VERSION "Version"

NS_ :

BS_:

BU_: IID IDC CCU Tester CCURT1 CCURT2 CCU3 CCU4 AVAS LCUFL LCUFR LCURL LCURR ZCUF ZCUL ZCUR ZCUT PADS MFS VDC ITS BCB IPS DCDC PCU EOP DCU BMC SRS EPS RBM IBCS AMP WHUD ADC RADARRR RADARRL RADARFR RADARFL RPC IFC RADARFRT RADARR HDMAP SBM WCM ETC TBOX DSM FLPDM FRPDM RLPDM RRPDM

BO_ 295 CCU_10: 64 CCU
 SG_ IL_IALFunctionCfgSt : 215|1@0+ (1,0) [0|1] ""  IDC
 SG_ IL_IALWorkSt : 214|1@0+ (1,0) [0|1] ""  IDC
 SG_ IL_IALBrightnessSetSt : 212|4@0+ (1,0) [0|15] ""  IDC
 SG_ IL_IALDriverModeCfgSt : 208|1@0+ (1,0) [0|1] ""  IDC
 SG_ IL_IALColorSetSt : 223|8@0+ (1,0) [0|255] ""  IDC
 SG_ IL_IALMusicModeCfgSt : 231|1@0+ (1,0) [0|1] ""  IDC
 SG_ IALVoiceModeCfgSt : 230|1@0+ (1,0) [0|1] ""  IDC

BO_ 400 CCU_MFS_1: 32 CCU
 SG_ UINM_DrvReqShft : 31|4@0+ (1,0) [0|15] ""  IDC
 SG_ UINM_TurnLightSwSt : 43|3@0+ (1,0) [0|7] ""  CCU,IDC
 SG_ UINM_FrontWiperSwSt : 55|3@0+ (1,0) [0|7] ""  CCU,IDC
 SG_ UINM_FrontWasherSwSt : 48|1@0+ (1,0) [0|1] ""  CCU,IDC

BO_ 615 CCU_BCS_1_C: 64 CCU
 SG_ BCS_1_C_Dummy20 : 48|1@0+ (1,0) [0|0] ""  IDC
 SG_ BCS_1_C_Dummy19 : 66|1@0+ (1,0) [0|0] ""  IDC
 SG_ BCS_RLWheelRotatedDirection : 65|1@0+ (1,0) [0|1] ""  ADC,IDC,IFC
 SG_ BCS_RLWheelSpd : 63|13@0+ (0.05625,0) [0|240] "km/h"  ADC,DCU,IDC,IFC,ZCUF,ZCUT
 SG_ BCS_1_C_Dummy14 : 34|1@0+ (1,0) [0|0] ""  IDC
 SG_ BCS_1_C_Dummy18 : 50|1@0+ (1,0) [0|0] ""  IDC
 SG_ BCS_1_C_Dummy17 : 32|1@0+ (1,0) [0|0] ""  IDC
 SG_ BCS_RRWheelSpdEdgesSum : 131|12@0+ (1,0) [0|4095] ""  ADC,IDC,IFC,ZCUF,ZCUT
 SG_ BCS_FRWheelSpdEdgesSum : 107|12@0+ (1,0) [0|4095] ""  ADC,IDC,IFC,ZCUF,ZCUT
 SG_ BCS_RRWheelRotatedDirection : 81|1@0+ (1,0) [0|1] ""  ADC,IDC,IFC
 SG_ BCS_RRWheelSpd : 79|13@0+ (0.05625,0) [0|240] "km/h"  ADC,DCU,IDC,IFC,ZCUF,ZCUT
 SG_ BCS_FRWheelRotatedDirection : 49|1@0+ (1,0) [0|1] ""  ADC,IDC,IFC
 SG_ BCS_FRWheelSpd : 47|13@0+ (0.05625,0) [0|240] "km/h"  ADC,DCU,IDC,IFC,ZCUF,ZCUT
 SG_ BCS_FLWheelRotatedDirection : 33|1@0+ (1,0) [0|1] ""  ADC,IDC,IFC
 SG_ BCS_FLWheelSpd : 31|13@0+ (0.05625,0) [0|240] "km/h"  ADC,DCU,IDC,IFC,ZCUF,ZCUT
 SG_ BCS_1_C_Dummy16 : 95|1@0+ (1,0) [0|0] ""  ADC,DCU,IDC,IFC,SBM,ZCUF,ZCUR,ZCUT
 SG_ BCS_1_C_Dummy10 : 64|1@0+ (1,0) [0|1] ""  ADC,DCU,IDC,IFC,SBM,ZCUF,ZCUR,ZCUT
 SG_ BCS_1_C_Dummy15 : 271|4@0+ (1,0) [0|0] ""  ADC,DCU,IDC,IFC,SBM,ZCUF,ZCUR,ZCUT
 SG_ BCS_1_C_Dummy13 : 80|1@0+ (1,0) [0|1] ""  ZCUF,ZCUT,ZCUR,DCU,SBM,ADC,IFC,IDC
 SG_ BCS_1_C_Dummy12 : 90|3@0+ (1,0) [0|0] ""  ZCUF,ZCUT,ZCUR,DCU,SBM,ADC,IFC,IDC
 SG_ BCS_1_C_Dummy11 : 82|1@0+ (1,0) [0|1] ""  ZCUF,ZCUT,ZCUR,DCU,SBM,ADC,IFC,IDC
 SG_ BCS_1_C_Dummy9 : 150|1@0+ (1,0) [0|0] ""  ZCUF,ZCUT,ZCUR,DCU,SBM,ADC,IFC,IDC
 SG_ BCS_1_C_Dummy8 : 148|5@0+ (1,0) [0|0] ""  ZCUF,ZCUT,ZCUR,DCU,SBM,ADC,IFC,IDC
 SG_ BCS_1_C_Dummy7 : 159|6@0+ (1,0) [0|0] ""  ZCUF,ZCUT,ZCUR,DCU,SBM,ADC,IFC,IDC
 SG_ BCS_1_C_Dummy6 : 164|41@0+ (1,0) [0|0] ""  ZCUF,ZCUT,ZCUR,DCU,SBM,ADC,IFC,IDC
 SG_ BCS_1_C_Dummy5 : 203|60@0+ (1,0) [0|1.15292150460685E+018] ""  ZCUF,ZCUT,ZCUR,DCU,SBM,ADC,IFC,IDC
 SG_ BCS_1_C_Dummy4 : 279|48@0+ (1,0) [0|0] ""  ZCUF,ZCUR,ZCUT,DCU,SBM,ADC,IFC,IDC
 SG_ BCS_1_C_Dummy3 : 327|64@0+ (1,0) [0|0] ""  ZCUF,ZCUR,ZCUT,SBM,DCU,ADC,IFC,IDC
 SG_ BCS_1_C_Dummy2 : 391|64@0+ (1,0) [0|0] ""  ZCUF,ZCUR,ZCUT,DCU,SBM,ADC,IFC,IDC
 SG_ BCS_1_C_Dummy1 : 455|64@0+ (1,0) [0|0] ""  ZCUT,ZCUF,ZCUR,DCU,SBM,ADC,IFC,IDC
 SG_ BCS_1_Counter : 23|8@0+ (1,0) [0|255] ""  ZCUF,ZCUT,IDC,ADC,IFC
 SG_ BCS_1_CRC : 7|16@0+ (1,0) [0|65535] ""  ZCUF,ZCUT,IDC,ADC,IFC
 SG_ BCS_FLWheelSpdEdgesSumVD : 151|1@0+ (1,0) [0|1] ""  IFC,IDC,ADC
 SG_ BCS_FLWheelSpdEdgesSum : 103|12@0+ (1,0) [0|4095] ""  ZCUF,ZCUT,IFC,IDC,ADC
 SG_ BCS_HHCErrSt : 94|1@0+ (1,0) [0|1] ""  IDC,IFC
 SG_ BCS_HDCCtrlSt : 93|2@0+ (1,0) [0|3] ""  DCU,IDC,ADC,IFC
 SG_ BCS_HDCErrSt : 91|1@0+ (1,0) [0|1] ""  IDC,ADC,IFC
 SG_ BCS_RLWheelSpdEdgesSum : 127|12@0+ (1,0) [0|4095] ""  ZCUF,ZCUT,IDC,ADC,IFC
 SG_ BCS_RLWheelSpdEdgesSumVD : 149|1@0+ (1,0) [0|1] ""  IDC,ADC,IFC
 SG_ BCS_VDCOff : 153|1@0+ (1,0) [0|1] ""  IDC,ADC,IFC
 SG_ BCS_AVHSt : 152|1@0+ (1,0) [0|1] ""  ZCUR,DCU,IDC,ADC,IFC,SBM
 SG_ BCS_AVHStandby : 167|1@0+ (1,0) [0|1] ""  IDC,IFC
 SG_ BCS_AVHAvailable : 166|1@0+ (1,0) [0|1] ""  IDC,IFC
 SG_ BCS_TCSOff : 165|1@0+ (1,0) [0|1] ""  IDC,ADC,IFC
 SG_ BCS_ESPFuncResp : 267|2@0+ (1,0) [0|3] ""  IDC
 SG_ BCS_HDCFuncResp : 265|2@0+ (1,0) [0|3] ""  IDC

BO_ 352 CCU_BCS_2_C: 64 CCU
 SG_ BCS_2_C_Dummy11 : 199|36@0+ (1,0) [0|0] ""  IDC
 SG_ IPB_BrakePedalSt : 227|2@0+ (1,0) [0|3] ""  ADC,IDC,IFC,ZCUF,ZCUT
 SG_ BCS_2_C_Dummy10 : 33|2@0+ (1,0) [0|0] ""  ITS,AMP,ZCUL,ZCUR,MFS,PCU,DCU,ZCUF,ZCUT,IDC,ADC,IFC
 SG_ BCS_2_C_Dummy9 : 46|1@0+ (1,0) [0|0] ""  ITS,AMP,ZCUL,ZCUR,MFS,PCU,DCU,ZCUF,ZCUT,IDC,ADC,IFC
 SG_ BCS_2_C_Dummy8 : 40|17@0+ (1,0) [0|0] ""  ITS,AMP,ZCUL,ZCUR,MFS,PCU,DCU,ZCUF,ZCUT,IDC,ADC,IFC
 SG_ BCS_2_C_Dummy7 : 71|64@0+ (1,0) [0|0] ""  ITS,AMP,ZCUL,ZCUR,MFS,PCU,DCU,ZCUF,ZCUT,IDC,ADC,IFC
 SG_ BCS_2_C_Dummy6 : 135|64@0+ (1,0) [0|0] ""  ITS,AMP,ZCUL,ZCUR,MFS,PCU,DCU,ZCUF,ZCUT,IDC,ADC,IFC
 SG_ BCS_2_C_Dummy5 : 225|26@0+ (1,0) [0|67108863] ""  ITS,AMP,ZCUL,ZCUR,MFS,PCU,DCU,ZCUF,ZCUT,IDC,ADC,IFC
 SG_ BCS_2_C_Dummy4 : 263|64@0+ (1,0) [0|0] ""  ITS,AMP,ZCUL,ZCUR,MFS,PCU,DCU,ZCUF,ZCUT,IDC,ADC,IFC
 SG_ BCS_2_C_Dummy3 : 327|64@0+ (1,0) [0|0] ""  ITS,AMP,ZCUL,ZCUR,MFS,PCU,DCU,ZCUF,ZCUT,IDC,ADC,IFC
 SG_ BCS_2_C_Dummy2 : 391|64@0+ (1,0) [0|0] ""  IDC,ITS,AMP,ZCUL,ZCUR,MFS,PCU,DCU,ZCUF,ZCUT,ADC,IFC
 SG_ BCS_2_C_Dummy1 : 455|64@0+ (1,0) [0|0] ""  ITS,AMP,ZCUL,ZCUR,MFS,PCU,DCU,ZCUF,ZCUT,IDC,ADC,IFC
 SG_ BCS_2_Counter : 23|8@0+ (1,0) [0|255] ""  ZCUF,ZCUL,ZCUR,ZCUT,DCU,IDC,ADC,IFC
 SG_ BCS_2_CRC : 7|16@0+ (1,0) [0|65535] ""  DCU,IDC,ZCUF,ZCUL,ZCUR,ZCUT,ADC,IFC
 SG_ BCS_VehSpd : 31|13@0+ (0.05625,0) [0|240] "km/h"  ITS,AMP,ZCUF,ZCUL,ZCUR,ZCUT,MFS,PCU,DCU,IDC,ADC,IFC
 SG_ BCS_VehSpdVD : 34|1@0+ (1,0) [0|1] ""  ZCUF,ZCUL,ZCUR,ZCUT,MFS,PCU,IDC,ADC,IFC
 SG_ BCS_EBDFaultSt : 47|1@0+ (1,0) [0|1] ""  ZCUF,ZCUT,IDC,ADC,IFC
 SG_ BCS_ABSFaultSt : 45|1@0+ (1,0) [0|1] ""  ZCUF,ZCUT,IDC,ADC,IFC
 SG_ BCS_TCSActiveSt : 44|1@0+ (1,0) [0|1] ""  ZCUF,ZCUT,DCU,IDC,ADC,IFC
 SG_ BCS_TCSFaultSt : 43|1@0+ (1,0) [0|1] ""  ZCUF,ZCUT,IDC,ADC,IFC
 SG_ BCS_VDCActiveSt : 42|1@0+ (1,0) [0|1] ""  ZCUF,ZCUT,IDC,ADC,IFC
 SG_ BCS_VDCFaultSt : 41|1@0+ (1,0) [0|1] ""  ZCUF,ZCUT,IDC,ADC,IFC

BO_ 611 CCU_BCS_3_C: 64 CCU
 SG_ IPB_BrkPedalModesetSt : 254|7@0+ (1,0) [0|100] ""  IDC
 SG_ BCS_3_C_Dummy10 : 31|54@0+ (1,0) [0|0] ""  IDC,IFC,ADC
 SG_ BCS_3_C_Dummy9 : 87|64@0+ (1,0) [0|1.84467440737096E+019] ""  IDC,IFC,ADC
 SG_ BCS_3_C_Dummy8 : 151|64@0+ (1,0) [0|0] ""  IFC,IDC,ADC
 SG_ BCS_3_C_Dummy7 : 215|20@0+ (1,0) [0|1048575] ""  IDC,IFC,ADC
 SG_ BCS_3_C_Dummy6 : 235|2@0+ (1,0) [0|0] ""  IFC,IDC,ADC
 SG_ BCS_3_C_Dummy5 : 244|6@0+ (1,0) [0|63] ""  IDC,IFC,ADC
 SG_ BCS_3_C_Dummy4 : 263|64@0+ (1,0) [0|0] ""  IFC,IDC,ADC
 SG_ BCS_3_C_Dummy3 : 327|64@0+ (1,0) [0|0] ""  IDC,IFC,ADC
 SG_ BCS_3_C_Dummy2 : 391|64@0+ (1,0) [0|0] ""  IFC,IDC,ADC
 SG_ BCS_3_C_Dummy1 : 455|64@0+ (1,0) [0|0] ""  IFC,IDC,ADC
 SG_ BCS_3_CRC : 7|16@0+ (1,0) [0|65535] ""  IDC
 SG_ BCS_3_Counter : 23|8@0+ (1,0) [0|255] ""  IDC
 SG_ IPB_BrkPedalModeCfgSt : 73|2@0+ (1,0) [0|3] ""  IDC
 SG_ IPB_InputRodStrokeSt : 227|1@0+ (1,0) [0|1] ""  IDC,ADC,IFC
 SG_ IBCS_SystemSt : 226|3@0+ (1,0) [0|7] ""  IDC,ADC,IFC
 SG_ IBCS_FWAWarning : 239|2@0+ (1,0) [0|3] ""  IDC
 SG_ IBCS_BrakeFluidWarning : 237|2@0+ (1,0) [0|3] ""  IDC
 SG_ IPB_CSTSt : 233|2@0+ (1,0) [0|3] ""  IDC
 SG_ IBCS_TwoFoot_DriveWarning : 247|1@0+ (1,0) [0|1] ""  IDC
 SG_ BCS_ESPMode : 246|2@0+ (1,0) [0|3] ""  IDC

BO_ 886 CCU_BCS_5_C: 32 CCU
 SG_ BCS_TPMSResetSt : 31|2@0+ (1,0) [0|3] ""  IDC
 SG_ BCS_TPMSWarningLamp : 29|1@0+ (1,0) [0|1] ""  IDC
 SG_ BCS_TPMSSysErrorSt : 28|1@0+ (1,0) [0|1] ""  IDC
 SG_ BCS_TPMSFLTyrePreWarn : 27|1@0+ (1,0) [0|1] ""  IDC
 SG_ BCS_TPMSFRTyrePreWarn : 26|1@0+ (1,0) [0|1] ""  IDC
 SG_ BCS_AVHSoftSwctrlst : 25|2@0+ (1,0) [0|3] ""  IDC
 SG_ BCS_TPMSRLTyrePreWarn : 39|1@0+ (1,0) [0|1] ""  IDC
 SG_ BCS_TPMSRRTyrePreWarn : 38|1@0+ (1,0) [0|1] ""  IDC

BO_ 618 CCU_EPB_1: 32 CCU
 SG_ EPB_DragMode : 123|2@0+ (1,0) [0|3] ""  IBCS,IDC,RBM,ZCUF
 SG_ EPB_1_Dummy6 : 31|3@0+ (1,0) [0|0] ""  ZCUF,ZCUR,SRS,ADC,RBM,IBCS,IDC
 SG_ EPB_1_Dummy5 : 33|18@0+ (1,0) [0|0] ""  ZCUF,ZCUR,SRS,ADC,RBM,IBCS,IDC
 SG_ EPB_1_Dummy4 : 63|64@0+ (1,0) [0|0] ""  ZCUF,ZCUR,SRS,ADC,RBM,IBCS,IDC
 SG_ EPB_1_Dummy3 : 121|6@0+ (1,0) [0|63] ""  ZCUF,ZCUR,SRS,ADC,RBM,IBCS,IDC
 SG_ EPB_1_Dummy2 : 129|58@0+ (1,0) [0|0] ""  ZCUF,ZCUR,SRS,ADC,RBM,IBCS,IDC
 SG_ EPB_1_Dummy1 : 199|64@0+ (1,0) [0|0] ""  ZCUF,ZCUR,SRS,ADC,RBM,IBCS,IDC
 SG_ EPB_1_CRC : 7|16@0+ (1,0) [0|65535] ""  ZCUF,ZCUR,RBM,IBCS,IDC,ADC
 SG_ EPB_1_Counter : 23|8@0+ (1,0) [0|255] ""  ZCUF,ZCUR,RBM,IBCS,IDC,ADC
 SG_ EPB_SysSt : 28|3@0+ (1,0) [0|7] ""  SRS,RBM,IBCS,IDC,ADC
 SG_ EPB_SysStIndReq : 25|2@0+ (1,0) [0|3] ""  RBM,IBCS,IDC
 SG_ EPB_FailSt : 39|1@0+ (1,0) [0|1] ""  SRS,RBM,IBCS,IDC,ADC
 SG_ EPB_SysWarnIndReq : 38|2@0+ (1,0) [0|3] ""  RBM,IBCS,IDC
 SG_ EPB_SysAudWarnReq : 36|3@0+ (1,0) [0|7] ""  RBM,IBCS,IDC
 SG_ EPB_SysDispMsgReq : 127|4@0+ (1,0) [0|15] ""  RBM,IBCS,IDC
 SG_ EPB_StpOnBrkToRelParkBrkIndOn : 131|2@0+ (1,0) [0|3] ""  IDC

BO_ 939 CCU_SRS_2: 32 CCU
 SG_ SRS_2_Dummy5 : 24|1@0+ (1,0) [0|0] ""  IDC
 SG_ SRS_2_Dummy4 : 35|28@0+ (1,0) [0|268435455] ""  IDC
 SG_ SRS_2_Dummy3 : 71|64@0+ (1,0) [0|0] ""  IDC
 SG_ SRS_2_Dummy2 : 135|64@0+ (1,0) [0|0] ""  IDC
 SG_ SRS_2_Dummy1 : 199|64@0+ (1,0) [0|0] ""  IDC
 SG_ SRS_2_CRC : 7|16@0+ (1,0) [0|65535] ""  IDC
 SG_ SRS_2_Counter : 23|8@0+ (1,0) [0|255] ""  IDC
 SG_ SRS_PsngrSeatBeltSt : 31|2@0+ (1,0) [0|3] ""  IDC
 SG_ SRS_DriverSeatBeltSt : 29|2@0+ (1,0) [0|3] ""  IDC
 SG_ SRS_RearLeftSeatBeltSt : 27|2@0+ (1,0) [0|3] ""  IDC
 SG_ SRS_AirbagFaultSt : 25|1@0+ (1,0) [0|1] ""  IDC
 SG_ SRS_RearRightSeatBeltSt : 39|2@0+ (1,0) [0|3] ""  IDC
 SG_ SRS_RearMiddleSeatBeltSt : 37|2@0+ (1,0) [0|3] ""  IDC

BO_ 368 CCU_DCU_1: 64 CCU
 SG_ DCU_TorqAct : 169|13@0+ (0.2,-819) [-819|819] "Nm"  CCU,CCURT1,VDC,IDC

BO_ 864 CCU_DCU_2: 64 CCU
 SG_ DCU_2_Dummy10 : 95|5@0+ (1,0) [0|0] ""  IDC
 SG_ DCU_SysTempOvrInd : 90|1@0+ (1,0) [0|1] ""  IDC
 SG_ DCU_2_Dummy9 : 31|64@0+ (1,0) [0|1.84467440737096E+019] ""  IDC
 SG_ DCU_2_Dummy8 : 89|15@0+ (1,0) [0|32767] ""  IDC
 SG_ DCU_2_Dummy7 : 105|17@0+ (1,0) [0|0] ""  IDC
 SG_ DCU_2_Dummy6 : 131|60@0+ (1,0) [0|0] ""  IDC
 SG_ DCU_2_Dummy5 : 199|64@0+ (1,0) [0|0] ""  IDC
 SG_ DCU_2_Dummy4 : 263|64@0+ (1,0) [0|0] ""  IDC
 SG_ DCU_2_Dummy3 : 327|64@0+ (1,0) [0|0] ""  IDC
 SG_ DCU_2_Dummy2 : 391|64@0+ (1,0) [0|0] ""  IDC
 SG_ DCU_2_Dummy1 : 455|64@0+ (1,0) [0|0] ""  IDC
 SG_ DCU_Err2NoticeFlag : 132|1@0+ (1,0) [0|1] ""  IDC
 SG_ DCU_ErrNotice : 135|3@0+ (1,0) [0|7] ""  IDC
 SG_ DCU_ErrNoticeOperationFlag : 120|1@0+ (1,0) [0|1] ""  IDC
 SG_ DCU_2_Counter : 23|8@0+ (1,0) [0|255] ""  IDC
 SG_ DCU_2_CRC : 7|16@0+ (1,0) [0|65535] ""  IDC
 SG_ DCU_FaultLampInd : 106|1@0+ (1,0) [0|1] ""  IDC

BO_ 872 CCU_IPS_2: 64 CCU
 SG_ IPS_2_Dummy10 : 73|2@0+ (1,0) [0|0] ""  IDC
 SG_ IPS_2_Dummy9 : 31|26@0+ (1,0) [0|0] ""  IDC
 SG_ IPS_2_Dummy8 : 52|27@0+ (1,0) [0|0] ""  IDC
 SG_ IPS_2_Dummy7 : 87|62@0+ (1,0) [0|4.61168601842739E+018] ""  IDC
 SG_ IPS_2_Dummy6 : 136|49@0+ (1,0) [0|0] ""  IDC
 SG_ IPS_2_Dummy5 : 196|61@0+ (1,0) [0|2.30584300921369E+018] ""  IDC
 SG_ IPS_2_Dummy4 : 263|64@0+ (1,0) [0|0] ""  IDC
 SG_ IPS_2_Dummy3 : 327|64@0+ (1,0) [0|0] ""  IDC
 SG_ IPS_2_Dummy2 : 391|64@0+ (1,0) [0|0] ""  IDC
 SG_ IPS_2_Dummy1 : 455|64@0+ (1,0) [0|0] ""  IDC
 SG_ IPS_OBCFaultLampIndOperationFlag : 197|1@0+ (1,0) [0|1] ""  IDC
 SG_ IPS_DCDCFaultLampIndFlag : 198|1@0+ (1,0) [0|1] ""  IDC
 SG_ IPS_DCDCFaultLampIndOperationFla : 199|1@0+ (1,0) [0|1] ""  IDC
 SG_ IPS_2_CRC : 7|16@0+ (1,0) [0|65535] ""  IDC
 SG_ IPS_2_Counter : 23|8@0+ (1,0) [0|255] ""  IDC
 SG_ IPS_DCDCFaultLampInd : 53|1@0+ (1,0) [0|1] ""  IDC
 SG_ IPS_OBCFaultLampInd : 137|1@0+ (1,0) [0|1] ""  IDC

BO_ 880 CCU_ITS_1: 64 CCU
 SG_ ITS_MotorPumpSt : 31|2@0+ (1,0) [0|3] ""  IDC,ADC
 SG_ ITS_FanStpSpdErr : 29|1@0+ (1,0) [0|1] ""  IDC
 SG_ ITS_HeaterPumpSt : 25|2@0+ (1,0) [0|3] ""  IDC
 SG_ ITS_EcvSt : 33|2@0+ (1,0) [0|3] ""  IDC
 SG_ ITS_BatteryPumpSt : 46|2@0+ (1,0) [0|3] ""  IDC
 SG_ ITS_MotorInletTempErr : 102|1@0+ (1,0) [0|1] ""  IDC
 SG_ ITS_BatteryInletTempErr : 101|1@0+ (1,0) [0|1] ""  IDC
 SG_ ITS_ChillerInletTempErr : 100|1@0+ (1,0) [0|1] ""  IDC
 SG_ ITS_SolenoidErr : 98|1@0+ (1,0) [0|1] ""  IDC

BO_ 824 VCU_2: 64 CCU
 SG_ VCU_2_Dummy32 : 136|1@0+ (1,0) [0|0] ""  IDC
 SG_ VCU_HVAC_PTCdelayEn : 33|1@0+ (1,0) [0|1] ""  CCURT2,IDC
 SG_ VCU_2_Dummy1 : 455|64@0+ (1,0) [0|0] ""  AMP,DCDC,EOP,IPS,ITS,ZCUF,ZCUT,BMC,ZCUR,ADC,IFC,SBM,TBOX,DCU,CCURT2,IDC
 SG_ VCU_2_Dummy30 : 32|1@0+ (1,0) [0|1] ""  AMP,DCDC,EOP,IPS,ITS,BMC,ZCUF,ZCUR,ZCUT,ADC,IFC,SBM,TBOX,DCU,CCURT2,IDC
 SG_ VCU_2_Dummy29 : 41|1@0+ (1,0) [0|0] ""  AMP,DCDC,EOP,IPS,ITS,BMC,ZCUF,ZCUR,ZCUT,ADC,IFC,SBM,DCU,TBOX,CCURT2,IDC
 SG_ VCU_2_Dummy28 : 49|2@0+ (1,0) [0|0] ""  AMP,DCDC,EOP,IPS,ITS,BMC,ZCUF,ZCUR,ZCUT,ADC,IFC,SBM,TBOX,DCU,CCURT2,IDC
 SG_ VCU_2_Dummy27 : 60|11@0+ (1,0) [0|0] ""  AMP,DCDC,EOP,IPS,ITS,BMC,ZCUF,ZCUR,ZCUT,ADC,IFC,SBM,TBOX,DCU,CCURT2,IDC
 SG_ VCU_2_Dummy26 : 75|8@0+ (1,0) [0|0] ""  AMP,DCDC,EOP,IPS,ITS,BMC,ZCUF,ZCUR,ZCUT,ADC,IFC,SBM,TBOX,DCU,CCURT2,IDC
 SG_ VCU_2_Dummy25 : 97|1@0+ (1,0) [0|0] ""  AMP,DCDC,EOP,IPS,ITS,BMC,ZCUF,ZCUR,ZCUT,ADC,IFC,SBM,DCU,TBOX,CCURT2,IDC
 SG_ VCU_2_Dummy24 : 122|5@0+ (1,0) [0|0] ""  BMC,AMP,DCDC,EOP,IPS,ITS,ZCUF,ZCUR,ZCUT,ADC,IFC,SBM,TBOX,DCU,CCURT2,IDC
 SG_ VCU_2_Dummy23 : 147|2@0+ (1,0) [0|3] ""  AMP,DCDC,EOP,IPS,ITS,BMC,ZCUF,ZCUR,ZCUT,ADC,IFC,SBM,TBOX,DCU,CCURT2,IDC
 SG_ VCU_2_Dummy22 : 163|1@0+ (1,0) [0|0] ""  AMP,DCDC,EOP,IPS,ITS,BMC,ZCUF,ZCUR,ZCUT,ADC,IFC,SBM,TBOX,DCU,CCURT2,IDC
 SG_ VCU_2_Dummy21 : 171|5@0+ (1,0) [0|0] ""  AMP,DCDC,EOP,IPS,ITS,BMC,ZCUF,ZCUR,ZCUT,ADC,IFC,SBM,TBOX,DCU,CCURT2,IDC
 SG_ VCU_2_Dummy20 : 196|3@0+ (1,0) [0|0] ""  AMP,DCDC,EOP,IPS,ITS,BMC,ZCUF,ZCUR,ZCUT,ADC,IFC,SBM,TBOX,DCU,CCURT2,IDC
 SG_ VCU_2_Dummy19 : 207|4@0+ (1,0) [0|0] ""  AMP,DCDC,EOP,IPS,ITS,BMC,ZCUF,ZCUR,ZCUT,ADC,IFC,SBM,TBOX,DCU,CCURT2,IDC
 SG_ VCU_2_Dummy18 : 208|1@0+ (1,0) [0|0] ""  AMP,DCDC,EOP,IPS,ITS,BMC,ZCUF,ZCUR,ZCUT,ADC,IFC,SBM,TBOX,DCU,CCURT2,IDC
 SG_ VCU_2_Dummy17 : 220|1@0+ (1,0) [0|0] ""  AMP,DCDC,EOP,IPS,ITS,BMC,ZCUF,ZCUR,ZCUT,ADC,IFC,SBM,TBOX,DCU,CCURT2,IDC
 SG_ VCU_2_Dummy16 : 216|3@0+ (1,0) [0|0] ""  AVAS,DCDC,EOP,IPS,ITS,BMC,ZCUF,ZCUR,ZCUT,ADC,IFC,SBM,TBOX,DCU,CCURT2,IDC
 SG_ VCU_2_Dummy15 : 226|3@0+ (1,0) [0|0] ""  AMP,DCDC,EOP,IPS,ITS,BMC,ZCUF,ZCUR,ZCUT,ADC,IFC,SBM,TBOX,DCU,CCURT2,IDC
 SG_ VCU_2_Dummy14 : 247|6@0+ (1,0) [0|0] ""  EOP,DCDC,AMP,IPS,ITS,BMC,ZCUF,ZCUR,ZCUT,ADC,IFC,SBM,TBOX,DCU,CCURT2,IDC
 SG_ VCU_2_Dummy13 : 260|1@0+ (1,0) [0|0] ""  AMP,DCDC,EOP,IPS,ITS,BMC,ZCUF,ZCUR,ZCUT,ADC,IFC,SBM,TBOX,DCU,CCURT2,IDC
 SG_ VCU_2_Dummy12 : 279|3@0+ (1,0) [0|0] ""  AMP,DCDC,EOP,IPS,ITS,ZCUF,ZCUT,BMC,ZCUR,ADC,IFC,SBM,TBOX,DCU,CCURT2,IDC
 SG_ VCU_2_Dummy31 : 63|3@0+ (1,0) [0|0] ""  AMP,DCDC,EOP,IPS,ITS,BMC,ZCUF,ZCUR,ZCUT,ADC,IFC,SBM,TBOX,DCU,CCURT2,IDC
 SG_ VCU_2_Dummy11 : 274|9@0+ (1,0) [0|0] ""  AMP,DCDC,EOP,IPS,ITS,ZCUF,ZCUT,BMC,ZCUR,ADC,IFC,SBM,TBOX,DCU,CCURT2,IDC
 SG_ VCU_2_Dummy10 : 295|19@0+ (1,0) [0|0] ""  AMP,DCDC,EOP,IPS,ITS,ZCUF,ZCUT,BMC,ZCUR,ADC,IFC,SBM,TBOX,DCU,CCURT2,IDC
 SG_ VCU_2_Dummy9 : 313|37@0+ (1,0) [0|0] ""  AMP,DCDC,EOP,IPS,ITS,BMC,ZCUF,ZCUR,ZCUT,ADC,IFC,SBM,TBOX,DCU,CCURT2,IDC
 SG_ VCU_2_Dummy8 : 354|1@0+ (1,0) [0|0] ""  AMP,DCDC,EOP,IPS,ITS,BMC,ZCUF,ZCUR,ZCUT,ADC,IFC,SBM,TBOX,DCU,CCURT2,IDC
 SG_ VCU_2_Dummy7 : 352|6@0+ (1,0) [0|0] ""  AMP,DCDC,EOP,IPS,ITS,BMC,ZCUF,ZCUR,ZCUT,ADC,IFC,SBM,TBOX,DCU,CCURT2,IDC
 SG_ VCU_2_Dummy6 : 375|9@0+ (1,0) [0|0] ""  AMP,DCDC,EOP,IPS,ITS,BMC,ZCUF,ZCUR,ZCUT,ADC,IFC,SBM,TBOX,DCU,CCURT2,IDC
 SG_ VCU_2_Dummy5 : 381|3@0+ (1,0) [0|0] ""  AMP,DCDC,EOP,IPS,ITS,BMC,ZCUF,ZCUR,ZCUT,ADC,IFC,SBM,TBOX,DCU,CCURT2,IDC
 SG_ VCU_2_Dummy4 : 398|6@0+ (1,0) [0|0] ""  AMP,DCDC,EOP,IPS,ITS,BMC,ZCUF,ZCUR,ZCUT,ADC,IFC,SBM,TBOX,DCU,CCURT2,IDC
 SG_ VCU_2_Dummy3 : 406|10@0+ (1,0) [0|0] ""  AMP,DCDC,EOP,IPS,ITS,BMC,ZCUF,ZCUR,ZCUT,ADC,IFC,SBM,TBOX,DCU,CCURT2,IDC
 SG_ VCU_2_Dummy2 : 419|26@0+ (1,0) [0|0] ""  AMP,DCDC,EOP,IPS,ITS,BMC,ZCUF,ZCUR,ZCUT,ADC,IFC,SBM,TBOX,DCU,CCURT2,IDC
 SG_ VCU_2_CRC : 7|16@0+ (1,0) [0|65535] ""  CCURT2,ZCUF,ZCUT,IDC,ADC,BMC,DCU,IFC
 SG_ VCU_2_Counter : 23|8@0+ (1,0) [0|255] ""  CCURT2,ZCUF,ZCUT,IDC,ADC,BMC,DCU,IFC
 SG_ VCU_LongDistResp : 441|2@0+ (1,0) [0|3] ""  IDC
 SG_ VCU_SwapHvBattModeStVD : 353|1@0+ (1,0) [0|1] ""  ADC,AMP,BMC,DCDC,DCU,EOP,IDC,IPS,ITS,SBM,TBOX,ZCUF,ZCUR,ZCUT
 SG_ VCU_SwapHvBattModeSt : 356|2@0+ (1,0) [0|3] ""  ADC,AMP,BMC,DCDC,DCU,EOP,IDC,IPS,ITS,SBM,TBOX,ZCUF,ZCUR,ZCUT
 SG_ VCU_WarmTimeNotice : 37|1@0+ (1,0) [0|1] ""  IDC
 SG_ VCU_VehElcConspInst : 31|10@0+ (0.1,0) [0|102.3] "kWh/100km"  IDC
 SG_ VCU_DischgSt : 36|2@0+ (1,0) [0|3] ""  CCURT2,IDC
 SG_ VCU_DischgAvai : 34|1@0+ (1,0) [0|1] ""  CCURT2,IDC
 SG_ VCU_WarmTimeCfgResp : 45|4@0+ (1,0) [0|15] ""  CCURT2,IDC
 SG_ VCU_WarmSt : 47|2@0+ (1,0) [0|3] ""  CCURT2,IDC
 SG_ VCU_CreepAvail : 40|1@0+ (1,0) [0|1] ""  CCURT2,IDC
 SG_ VCU_GearLvlDisp : 53|4@0+ (1,0) [0|15] ""  ZCUF,ZCUT,CCURT2,ZCUR,IDC,SBM
 SG_ VCU_RecpLevelAvail : 55|2@0+ (1,0) [0|3] ""  CCURT2,IDC
 SG_ VCU_IpedalModeAvail : 65|1@0+ (1,0) [0|1] ""  CCURT2,IDC
 SG_ VCU_ElcSysFault : 64|5@0+ (1,0) [0|31] ""  CCURT2,IDC
 SG_ VCU_DspChgSt : 83|2@0+ (1,0) [0|3] ""  CCURT2,IDC
 SG_ VCU_DspDischgSt : 81|2@0+ (1,0) [0|3] ""  CCURT2,IDC
 SG_ VCU_SOCDynamicDspSt : 95|2@0+ (1,0) [0|3] ""  CCURT2,IDC
 SG_ VCU_DspChgVolt : 93|10@0+ (1,0) [0|1023] "V"  CCURT2,IDC
 SG_ VCU_BookChgLampInd : 99|2@0+ (1,0) [0|3] ""  CCURT2,IDC
 SG_ VCU_DspChgCurr : 96|12@0+ (0.1,0) [0|409.5] "A"  CCURT2,IDC
 SG_ VCU_DspDischgVolt : 116|10@0+ (1,0) [0|1023] "V"  CCURT2,IDC
 SG_ VCU_EcoPlusModeAvail : 133|1@0+ (1,0) [0|1] ""  CCURT2,IDC
 SG_ VCU_DspDischgCurr : 132|12@0+ (0.1,0) [0|409.5] "A"  CCURT2,IDC
 SG_ VCU_DriverNoticeDisp : 151|4@0+ (1,0) [0|15] ""  CCURT2,IDC
 SG_ VCU_DrvChgDchgDsp : 145|2@0+ (1,0) [0|3] ""  CCURT2,BMC,IDC
 SG_ VCU_CruExitNotice : 159|2@0+ (1,0) [0|3] ""  CCURT2,IDC
 SG_ VCU_DischgEndVehRng : 157|10@0+ (1,0) [0|1000] "km"  CCURT2,IDC
 SG_ VCU_DischgSocResp : 162|7@0+ (1,0) [0|100] "%"  CCURT2,IDC
 SG_ VCU_VehElcConspAvg : 182|9@0+ (0.1,0) [0|51.1] "kWh/100km"  IDC
 SG_ VCU_VehElcConspAccumAvg : 189|9@0+ (0.1,0) [0|51.1] "kWh/100km"  CCURT2,IDC
 SG_ VCU_GearLvlBlink : 193|1@0+ (1,0) [0|1] ""  CCURT2,IDC
 SG_ VCU_EcoModeAvail : 192|1@0+ (1,0) [0|1] ""  CCURT2,IDC
 SG_ VCU_PGearErrNotice : 203|2@0+ (1,0) [0|3] ""  CCURT2,IDC
 SG_ VCU_VehCrusSt : 201|2@0+ (1,0) [0|3] ""  CCURT2,IDC
 SG_ VCU_PwrFlowMode : 215|5@0+ (1,0) [0|31] ""  CCURT2,IDC
 SG_ VCU_FaultLampInd : 210|2@0+ (1,0) [0|3] ""  CCURT2,IDC
 SG_ VCU_VehDrvMod : 223|3@0+ (1,0) [0|7] ""  BMC,IDC,ADC,IFC
 SG_ VCU_ARBWarnNotice : 219|1@0+ (1,0) [0|1] ""  CCURT2,IDC
 SG_ VCU_BuzReq : 218|1@0+ (1,0) [0|1] ""  CCURT2,IDC
 SG_ VCU_VehRdySt : 217|1@0+ (1,0) [0|1] ""  CCURT2,ZCUR,IDC,ADC,IFC,SBM,TBOX
 SG_ VCU_ICMSpdLimitNotice : 229|3@0+ (1,0) [0|7] ""  CCURT2,IDC
 SG_ VCU_VehCrusTgtSpd : 239|8@0+ (1,0) [0|255] "km/h"  CCURT2,IDC
 SG_ VCU_PrecResHotMsg : 241|2@0+ (1,0) [0|3] ""  CCURT2,IDC
 SG_ VCU_VehChgDischgSt : 255|8@0+ (1,0) [0|255] ""  CCURT2,IDC
 SG_ VCU_ChgTimeDspType : 263|3@0+ (1,0) [0|7] ""  CCURT2,IDC
 SG_ VCU_ThermalMsgWarn : 316|3@0+ (1,0) [0|7] ""  CCURT2,IDC
 SG_ VCU_VehAvailDriveStMsgWarn : 259|1@0+ (1,0) [0|1] ""  CCURT2,IDC
 SG_ VCU_DerateLampSt : 258|2@0+ (1,0) [0|3] ""  CCURT2,IDC
 SG_ VCU_PlgConnSt : 256|1@0+ (1,0) [0|1] ""  CCURT2,DCU,IDC
 SG_ VCU_VehPwrDisp : 271|8@0+ (1,0) [0|100] "%"  CCURT2,IDC
 SG_ VCU_DischgSetInfo : 276|2@0+ (1,0) [0|3] ""  CCURT2,IDC
 SG_ VCU_ChgPlugRelSt : 281|2@0+ (1,0) [0|3] ""  IDC
 SG_ VCU_IDC_VehSwapModIntf : 308|4@0+ (1,0) [0|16] "-"  IDC
 SG_ VCU_IDC_VehSwapModReq : 304|1@0+ (1,0) [0|1] ""  IDC
 SG_ VCU_IDC_VehSwapModResp : 319|2@0+ (1,0) [0|3] "-"  IDC
 SG_ VCU_IDC_VehSwapModAvai : 317|1@0+ (1,0) [0|1] "-"  IDC
 SG_ VCU_RecpLevelstResp : 362|3@0+ (1,0) [0|7] ""  CCURT2,IDC
 SG_ VCU_VehRngUndrWarn : 382|1@0+ (1,0) [0|1] ""  IDC
 SG_ VCU_VehRng : 378|10@0+ (1,0) [0|1000] "km"  CCURT2,IDC
 SG_ VCU_IpedalCreepCfgResp : 384|2@0+ (1,0) [0|3] ""  CCURT2,IDC
 SG_ VCU_BattSocUndrWarn : 392|2@0+ (1,0) [0|3] ""  CCURT2,IDC
 SG_ VCU_VehPwr : 412|9@0+ (1,-160) [-160|300] "KW"  CCURT2,IDC

BO_ 952 VCU_3: 64 CCU
 SG_ VCU_AccurRngConspAccumAvg : 320|9@0+ (0.1,0) [0|51.1] "kWh/100km"  CCURT2,IDC
 SG_ VCU_AccurHMIModeCmd : 347|2@0+ (1,0) [0|3] ""  CCURT2,IDC
 SG_ VCU_AccurRngAvail : 312|1@0+ (1,0) [0|1] ""  CCURT2,IDC
 SG_ VCU_EcoPlusMod : 351|2@0+ (1,0) [0|3] ""  CCURT2,IDC
 SG_ VCU_ChgButtonStDsp : 262|3@0+ (1,0) [0|7] ""  IDC
 SG_ VCU_3_Dummy14 : 336|1@0+ (1,0) [0|1] ""  IDC
 SG_ VCU_RecpLevelstRespL : 343|7@0+ (1,0) [0|102] "%"  CCURT2,IDC
 SG_ VCU_3_Dummy13 : 125|6@0+ (1,0) [0|0] ""  TBOX,CCURT2,ITS,DCU,BMC,IDC
 SG_ VCU_3_Dummy12 : 231|2@0+ (1,0) [0|0] ""  BMC,CCURT2,DCU,IDC,ITS,TBOX
 SG_ VCU_3_Dummy11 : 31|18@0+ (1,0) [0|0] ""  BMC,DCU,ITS,CCURT2,IDC,TBOX
 SG_ VCU_3_Dummy10 : 63|51@0+ (1,0) [0|0] ""  BMC,DCU,ITS,CCURT2,IDC,TBOX
 SG_ VCU_3_Dummy9 : 135|34@0+ (1,0) [0|0] ""  BMC,DCU,ITS,CCURT2,IDC,TBOX
 SG_ VCU_3_Dummy8 : 165|62@0+ (1,0) [0|4.61168601842739E+018] ""  BMC,DCU,ITS,CCURT2,IDC,TBOX
 SG_ VCU_3_Dummy7 : 226|11@0+ (1,0) [0|0] ""  BMC,DCU,ITS,CCURT2,IDC,TBOX
 SG_ VCU_3_Dummy6 : 255|3@0+ (1,0) [0|0] ""  BMC,DCU,ITS,CCURT2,IDC,TBOX
 SG_ VCU_3_Dummy5 : 259|59@0+ (1,0) [0|5.76460752303423E+017] ""  BMC,DCU,ITS,CCURT2,IDC,TBOX
 SG_ VCU_3_Dummy3 : 345|34@0+ (1,0) [0|17179869183] ""  BMC,DCU,ITS,CCURT2,IDC,TBOX
 SG_ VCU_3_Dummy2 : 391|64@0+ (1,0) [0|0] ""  BMC,DCU,ITS,CCURT2,IDC,TBOX
 SG_ VCU_3_Dummy1 : 455|64@0+ (1,0) [0|0] ""  BMC,DCU,ITS,CCURT2,IDC,TBOX
 SG_ VCU_AccurRngCmd : 349|2@0+ (1,0) [0|0] ""  CCURT2,IDC
 SG_ VCU_DspChgCurrKA : 45|14@0+ (0.1,0) [0|1638.3] "A"  IDC
 SG_ VCU_AccPdlLvlResp : 327|7@0+ (1,0) [0|101] "%"  CCURT2,IDC
 SG_ VCU_Err2NoticeFlag : 263|1@0+ (1,0) [0|1] ""  IDC
 SG_ VCU_ErrNoticeOperationFlag : 248|1@0+ (1,0) [0|1] ""  IDC
 SG_ VCU_ErrNotice : 251|3@0+ (1,0) [0|7] ""  IDC
 SG_ VCU_ThermalMsgWarnOperationFlag : 252|1@0+ (1,0) [0|1] ""  IDC
 SG_ VCU_HVAPUTotalPwrAct : 108|15@0+ (10,0) [0|327650] "W"  CCURT2,IDC
 SG_ VCU_3_CRC : 7|16@0+ (1,0) [0|65535] ""  BMC,CCURT2,DCU,IDC,ITS
 SG_ VCU_3_Counter : 23|8@0+ (1,0) [0|255] ""  BMC,CCURT2,DCU,IDC,ITS
 SG_ VCU_BattCapColorEff : 229|3@0+ (1,0) [0|7] ""  CCURT2,IDC
 SG_ VCU_EMS_AccPedalActPst_Disp : 247|8@0+ (0.392,0) [0|99.96] "%"  CCURT2,IDC,TBOX

BO_ 812 BMS_3: 64 CCU
 SG_ BMS_Err2NoticeFlag : 193|1@0+ (1,0) [0|1] ""  IDC
 SG_ BMS_ErrNoticeOperationFlag : 194|1@0+ (1,0) [0|1] ""  IDC
 SG_ BMS_ErrNotice : 197|3@0+ (1,0) [0|7] ""  IDC
 SG_ BMS_BattSocDisp1 : 7|14@0+ (1,0) [0|0] "" Vector__XXX
 SG_ BMS_ChgSocSt : 394|2@0+ (1,0) [0|0] "" Vector__XXX
 SG_ BMS_BattSocDisp : 131|10@0+ (0.1,0) [0|100] "%"  CCURT2,BMC,IDC
 SG_ BMS_FaultLampInd : 150|1@0+ (1,0) [0|1] ""  CCURT2,IDC
 SG_ BMS_ChgSOCRespAvail : 161|1@0+ (1,0) [0|1] ""  BMC,IDC
 SG_ BMS_ChgSOCResp : 175|4@0+ (1,0) [0|15] ""  BMC,IDC
 SG_ BMS_ChgComplRemHour : 126|5@0+ (1,0) [0|31] "h"  CCURT2,BMC,IDC
 SG_ BMS_ChgComplRemMinute : 121|6@0+ (1,0) [0|59] "min"  CCURT2,BMC,IDC
 SG_ BMS_ChgmodeSt : 398|2@0+ (1,0) [0|3] ""  IDC
 SG_ BMS_ChgmodeAvail : 396|2@0+ (1,0) [0|3] ""  IDC

BO_ 408 CCU_BMC_1: 64 CCU
 SG_ BMC_HVBattSt : 60|4@0+ (1,0) [0|15] ""  IDC
 SG_ BMC_BattCurr : 24|16@0+ (0.1,-1000) [-1000|1000] "A"  DCU,IDC
 SG_ BMC_BattVolt : 54|10@0+ (1,0) [0|1000] "V"  DCU,IDC
 SG_ BMC_ThermalRunawayErr : 234|4@0+ (1,0) [0|1] ""  DCU,IDC
 SG_ BMC_LvPwrSysMsgWarn : 246|1@0+ (1,0) [0|1] ""  DCU,IDC

BO_ 888 CCU_BMC_2: 64 CCU
 SG_ BMC_HVBattElec : 183|1@0+ (0.1,0) [0|204.7] "kwh"  IDC
 SG_ BMC_BattSoe : 75|10@0+ (0.1,0) [0|100] "kwh"  IDC,TBOX
 SG_ BMC_HealCheckNotice : 165|1@0+ (1,0) [0|1] ""  IDC
 SG_ BMC_ChgFulNotice : 163|2@0+ (1,0) [0|3] ""  IDC
 SG_ BMC_InslStChkMsgWarn : 182|2@0+ (1,0) [0|3] ""  IDC

BO_ 1835 IDC_Phys_Diag_Rx: 64 Tester
 SG_ IDC_Diag_Request : 7|64@0+ (1,0) [0|0] ""  IDC

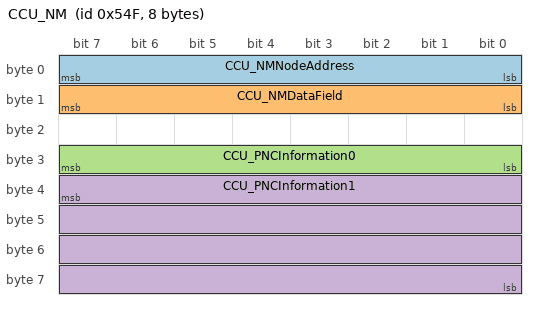
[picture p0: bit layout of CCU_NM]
BO_ 1359 CCU_NM: 8 CCU
 SG_ CCU_NMNodeAddress : 7|8@0+ (1,0) [0|255] ""  CCURT1,ZCUF,ZCUL,ZCUR,ZCUT,ITS,BCB,IPS,PCU,DCU,BMC,RBM,IBCS,IDC,ADC,IFC,TBOX
 SG_ CCU_NMDataField : 15|8@0+ (1,0) [0|0] ""  CCURT1,ZCUF,ZCUL,ZCUR,ZCUT,ITS,BCB,IPS,DCDC,PCU,DCU,BMC,RBM,IBCS,IDC,ADC,IFC,TBOX
 SG_ CCU_PNCInformation0 : 31|8@0+ (1,0) [0|255] ""  CCURT1,ZCUF,ZCUL,ZCUR,ZCUT,ITS,BCB,IPS,DCDC,PCU,DCU,BMC,RBM,IBCS,IDC,ADC,IFC,TBOX
 SG_ CCU_PNCInformation1 : 39|32@0+ (1,0) [0|0] ""  CCURT1,ZCUF,ZCUL,ZCUR,ZCUT,ITS,BCB,IPS,PCU,DCU,BMC,RBM,IBCS,IDC,ADC,IFC,TBOX

BO_ 2015 Fun_Diag_Rx: 64 Tester
 SG_ Fun_Diag_Request : 7|512@0+ (1,0) [0|0] ""  CCU,CCURT1,CCURT2,CCU3,CCU4,AVAS,LCUFL,LCUFR,LCURL,LCURR,ZCUF,ZCUL,ZCUR,ZCUT,PADS,MFS,ITS,BCB,IPS,DCDC,PCU,EOP,DCU,BMC,SRS,EPS,RBM,IBCS,IDC,AMP,WHUD,ADC,RADARRR,RADARRL,RADARFR,RADARFL,RPC,IFC,RADARFRT,RADARR,HDMAP,SBM,WCM,ETC,TBOX,DSM,FLPDM,FRPDM,RLPDM,RRPDM,Tester

BO_ 512 CCU_ZCUR_SBM_2: 64 CCU
 SG_ KAE_phone_Number : 471|48@0+ (1,0) [0|1] ""  IDC
 SG_ KAE_KeyToken : 71|32@0+ (1,0) [0|1] ""  IDC

BO_ 403 CCU_ADC_1: 64 CCU
 SG_ ADC_ICMADASFailureLamp : 244|2@0+ (1,0) [0|3] ""  IDC
 SG_ ADC_1_Dummy11 : 27|18@0+ (1,0) [0|0] ""  ETC,TBOX,IDC
 SG_ ADC_1_Dummy10 : 55|6@0+ (1,0) [0|0] ""  ETC,TBOX,IDC
 SG_ ADC_1_Dummy9 : 63|24@0+ (1,0) [0|0] ""  ETC,TBOX,IDC
 SG_ ADC_1_Dummy8 : 84|13@0+ (1,0) [0|0] ""  ETC,TBOX,IDC
 SG_ ADC_1_Dummy7 : 101|59@0+ (1,0) [0|0] ""  ETC,TBOX,IDC
 SG_ ADC_1_Dummy6 : 167|16@0+ (1,0) [0|0] ""  ETC,TBOX,IDC
 SG_ ADC_1_Dummy5 : 242|11@0+ (1,0) [0|2047] ""  ETC,TBOX,IDC
 SG_ ADC_1_Dummy4 : 263|64@0+ (1,0) [0|0] ""  ETC,TBOX,IDC
 SG_ ADC_1_Dummy3 : 327|64@0+ (1,0) [0|0] ""  ETC,TBOX,IDC
 SG_ ADC_1_Dummy2 : 391|64@0+ (1,0) [0|0] ""  ETC,TBOX,IDC
 SG_ ADC_1_Dummy1 : 455|64@0+ (1,0) [0|0] ""  ETC,TBOX,IDC
 SG_ ADC_HFIconColor : 154|3@0+ (1,0) [0|7] ""  IDC
 SG_ ADC_1_CRC : 7|16@0+ (1,0) [0|65535] ""  IDC
 SG_ ADC_1_Counter : 23|8@0+ (1,0) [0|255] ""  IDC
 SG_ ADC_ACCMode : 31|4@0+ (1,0) [0|15] ""  IDC,TBOX
 SG_ ADC_ISLC_ConfirmSt : 41|2@0+ (1,0) [0|3] ""  IDC
 SG_ ADC_ACCTakeOverReq : 49|1@0+ (1,0) [0|1] ""  IDC,ETC,TBOX
 SG_ ADC_ISLCSt : 48|1@0+ (1,0) [0|1] ""  IDC,ETC,TBOX
 SG_ ADC_TimeGapSet : 87|3@0+ (1,0) [0|7] ""  IDC,TBOX
 SG_ ADC_ILC_EnableSt : 103|1@0+ (1,0) [0|1] ""  IDC,TBOX
 SG_ ADC_ILOA_EnableSt : 102|1@0+ (1,0) [0|1] ""  IDC,TBOX
 SG_ ADC_ICMADASFailureText : 183|8@0+ (1,0) [0|255] ""  IDC
 SG_ ADC_ICMADASWarnText : 191|5@0+ (1,0) [0|31] ""  IDC
 SG_ ADC_SpeedLimitIconSt : 186|3@0+ (1,0) [0|7] ""  IDC
 SG_ ADC_ICMWarnCardSt : 199|5@0+ (1,0) [0|31] ""  IDC
 SG_ ADC_ICAIconColor : 194|3@0+ (1,0) [0|7] ""  IDC
 SG_ ADC_ICMPromptWarn : 207|5@0+ (1,0) [0|31] ""  IDC
 SG_ ADC_NDAIconColor : 202|3@0+ (1,0) [0|7] ""  IDC
 SG_ ADC_ACUVoiceWarn : 215|5@0+ (1,0) [0|31] ""  IDC
 SG_ ADC_NDAStateIcon : 210|3@0+ (1,0) [0|7] ""  IDC
 SG_ ADC_SpeedLimitIcon : 223|8@0+ (1,0) [0|255] "km/h"  IDC
 SG_ ADC_ICANDAIconAngle : 231|8@0+ (2,-180) [-180|180] "degree"  IDC
 SG_ ADC_ACCTargetSpeedCard : 239|8@0+ (1,0) [0|255] "km/h"  IDC
 SG_ ADC_ACCIconColor : 247|3@0+ (1,0) [0|7] ""  IDC

BO_ 411 CCU_ADC_2: 64 CCU
 SG_ ADC_RCTAWarnRight : 183|2@0+ (1,0) [0|3] ""  IDC
 SG_ ADC_RCTAWarnLeft : 170|2@0+ (1,0) [0|3] ""  IDC
 SG_ ADC_FCWAssistType : 31|2@0+ (1,0) [0|3] ""  IDC,TBOX
 SG_ ADC_FCWFaultSt : 29|1@0+ (1,0) [0|1] ""  IDC,TBOX
 SG_ ADC_FCWPreWarn : 28|2@0+ (1,0) [0|3] ""  IDC,TBOX
 SG_ ADC_FCWLatentWarn : 26|2@0+ (1,0) [0|3] ""  IDC,TBOX
 SG_ ADC_FCWWarmDistance : 37|2@0+ (1,0) [0|3] ""  IDC,TBOX
 SG_ ADC_AEBTarObjType : 35|4@0+ (1,0) [0|15] ""  IDC,TBOX
 SG_ ADC_AEBInterventionSt : 47|1@0+ (1,0) [0|1] ""  IDC,TBOX
 SG_ ADC_DOWAudioWarnFR : 143|2@0+ (1,0) [0|3] ""  IDC
 SG_ ADC_DOWAudioWarnFL : 141|2@0+ (1,0) [0|3] ""  IDC
 SG_ ADC_DOWAudioWarnRR : 139|2@0+ (1,0) [0|3] ""  IDC
 SG_ ADC_DOWAudioWarnRL : 137|2@0+ (1,0) [0|3] ""  IDC
 SG_ ADC_DOWIALWarnFR : 151|2@0+ (1,0) [0|3] ""  IDC
 SG_ ADC_DOWIALWarnRR : 147|2@0+ (1,0) [0|3] ""  IDC
 SG_ ADC_BSDLCASt : 153|2@0+ (1,0) [0|3] ""  IDC,TBOX
 SG_ ADC_RCTASt : 165|2@0+ (1,0) [0|3] ""  IDC,TBOX
 SG_ ADC_RCTAAssistType : 163|2@0+ (1,0) [0|3] ""  IDC,TBOX
 SG_ ADC_DOWSt : 161|2@0+ (1,0) [0|3] ""  IDC,TBOX
 SG_ ADC_RCWSt : 181|2@0+ (1,0) [0|3] ""  IDC,TBOX
 SG_ ADC_FCTASt : 191|2@0+ (1,0) [0|3] ""  IDC,TBOX
 SG_ ADC_FCTAAssistType : 189|2@0+ (1,0) [0|3] ""  IDC,TBOX
 SG_ ADC_FCTAWarnL : 187|2@0+ (1,0) [0|3] ""  IDC,TBOX
 SG_ ADC_FCTAWarnR : 185|2@0+ (1,0) [0|3] ""  IDC,TBOX
 SG_ ADC_LDS_LaneAssistType : 239|2@0+ (1,0) [0|3] ""  IDC,TBOX
 SG_ ADC_IHBC_EnableSt : 237|1@0+ (1,0) [0|1] ""  IDC,TBOX
 SG_ ADC_TSR_EnableSt : 236|1@0+ (1,0) [0|1] ""  IDC,TBOX
 SG_ ADC_TSR__AudioWarn_EnableSt : 235|1@0+ (1,0) [0|1] ""  IDC,TBOX
 SG_ ADC_ELK_EnableSt : 234|1@0+ (1,0) [0|1] ""  IDC,TBOX
 SG_ ADC_ESA_EnableSt : 233|1@0+ (1,0) [0|1] ""  IDC,TBOX
 SG_ ADC_AES_EnableSt : 232|1@0+ (1,0) [0|1] ""  IDC,TBOX
 SG_ ADC_TSR_SpdLimit : 324|5@0+ (1,0) [0|31] ""  IDC,TBOX
 SG_ ADC_TSR_SpdLimitUnit : 370|2@0+ (1,0) [0|3] ""  IDC,TBOX

BO_ 419 CCU_ADC_4: 64 CCU
 SG_ ADC_AssistParaSwitchReq : 71|1@0+ (1,0) [0|1] ""  EPS,IDC,IFC
 SG_ ADC_AEBFaultSt : 263|1@0+ (1,0) [0|1] ""  ZCUF,ZCUT,SRS,RBM,IDC,IFC,TBOX
 SG_ ADC_AEBOffSt : 262|1@0+ (1,0) [0|1] ""  SRS,IDC,IFC,TBOX
 SG_ ADC_AEBInterventionSt : 261|1@0+ (1,0) [0|1] ""  SRS,IDC,IFC,TBOX
 SG_ ADC_4_FreshnessValue : 455|16@0+ (1,0) [0|255] ""  IDC
 SG_ ADC_4_MAC_Check : 471|48@0+ (1,0) [0|255] ""  IDC

BO_ 404 CCU_ADC_1_B: 64 CCU
 SG_ ADC_ICMWarnCardSt_B : 68|4@0+ (1,0) [0|15] ""  CCU,IDC,TBOX
 SG_ ADC_ICMPromptWarn_B : 64|1@0+ (1,0) [0|1] ""  CCU,IDC,TBOX
 SG_ ADC_1_B_FreshnessValue : 455|16@0+ (1,0) [0|255] ""  CCU,IDC,TBOX
 SG_ ADC_1_B_MAC_Check : 471|48@0+ (1,0) [0|255] ""  CCU,IDC,TBOX

BO_ 437 CCU_IFC_1: 64 CCU
 SG_ CCU_IFC_1_Dummy11 : 51|12@0+ (1,0) [0|0] ""  IBCS,ADC,EPS,IDC,RBM
 SG_ CCU_IFC_1_Dummy10 : 71|64@0+ (1,0) [0|0] ""  ADC,EPS,IBCS,IDC,RBM
 SG_ CCU_IFC_1_Dummy9 : 135|64@0+ (1,0) [0|0] ""  ADC,EPS,IBCS,IDC,RBM
 SG_ CCU_IFC_1_Dummy8 : 199|64@0+ (1,0) [0|0] ""  ADC,EPS,IBCS,IDC,RBM
 SG_ CCU_IFC_1_Dummy7 : 263|64@0+ (1,0) [0|0] ""  ADC,EPS,IBCS,IDC,RBM
 SG_ CCU_IFC_1_Dummy6 : 327|64@0+ (1,0) [0|0] ""  ADC,EPS,IBCS,IDC,RBM
 SG_ CCU_IFC_1_Dummy5 : 391|64@0+ (1,0) [0|0] ""  ADC,EPS,IBCS,IDC,RBM
 SG_ CCU_IFC_1_Dummy4 : 455|64@0+ (1,0) [0|0] ""  ADC,EPS,IBCS,IDC,RBM
 SG_ CCU_IFC_1_Dummy3 : 39|18@0+ (1,0) [0|0] ""  ADC,EPS,IBCS,IDC,RBM
 SG_ CCU_IFC_1_Dummy2 : 25|2@0+ (1,0) [0|0] ""  ADC,EPS,IBCS,IDC,RBM
 SG_ CCU_IFC_1_Dummy1 : 31|4@0+ (1,0) [0|15] ""  ADC,EPS,IBCS,IDC,RBM
 SG_ IFC_1_CRC : 7|16@0+ (1,0) [0|65535] ""  EPS,RBM,IBCS,IDC,ADC
 SG_ IFC_1_Counter : 23|8@0+ (1,0) [0|255] ""  EPS,RBM,IBCS,IDC,ADC
 SG_ IFC_ICMWarnCardSt : 27|2@0+ (1,0) [0|3] ""  IDC,ADC
 SG_ IFC_ICMPromptWarn : 53|2@0+ (1,0) [0|3] ""  IDC,ADC

BO_ 773 CCU_ZCUR_WCM_1: 16 CCU
 SG_ WCM_ChargingSt : 9|2@0+ (1,0) [0|3] ""  IDC
 SG_ WCM_ControlResult : 11|2@0+ (1,0) [0|3] ""  IDC
 SG_ WCM_FailureSt : 15|4@0+ (1,0) [0|15] ""  IDC
 SG_ WCM_Reminder : 16|1@0+ (1,0) [0|1] ""  IDC

BO_ 1078 CCU_ZCUR_ETC_1: 16 CCU
 SG_ ETC_DismountSt : 31|2@0+ (1,0) [0|3] ""  IDC
 SG_ ETC_SelfcheckSt : 29|2@0+ (1,0) [0|3] ""  IDC
 SG_ ETC_GateProperty : 27|2@0+ (1,0) [0|3] ""  IDC
 SG_ ETC_TradeType : 25|2@0+ (1,0) [0|3] ""  IDC
 SG_ ETC_SystemSt : 39|1@0+ (1,0) [0|1] ""  IDC
 SG_ ETC_SysCfgst : 38|1@0+ (1,0) [0|1] ""  IDC
 SG_ ETC_ICMDisplayCfgst : 37|1@0+ (1,0) [0|1] ""  IDC
 SG_ ETC_BLEenableCfgst : 36|1@0+ (1,0) [0|1] ""  IDC
 SG_ ETC_ActivSt : 35|1@0+ (1,0) [0|1] ""  IDC
 SG_ ETC_TradeInfo : 47|32@0+ (0.01,0) [0|42949672.94] ""  IDC

BO_ 345 CCU_IDC_SECSYN: 16 CCU
 SG_ CCU_IDC_SecSyn : 7|128@0+ (1,0) [0|1] ""  IDC

BO_ 175 CCU_ADC_9: 64 CCU
 SG_ ADC_PAAChallenge1SBM : 39|8@0+ (1,0) [0|255] ""  ZCUR,IDC,SBM,TBOX
 SG_ ADC_PAAChallenge2SBM : 47|8@0+ (1,0) [0|255] ""  ZCUR,IDC,SBM,TBOX

BO_ 941 CCU_ADC_10: 64 CCU
 SG_ ADC_LowPowerfeedback : 455|3@0+ (1,0) [0|7] ""  IDC
 SG_ ADC_HPAStrtgEndgPointInfo : 39|5@0+ (1,0) [0|31] ""  ZCUR,IDC,SBM,TBOX
 SG_ ADC_HPALearningProcessInfo : 34|5@0+ (1,0) [0|31] ""  ZCUR,IDC,SBM,TBOX
 SG_ ADC_HPALearningFailedInfo : 45|4@0+ (1,0) [0|15] ""  ZCUR,IDC,SBM,TBOX
 SG_ ADC_HPALrngDst : 41|12@0+ (1,0) [0|4000] "m"  ZCUR,IDC,SBM,TBOX
 SG_ ADC_HPAResRouteLeg : 61|12@0+ (1,0) [0|4000] "m"  ZCUR,IDC,SBM,TBOX
 SG_ ADC_HPAUseActDis : 65|12@0+ (1,0) [0|4000] "m"  ZCUR,IDC,SBM,TBOX
 SG_ ADC_HPAProcRat : 85|7@0+ (1,0) [0|100] "%"  ZCUR,IDC,SBM,TBOX
 SG_ ADC_HPAUseTolTime : 94|12@0+ (1,0) [0|4095] "s"  ZCUR,IDC,SBM,TBOX
 SG_ ADC_ParkSlotChoiceL1 : 98|2@0+ (1,0) [0|3] ""  ZCUR,IDC,SBM,TBOX
 SG_ ADC_IconTwinkle : 96|1@0+ (1,0) [0|1] ""  ZCUR,IDC,SBM,TBOX
 SG_ ADC_ParkSlotChoiceR1 : 111|2@0+ (1,0) [0|3] ""  ZCUR,IDC,SBM,TBOX
 SG_ ADC_ParkSlotChoiceL2 : 109|2@0+ (1,0) [0|3] ""  ZCUR,IDC,SBM,TBOX
 SG_ ADC_ParkSlotChoiceR2 : 107|2@0+ (1,0) [0|3] ""  ZCUR,IDC,SBM,TBOX
 SG_ ADC_ParkSlotChoiceL3 : 105|2@0+ (1,0) [0|3] ""  ZCUR,IDC,SBM,TBOX
 SG_ ADC_ParkSlotChoiceR3 : 119|2@0+ (1,0) [0|3] ""  ZCUR,IDC,SBM,TBOX
 SG_ ADC_ParkSlotChoiceL4 : 117|2@0+ (1,0) [0|3] ""  ZCUR,IDC,SBM,TBOX
 SG_ ADC_ParkSlotChoiceR4 : 115|2@0+ (1,0) [0|3] ""  ZCUR,IDC,SBM,TBOX
 SG_ ADC_ParkSlotChoiceL5 : 113|2@0+ (1,0) [0|3] ""  ZCUR,IDC,SBM,TBOX
 SG_ ADC_ParkSlotChoiceR5 : 127|2@0+ (1,0) [0|3] ""  ZCUR,IDC,SBM,TBOX
 SG_ ADC_ParkSlotChoiceL6 : 125|2@0+ (1,0) [0|3] ""  ZCUR,IDC,SBM,TBOX
 SG_ ADC_ParkSlotChoiceR6 : 123|2@0+ (1,0) [0|3] ""  ZCUR,IDC,SBM,TBOX
 SG_ ADC_ParkSlotChoiceL7 : 121|2@0+ (1,0) [0|3] ""  ZCUR,IDC,SBM,TBOX
 SG_ ADC_ParkSlotChoiceR7 : 135|2@0+ (1,0) [0|3] ""  ZCUR,IDC,SBM,TBOX
 SG_ ADC_ParkSlotChoiceL8 : 133|2@0+ (1,0) [0|3] ""  ZCUR,IDC,SBM,TBOX
 SG_ ADC_ParkSlotChoiceR8 : 131|2@0+ (1,0) [0|3] ""  ZCUR,IDC,SBM,TBOX
 SG_ ADC_SlotSelectFebk : 129|5@0+ (1,0) [0|31] ""  ZCUR,IDC,SBM,TBOX
 SG_ ADC_AVPParkSlotInfo : 140|10@0+ (1,0) [0|1023] "cm"  ZCUR,IDC,SBM,TBOX
 SG_ ADC_SwitchStShow : 146|2@0+ (1,0) [0|3] ""  ZCUR,IDC,SBM,TBOX
 SG_ FAPA_RPAShortPresSuppSt : 144|1@0+ (1,0) [0|1] ""  ZCUR,IDC,SBM,TBOX
 SG_ ADC_HPASwitchStShow : 159|2@0+ (1,0) [0|3] ""  ZCUR,IDC,SBM,TBOX
 SG_ ADC_AVPSwitchStShow : 157|2@0+ (1,0) [0|3] ""  ZCUR,IDC,SBM,TBOX
 SG_ ADC_HPALearningPathType1 : 155|2@0+ (1,0) [0|3] ""  ZCUR,IDC,SBM,TBOX
 SG_ ADC_HPALearningLotType1 : 153|2@0+ (1,0) [0|3] ""  ZCUR,IDC,SBM,TBOX
 SG_ ADC_HPALearningPathNum1 : 167|4@0+ (1,0) [0|15] ""  ZCUR,IDC,SBM,TBOX
 SG_ ADC_HPAPathLearnRate1 : 163|4@0+ (10,0) [0|90] "%"  ZCUR,IDC,SBM,TBOX
 SG_ ADC_HPAPathSt1 : 175|2@0+ (1,0) [0|3] ""  ZCUR,IDC,SBM,TBOX
 SG_ ADC_HPAPath1Src : 173|2@0+ (1,0) [0|3] ""  ZCUR,IDC,SBM,TBOX
 SG_ ADC_HPAPathDst1 : 171|12@0+ (1,0) [0|4000] "m"  ZCUR,IDC,SBM,TBOX
 SG_ ADC_HPALearningPathNum2 : 191|4@0+ (1,0) [0|15] ""  ZCUR,IDC,SBM,TBOX
 SG_ ADC_HPAHAVPPathLearnRate2 : 187|4@0+ (10,0) [0|90] "%"  ZCUR,IDC,SBM,TBOX
 SG_ ADC_HPALearningPathType2 : 199|2@0+ (1,0) [0|3] ""  ZCUR,IDC,SBM,TBOX
 SG_ ADC_HPALearningLotType2 : 197|2@0+ (1,0) [0|3] ""  ZCUR,IDC,SBM,TBOX
 SG_ ADC_HPAPathSt2 : 195|2@0+ (1,0) [0|3] ""  ZCUR,IDC,SBM,TBOX
 SG_ ADC_HPAPath2Src : 193|2@0+ (1,0) [0|3] ""  ZCUR,IDC,SBM,TBOX
 SG_ ADC_HPAPathDst2 : 207|12@0+ (1,0) [0|4000] "m"  ZCUR,IDC,SBM,TBOX
 SG_ ADC_HPAPath1MatGpsSucces : 211|1@0+ (1,0) [0|1] ""  ZCUR,IDC,SBM,TBOX
 SG_ ADC_HPAPath2MatGpsSucces : 210|1@0+ (1,0) [0|1] ""  ZCUR,IDC,SBM,TBOX
 SG_ ADC_HPALearningPathType3 : 209|2@0+ (1,0) [0|3] ""  ZCUR,IDC,SBM,TBOX
 SG_ ADC_HPALearningPathNum3 : 223|4@0+ (1,0) [0|15] ""  ZCUR,IDC,SBM,TBOX
 SG_ ADC_HPAPathLearnRate3 : 219|4@0+ (10,0) [0|90] "%"  ZCUR,IDC,SBM,TBOX
 SG_ ADC_HPALearningLotType3 : 231|2@0+ (1,0) [0|3] ""  ZCUR,IDC,SBM,TBOX
 SG_ ADC_HPAPathSt3 : 229|2@0+ (1,0) [0|3] ""  ZCUR,IDC,SBM,TBOX
 SG_ ADC_HPAPath3Src : 227|2@0+ (1,0) [0|3] ""  ZCUR,IDC,SBM,TBOX
 SG_ ADC_HPAPathDst3 : 225|12@0+ (1,0) [0|4000] "m"  ZCUR,IDC,SBM,TBOX
 SG_ ADC_HPALearningPathNum4 : 245|4@0+ (1,0) [0|15] ""  ZCUR,IDC,SBM,TBOX
 SG_ ADC_HPAPathLearnRate4 : 241|4@0+ (10,0) [0|90] "%"  ZCUR,IDC,SBM,TBOX
 SG_ ADC_HPALearningPathType4 : 253|2@0+ (1,0) [0|3] ""  ZCUR,IDC,SBM,TBOX
 SG_ ADC_HPALearningLotType4 : 251|2@0+ (1,0) [0|3] ""  ZCUR,IDC,SBM,TBOX
 SG_ ADC_HPAPathSt4 : 249|2@0+ (1,0) [0|3] ""  ZCUR,IDC,SBM,TBOX
 SG_ ADC_HPAPath4Src : 263|2@0+ (1,0) [0|3] ""  ZCUR,IDC,SBM,TBOX
 SG_ ADC_HPAPathDst4 : 261|12@0+ (1,0) [0|4000] "m"  ZCUR,IDC,SBM,TBOX
 SG_ ADC_HPAPath3MatGpsSucces : 265|1@0+ (1,0) [0|1] ""  ZCUR,IDC,SBM,TBOX
 SG_ ADC_HPAPath4MatGpsSucces : 264|1@0+ (1,0) [0|1] ""  ZCUR,IDC,SBM,TBOX
 SG_ ADC_HPALearningPathNum5 : 279|4@0+ (1,0) [0|15] ""  ZCUR,IDC,SBM,TBOX
 SG_ ADC_HPAPathLearnRate5 : 275|4@0+ (10,0) [0|90] "%"  ZCUR,IDC,SBM,TBOX
 SG_ ADC_HPALearningPathType5 : 287|2@0+ (1,0) [0|3] ""  ZCUR,IDC,SBM,TBOX
 SG_ ADC_HPALearningLotType5 : 285|2@0+ (1,0) [0|3] ""  ZCUR,IDC,SBM,TBOX
 SG_ ADC_HPAPathSt5 : 283|2@0+ (1,0) [0|3] ""  ZCUR,IDC,SBM,TBOX
 SG_ ADC_HPAPath5Src : 281|2@0+ (1,0) [0|3] ""  ZCUR,IDC,SBM,TBOX
 SG_ ADC_HPAPathDst5 : 295|12@0+ (1,0) [0|4000] "m"  ZCUR,IDC,SBM,TBOX
 SG_ ADC_HPALearningPathNum6 : 299|4@0+ (1,0) [0|15] ""  ZCUR,IDC,SBM,TBOX
 SG_ ADC_HPAPathLearnRate6 : 311|4@0+ (10,0) [0|90] "%"  ZCUR,IDC,SBM,TBOX
 SG_ ADC_HPALearningPathType6 : 307|2@0+ (1,0) [0|3] ""  ZCUR,IDC,SBM,TBOX
 SG_ ADC_HPALearningLotType6 : 305|2@0+ (1,0) [0|3] ""  ZCUR,IDC,SBM,TBOX
 SG_ ADC_HPAPathSt6 : 319|2@0+ (1,0) [0|3] ""  ZCUR,IDC,SBM,TBOX
 SG_ ADC_HPAPath6Src : 317|2@0+ (1,0) [0|3] ""  ZCUR,IDC,SBM,TBOX
 SG_ ADC_HPAPathDst6 : 315|12@0+ (1,0) [0|4000] "m"  ZCUR,IDC,SBM,TBOX
 SG_ ADC_HPAPath5MatGpsSucces : 335|1@0+ (1,0) [0|1] ""  ZCUR,IDC,SBM,TBOX
 SG_ ADC_HPAPath6MatGpsSucces : 334|1@0+ (1,0) [0|1] ""  ZCUR,IDC,SBM,TBOX
 SG_ ADC_HPALearningPathNum7 : 333|4@0+ (1,0) [0|15] ""  ZCUR,IDC,SBM,TBOX
 SG_ ADC_HPAPathLearnRate7 : 329|4@0+ (10,0) [0|90] "%"  ZCUR,IDC,SBM,TBOX
 SG_ ADC_HPALearningPathType7 : 341|2@0+ (1,0) [0|3] ""  ZCUR,IDC,SBM,TBOX
 SG_ ADC_HPALearningLotType7 : 339|2@0+ (1,0) [0|3] ""  ZCUR,IDC,SBM,TBOX
 SG_ ADC_HPAPathSt7 : 337|2@0+ (1,0) [0|3] ""  ZCUR,IDC,SBM,TBOX
 SG_ ADC_HPAPath7Src : 351|2@0+ (1,0) [0|3] ""  ZCUR,IDC,SBM,TBOX
 SG_ ADC_HPAPathDst7 : 349|12@0+ (1,0) [0|4000] "m"  ZCUR,IDC,SBM,TBOX
 SG_ ADC_HPALearningPathNum8 : 353|4@0+ (1,0) [0|15] ""  ZCUR,IDC,SBM,TBOX
 SG_ ADC_HPAPathLearnRate8 : 365|4@0+ (10,0) [0|90] "%"  ZCUR,IDC,SBM,TBOX
 SG_ ADC_HPALearningPathType8 : 361|2@0+ (1,0) [0|3] ""  ZCUR,IDC,SBM,TBOX
 SG_ ADC_HPALearningLotType8 : 375|2@0+ (1,0) [0|3] ""  ZCUR,IDC,SBM,TBOX
 SG_ ADC_HPAPPathSt8 : 373|2@0+ (1,0) [0|3] ""  ZCUR,IDC,SBM,TBOX
 SG_ ADC_HPAPath8Src : 371|2@0+ (1,0) [0|3] ""  ZCUR,IDC,SBM,TBOX
 SG_ ADC_HPAPathDst8 : 369|12@0+ (1,0) [0|4000] "m"  ZCUR,IDC,SBM,TBOX
 SG_ ADC_HPAPath7MatGpsSucces : 389|1@0+ (1,0) [0|1] ""  ZCUR,IDC,SBM,TBOX
 SG_ ADC_HPAPath8MatGpsSucces : 388|1@0+ (1,0) [0|1] ""  ZCUR,IDC,SBM,TBOX
 SG_ ADC_HPALearningPathNum9 : 387|4@0+ (1,0) [0|15] ""  ZCUR,IDC,SBM,TBOX
 SG_ ADC_HPAPathLearnRate9 : 399|4@0+ (10,0) [0|90] "%"  ZCUR,IDC,SBM,TBOX
 SG_ ADC_HPALearningPathType9 : 395|2@0+ (1,0) [0|3] ""  ZCUR,IDC,SBM,TBOX
 SG_ ADC_HPALearningLotType9 : 393|2@0+ (1,0) [0|3] ""  ZCUR,IDC,SBM,TBOX
 SG_ ADC_HPAPathSt9 : 407|2@0+ (1,0) [0|3] ""  ZCUR,IDC,SBM,TBOX
 SG_ ADC_HPAPath9Src : 405|2@0+ (1,0) [0|3] ""  ZCUR,IDC,SBM,TBOX
 SG_ ADC_HPAPathDst9 : 403|12@0+ (1,0) [0|4000] "m"  ZCUR,IDC,SBM,TBOX
 SG_ ADC_HPALearningPathNum10 : 423|4@0+ (1,0) [0|15] ""  ZCUR,IDC,SBM,TBOX
 SG_ ADC_HPAPathLearnRate10 : 419|4@0+ (10,0) [0|90] "%"  ZCUR,IDC,SBM,TBOX
 SG_ ADC_HPALearningPathType10 : 431|2@0+ (1,0) [0|3] ""  ZCUR,IDC,SBM,TBOX
 SG_ ADC_HPALearningLotType10 : 429|2@0+ (1,0) [0|3] ""  ZCUR,IDC,SBM,TBOX
 SG_ ADC_HPAPathSt10 : 427|2@0+ (1,0) [0|3] ""  ZCUR,IDC,SBM,TBOX
 SG_ ADC_HPAPath10Src : 425|2@0+ (1,0) [0|3] ""  ZCUR,IDC,SBM,TBOX
 SG_ ADC_HPAPathDst10 : 439|12@0+ (1,0) [0|4000] "m"  ZCUR,IDC,SBM,TBOX
 SG_ ADC_HPAPath9MatGpsSucces : 443|1@0+ (1,0) [0|1] ""  ZCUR,IDC,SBM,TBOX
 SG_ ADC_HPAPath10MatGpsSucces : 442|1@0+ (1,0) [0|1] ""  ZCUR,IDC,SBM,TBOX

BO_ 835 CCU_ADC_11: 64 CCU
 SG_ OMS_SysErrSt_ADC : 335|3@0+ (1,0) [0|7] ""  IDC
 SG_ DMS_SysErrSt_ADC : 323|3@0+ (1,0) [0|7] ""  IDC
 SG_ DMS_FaceID_ADC : 327|4@0+ (1,0) [0|15] ""  IDC
 SG_ PCS_VoiceReq : 267|4@0+ (1,0) [0|15] ""  IDC
 SG_ PCS_ER_QuitReq : 287|1@0+ (1,0) [0|1] ""  IDC
 SG_ PCS_ER_EnterConfirm : 274|1@0+ (1,0) [0|1] ""  IDC
 SG_ PCS_EventRecordSt : 260|1@0+ (1,0) [0|1] ""  IDC
 SG_ PCS_MirrorPageDownButton : 273|2@0+ (1,0) [0|3] ""  IDC
 SG_ PCS_SystemSt : 263|1@0+ (1,0) [0|1] ""  IDC
 SG_ ADC_DPMessagePushSt : 221|2@0+ (1,0) [0|3] ""  IDC
 SG_ PAS_BattVoltErrFlag : 158|1@0+ (1,0) [0|1] ""  IDC
 SG_ PAS_CtrlModulerrFlag : 159|1@0+ (1,0) [0|1] ""  IDC
 SG_ PAS_FSRSnsErrFlag : 144|1@0+ (1,0) [0|1] ""  IDC
 SG_ PAS_FSLSnsErrFlag : 145|1@0+ (1,0) [0|1] ""  IDC
 SG_ PAS_FLMidSnsErrFlag : 146|1@0+ (1,0) [0|1] ""  IDC
 SG_ PAS_FRMidSnsErrFlag : 147|1@0+ (1,0) [0|1] ""  IDC
 SG_ PAS_FLSnsErrFlag : 148|1@0+ (1,0) [0|1] ""  IDC
 SG_ PAS_FRSnsErrFlag : 149|1@0+ (1,0) [0|1] ""  IDC
 SG_ PAS_RSRSnsErrFlag : 150|1@0+ (1,0) [0|1] ""  IDC
 SG_ PAS_RSLSnsErrFlag : 151|1@0+ (1,0) [0|1] ""  IDC
 SG_ PAS_RLSnsErrFlag : 136|1@0+ (1,0) [0|1] ""  IDC
 SG_ PAS_RRSnsErrFlag : 137|1@0+ (1,0) [0|1] ""  IDC
 SG_ PAS_RLMidSnsErrFlag : 138|1@0+ (1,0) [0|1] ""  IDC
 SG_ PAS_RRMidSnsErrFlag : 139|1@0+ (1,0) [0|1] ""  IDC
 SG_ PCS_SoundReminderSt : 275|1@0+ (1,0) [0|1] ""  IDC
 SG_ PCS_HelpMenuSt : 276|1@0+ (1,0) [0|1] ""  IDC
 SG_ PCS_ReturnSt : 277|1@0+ (1,0) [0|1] ""  IDC
 SG_ PCS_RightBlindSpotViewSt : 278|1@0+ (1,0) [0|1] ""  IDC
 SG_ PCS_LeftBlindSpotViewSt : 279|1@0+ (1,0) [0|1] ""  IDC
 SG_ PCS_FrontRightCameraFail : 261|1@0+ (1,0) [0|1] ""  IDC
 SG_ PCS_FrontLeftCameraFail : 262|1@0+ (1,0) [0|1] ""  IDC
 SG_ ADC_ACU_DisplayReq : 192|1@0+ (1,0) [0|1] ""  IDC
 SG_ PCS_HMIIndex : 259|4@0+ (1,0) [0|15] ""  IDC
 SG_ PAS_SystemType : 31|2@0+ (1,0) [0|3] ""  ZCUR,IDC,SBM
 SG_ PAS_WarnTone : 29|4@0+ (1,0) [0|15] ""  ZCUR,IDC,SBM
 SG_ PAS_ButtonPress : 25|1@0+ (1,0) [0|1] ""  ZCUR,IDC,SBM
 SG_ PAS_SideZoneStatusF : 39|2@0+ (1,0) [0|3] ""  ZCUR,IDC,SBM
 SG_ PAS_SideZoneStatusR : 37|2@0+ (1,0) [0|3] ""  ZCUR,IDC,SBM
 SG_ PAS_RRMidDistance : 47|8@0+ (1,0) [0|255] "cm"  ZCUR,IDC,SBM
 SG_ PAS_RLMidDistance : 55|8@0+ (1,0) [0|255] "cm"  ZCUR,IDC,SBM
 SG_ PAS_RRDistance : 63|8@0+ (1,0) [0|255] "cm"  ZCUR,IDC,SBM
 SG_ PAS_RLDistance : 71|8@0+ (1,0) [0|255] "cm"  ZCUR,IDC,SBM
 SG_ PAS_RSLSideDistance : 79|8@0+ (1,0) [0|255] "cm"  ZCUR,IDC,SBM
 SG_ PAS_RSRSideDistance : 87|8@0+ (1,0) [0|255] "cm"  ZCUR,IDC,SBM
 SG_ PAS_FRDistance : 95|8@0+ (1,0) [0|255] "cm"  ZCUR,IDC,SBM
 SG_ PAS_FLDistance : 103|8@0+ (1,0) [0|255] "cm"  ZCUR,IDC,SBM
 SG_ PAS_FRMidDistance : 111|8@0+ (1,0) [0|255] "cm"  ZCUR,IDC,SBM
 SG_ PAS_FLMidDistance : 119|8@0+ (1,0) [0|255] "cm"  ZCUR,IDC,SBM
 SG_ PAS_FSRSideDistance : 127|8@0+ (1,0) [0|255] "cm"  ZCUR,IDC,SBM
 SG_ PAS_FSLSideDistance : 135|8@0+ (1,0) [0|255] "cm"  ZCUR,IDC,SBM
 SG_ PAS_Mode : 143|4@0+ (1,0) [0|15] ""  ZCUR,IDC,SBM
 SG_ PCS_RightCameraFail : 282|1@0+ (1,0) [0|1] ""  ZCUR,IDC,SBM
 SG_ PCS_RearCameraFail : 281|1@0+ (1,0) [0|1] ""  ZCUR,IDC,SBM
 SG_ PCS_CalibrateSt : 311|3@0+ (1,0) [0|7] ""  ZCUR,IDC,SBM
 SG_ PCS_SystemType : 318|2@0+ (1,0) [0|3] ""  ZCUR,IDC,SBM
 SG_ PCS_SingleViewInd : 271|4@0+ (1,0) [0|15] ""  ZCUR,IDC,SBM
 SG_ PCS_MODEnalbe : 304|1@0+ (1,0) [0|1] ""  ZCUR,IDC,SBM
 SG_ PCS_3DEnalbe : 319|1@0+ (1,0) [0|1] ""  ZCUR,IDC,SBM
 SG_ PCS_OperationSt : 316|2@0+ (1,0) [0|3] ""  ZCUR,IDC,SBM
 SG_ PCS_ACU_DisplayReq : 280|1@0+ (1,0) [0|1] ""  ZCUR,IDC,SBM
 SG_ PCS_PASButtonPress : 286|1@0+ (1,0) [0|1] ""  ZCUR,IDC,SBM
 SG_ PCS_VRSwitchFailSt : 285|1@0+ (1,0) [0|1] ""  ZCUR,IDC,SBM
 SG_ PCS_FrontCameraFail : 284|1@0+ (1,0) [0|1] ""  ZCUR,IDC,SBM
 SG_ PCS_LeftCameraFail : 283|1@0+ (1,0) [0|1] ""  ZCUR,IDC,SBM

BO_ 549 CCU_ADC_12: 64 CCU
 SG_ ADC_RAEBWorkSts : 101|2@0+ (1,0) [0|3] ""  IDC
 SG_ ADC_PAARecInd : 135|6@0+ (1,0) [0|63] ""  IDC,SBM
 SG_ ADC_PAAQuitInd : 127|8@0+ (1,0) [0|255] ""  IDC,SBM
 SG_ ADC_PAADrvReq : 119|8@0+ (1,0) [0|255] ""  IDC,SBM
 SG_ ADC_SBMAuthst : 163|2@0+ (1,0) [0|3] ""  IDC,SBM,TBOX,ZCUR
 SG_ ADC_APKDisplayReq : 54|1@0+ (1,0) [0|1] ""  IDC,SBM,ZCUR
 SG_ ADC_PAAVRSwitchFailSt : 55|1@0+ (1,0) [0|1] ""  IDC,RPC,SBM,ZCUR
 SG_ ADC_PAAFuncSt : 39|4@0+ (1,0) [0|15] ""  ZCUR,IDC,SBM,TBOX
 SG_ ADC_APABackParkDisplayReq : 49|2@0+ (1,0) [0|3] ""  ZCUR,IDC
 SG_ ADC_APAMessagePushSt : 58|2@0+ (1,0) [0|3] ""  ZCUR,IDC,SBM
 SG_ ADC_HPAMessagePushSt : 71|2@0+ (1,0) [0|3] ""  ZCUR,IDC,SBM
 SG_ ADC_AVPMessagePushSt : 69|2@0+ (1,0) [0|3] ""  ZCUR,IDC,SBM
 SG_ ADC_PAADrvInteraction : 64|9@0+ (1,0) [0|511] ""  ZCUR,IDC,SBM,TBOX

BO_ 154 CCU_IMMO: 32 CCU
 SG_ CCU_IMMO : 7|256@0+ (1,0) [0|0] ""  ZCUR,IDC,SBM,TBOX

BO_ 120 CCU_SECKEY: 32 CCU
 SG_ CCU_SEC_KEY_Defaultencoding : 7|256@0+ (1,0) [0|0] ""  ZCUF,ZCUL,ZCUR,ZCUT,IDC,ADC

CM_ SG_ 295 IL_IALFunctionCfgSt "IALFunctionconfigrationState";
CM_ SG_ 295 IL_IALWorkSt "IALBrightnessSetState";
CM_ SG_ 295 IL_IALBrightnessSetSt "IALBrightnessSetState";
CM_ SG_ 295 IL_IALDriverModeCfgSt "IALDriverModeConfigurationState";
CM_ SG_ 295 IL_IALColorSetSt "IALColorSetState";
CM_ SG_ 295 IL_IALMusicModeCfgSt "IALMusicModeConfigurationState";
CM_ SG_ 295 IALVoiceModeCfgSt "IALVoiceModeConfigurationState";
CM_ SG_ 400 UINM_DrvReqShft "Driver requested gear shift position";
CM_ SG_ 400 UINM_TurnLightSwSt "Turn light switch state";
CM_ SG_ 400 UINM_FrontWiperSwSt "Front wiper interval switch status";
CM_ SG_ 400 UINM_FrontWasherSwSt "Front Washer switch status ";
CM_ SG_ 615 BCS_RLWheelRotatedDirection "RL wheel rotate direction";
CM_ SG_ 615 BCS_RLWheelSpd "Current wheel speed information of front left wheel";
CM_ SG_ 615 BCS_RRWheelSpdEdgesSum "Accumulated sum of rising and falling edges of  rear right wheel speed sensor output¡¤since IGN ON( the wheel plate have 48 teeth/cycle,the edge is 96)";
CM_ SG_ 615 BCS_FRWheelSpdEdgesSum "Accumulated sum of rising and falling edges of front right wheel speed sensor output¡¤since IGN ON( the wheel plate have 48 teeth/cycle,the edge is 96)";
CM_ SG_ 615 BCS_RRWheelRotatedDirection "RR wheel rotate direction";
CM_ SG_ 615 BCS_RRWheelSpd "Current wheel speed information of RRont left wheel";
CM_ SG_ 615 BCS_FRWheelRotatedDirection "FR wheel rotate direction";
CM_ SG_ 615 BCS_FRWheelSpd "Current wheel speed information of front left wheel";
CM_ SG_ 615 BCS_FLWheelRotatedDirection "FL wheel rotate direction";
CM_ SG_ 615 BCS_FLWheelSpd "Current wheel speed information of front left wheel";
CM_ SG_ 615 BCS_1_Counter "E2E Profile 5 Counter";
CM_ SG_ 615 BCS_1_CRC "E2E Profile 5 CRC";
CM_ SG_ 615 BCS_FLWheelSpdEdgesSumVD "Quality/fault information to current wheel speed edges sum of front left wheel";
CM_ SG_ 615 BCS_FLWheelSpdEdgesSum "Accumulated sum of rising and falling edges of front left wheel speed sensor output¡¤since IGN ON( the wheel plate have 48 teeth/cycle,the edge is 96)";
CM_ SG_ 615 BCS_HHCErrSt "HHC error status";
CM_ SG_ 615 BCS_HDCCtrlSt "HDC(Hill Descent Control) control status";
CM_ SG_ 615 BCS_HDCErrSt "HDC error status";
CM_ SG_ 615 BCS_RLWheelSpdEdgesSum "Accumulated sum of rising and falling edges of rear left wheel speed sensor outputÂ·since IGN ON( the wheel plate have 48 teeth/cycle,the edge is 96)";
CM_ SG_ 615 BCS_RLWheelSpdEdgesSumVD "Quality/fault information to current wheel speed edges sum of rear left wheel";
CM_ SG_ 615 BCS_VDCOff "VDC is switched off ";
CM_ SG_ 615 BCS_AVHSt "Indicates AVH(Auto Vehicle Hold)in active or not ";
CM_ SG_ 615 BCS_AVHStandby "Indicates AVH(Auto Vehicle Hold)in standby mode or not ";
CM_ SG_ 615 BCS_AVHAvailable "HMI responsible, can get degrate AVH(Auto Vehicle Hold) statement from DSW and send out ";
CM_ SG_ 615 BCS_TCSOff "TCS is switched off ";
CM_ SG_ 615 BCS_ESPFuncResp "Response the ESP function status";
CM_ SG_ 615 BCS_HDCFuncResp "Response the HDC function status";
CM_ SG_ 352 IPB_BrakePedalSt "IBCS Brake Pedal Status";
CM_ SG_ 352 BCS_2_Counter "E2E Profile 5 Counter";
CM_ SG_ 352 BCS_2_CRC "E2E Profile 5 CRC";
CM_ SG_ 352 BCS_VehSpd "Vehicle speed";
CM_ SG_ 352 BCS_VehSpdVD "Quality/fault information to vehicle speed";
CM_ SG_ 352 BCS_EBDFaultSt "ABS system has detected a heavy fault, which does not even allow a reliable electronic brake distribution and is therefore completely shut down";
CM_ SG_ 352 BCS_ABSFaultSt "ABS system has detected a failure which does no allow a reliable ABS regulation and is therefore switched off";
CM_ SG_ 352 BCS_TCSActiveSt "Indication that TCS system currently performs a brake/engine intervention";
CM_ SG_ 352 BCS_TCSFaultSt "TCS is switched off due to detected failure";
CM_ SG_ 352 BCS_VDCActiveSt "Indication that VDC system currently performs a brake/engine intervention when ESP adjust the posture of vehicle ";
CM_ SG_ 352 BCS_VDCFaultSt "VDC is switched off due to detected failure";
CM_ SG_ 611 IPB_BrkPedalModesetSt "BrkPedalModeCfgSt10x01~0x64:?1%~100%?Linear:-?resolution:?1%?per?bit-?offset:0?0x65~0x7E=Reserved?0x7F=Invalid";
CM_ SG_ 611 BCS_3_CRC "E2E Profile 5 CRC";
CM_ SG_ 611 BCS_3_Counter "E2E Profile 5 Counter";
CM_ SG_ 611 IPB_BrkPedalModeCfgSt "BrkPedalModeCfgSt";
CM_ SG_ 611 IPB_InputRodStrokeSt "Indicate inputRod stroke status";
CM_ SG_ 611 IBCS_SystemSt "IBCS system state";
CM_ SG_ 611 IBCS_FWAWarning "Indicate FWA state, dashboard need warn driver";
CM_ SG_ 611 IBCS_BrakeFluidWarning "Indicate BrakeFluid Warning state, dashboard need warn driver";
CM_ SG_ 611 IPB_CSTSt "indicates CST status. Only valid for project with CST function.";
CM_ SG_ 611 IBCS_TwoFoot_DriveWarning "Indicate TwoFoot Drive Warning state,  dashboard need warn driver";
CM_ SG_ 611 BCS_ESPMode "get ESP mode feedback";
CM_ SG_ 886 BCS_TPMSResetSt "For showing the rest result on dashboard or HMI";
CM_ SG_ 886 BCS_TPMSWarningLamp "For illuminating the warning lamp for 2s during self check phase by ignition on. For illuminating the warning lamp constantly when deflation detected.";
CM_ SG_ 886 BCS_TPMSSysErrorSt "Warning lamp on the dashboard should flash for 60s(1Hz) and keep lit constantly. The same routine should be performed at ignition on. This signal should have higher priority than TPMS_Warning_Lamp TPMS warning light. It could also be used for showing Text information on the dashboard or HMI.";
CM_ SG_ 886 BCS_TPMSFLTyrePreWarn "For illuminating the front left wheel on the TPMS car symbol and/or for showing text information";
CM_ SG_ 886 BCS_TPMSFRTyrePreWarn "For illuminating the front right wheel on the TPMS car model and/or for showing text information";
CM_ SG_ 886 BCS_AVHSoftSwctrlst "Feedback  AVH Soft Switch contral  status to ACU";
CM_ SG_ 886 BCS_TPMSRLTyrePreWarn "For illuminating the rear left wheel on the TPMS car model and/or for showing text information";
CM_ SG_ 886 BCS_TPMSRRTyrePreWarn "For illuminating the rear right wheel on the TPMS car model and/or for showing text information";
CM_ SG_ 618 EPB_DragMode "Drag Mode status";
CM_ SG_ 618 EPB_1_CRC "E2E Profile 5 CRC";
CM_ SG_ 618 EPB_1_Counter "E2E Profile 5 Counter";
CM_ SG_ 618 EPB_SysSt "EPB system status ";
CM_ SG_ 618 EPB_SysStIndReq "EPB system status indication request";
CM_ SG_ 618 EPB_FailSt "EPB fail status,to indicate wether EPB can response to external apply  request or not";
CM_ SG_ 618 EPB_SysWarnIndReq "EPB system warning indication request  ";
CM_ SG_ 618 EPB_SysAudWarnReq "EPB system audible warning request ";
CM_ SG_ 618 EPB_SysDispMsgReq "EPB system display message request";
CM_ SG_ 618 EPB_StpOnBrkToRelParkBrkIndOn "Step on brake to release park brake Indication on ";
CM_ SG_ 939 SRS_2_CRC "E2E Profile 5 CRC";
CM_ SG_ 939 SRS_2_Counter "E2E Profile 5 Counter";
CM_ SG_ 939 SRS_PsngrSeatBeltSt "To identify whether Passenger Seat Belt is buckled";
CM_ SG_ 939 SRS_DriverSeatBeltSt "To identify whether Driver Seat Belt is buckled";
CM_ SG_ 939 SRS_RearLeftSeatBeltSt "To identify whether RearLeftSeatBelt is buckled";
CM_ SG_ 939 SRS_AirbagFaultSt "To illuminate or turn off airbag warning indicator";
CM_ SG_ 939 SRS_RearRightSeatBeltSt "To identify  whether RearRightSeatBelt is buckled";
CM_ SG_ 939 SRS_RearMiddleSeatBeltSt "To identify whether RearMiddleSeatBelt is buckled";
CM_ SG_ 368 DCU_TorqAct "actual torque of drive motor";
CM_ SG_ 864 DCU_SysTempOvrInd "Indicator of overheat warning lamp, which is lighten if temperature of drive motor system is too high.";
CM_ SG_ 864 DCU_Err2NoticeFlag " Lever2 Error for DCU Popup flag";
CM_ SG_ 864 DCU_ErrNotice "DCU error notice";
CM_ SG_ 864 DCU_ErrNoticeOperationFlag "Operation flag for DCU error notice";
CM_ SG_ 864 DCU_2_Counter "E2E Profile 5 Counter";
CM_ SG_ 864 DCU_2_CRC "E2E Profile 5 CRC";
CM_ SG_ 864 DCU_FaultLampInd "Warning indicator to lighten fault lamp (Malfunction Indication Lamp,MIL)";
CM_ SG_ 872 IPS_OBCFaultLampIndOperationFlag "Operation flag for  IPS_OBCFaultLampInd";
CM_ SG_ 872 IPS_DCDCFaultLampIndFlag "Popup flag for DCDC error notice";
CM_ SG_ 872 IPS_DCDCFaultLampIndOperationFla "Operation flag for IPS_DCDCFaultLampInd";
CM_ SG_ 872 IPS_2_CRC "E2E Profile 5 CRC";
CM_ SG_ 872 IPS_2_Counter "E2E Profile 5 Counter";
CM_ SG_ 872 IPS_DCDCFaultLampInd "nan";
CM_ SG_ 872 IPS_OBCFaultLampInd "nan";
CM_ SG_ 880 ITS_MotorPumpSt "Indicate The motor pump State";
CM_ SG_ 880 ITS_FanStpSpdErr "fan stop running error";
CM_ SG_ 880 ITS_HeaterPumpSt "Indicate The Heater pump State";
CM_ SG_ 880 ITS_EcvSt "Indicate the state of ECV";
CM_ SG_ 880 ITS_BatteryPumpSt "Indicate The battery pump State";
CM_ SG_ 880 ITS_MotorInletTempErr "Motor Loop Temperature sensor error";
CM_ SG_ 880 ITS_BatteryInletTempErr "Battery Loop In Temperature sensor error";
CM_ SG_ 880 ITS_ChillerInletTempErr "Temperature sensor error of chiller inlet ";
CM_ SG_ 880 ITS_SolenoidErr "nan";
CM_ SG_ 824 VCU_HVAC_PTCdelayEn "PTC OFF or downshift should be delayed if enable this signal, othewise not";
CM_ SG_ 824 VCU_2_CRC "E2E Profile 5 CRC";
CM_ SG_ 824 VCU_2_Counter "E2E Profile 5 Counter";
CM_ SG_ 824 VCU_LongDistResp "Long Distance response for display";
CM_ SG_ 824 VCU_SwapHvBattModeStVD "VCU swap Hvbattery mode statue VD";
CM_ SG_ 824 VCU_SwapHvBattModeSt "VCU swap Hvbattery mode status";
CM_ SG_ 824 VCU_WarmTimeNotice "Request warm time voice notice function";
CM_ SG_ 824 VCU_VehElcConspInst "Instant electric consumption";
CM_ SG_ 824 VCU_DischgSt "State of Discharge button(on av/avnt) reponse";
CM_ SG_ 824 VCU_DischgAvai "To indicate if the Discharge button is available";
CM_ SG_ 824 VCU_WarmTimeCfgResp "Response of Warm time configuration respond";
CM_ SG_ 824 VCU_WarmSt "Warm time status";
CM_ SG_ 824 VCU_CreepAvail "To indicate if the Creep function is available";
CM_ SG_ 824 VCU_GearLvlDisp "Gear lever for display";
CM_ SG_ 824 VCU_RecpLevelAvail "To indicate if the recuperation level is available";
CM_ SG_ 824 VCU_IpedalModeAvail "To indicate if the Ipedal mode is available";
CM_ SG_ 824 VCU_ElcSysFault "HEV system error text messages";
CM_ SG_ 824 VCU_DspChgSt "Display charge state";
CM_ SG_ 824 VCU_DspDischgSt "Display discharge state";
CM_ SG_ 824 VCU_SOCDynamicDspSt "Display state of charge";
CM_ SG_ 824 VCU_DspChgVolt "Display charge voltage";
CM_ SG_ 824 VCU_BookChgLampInd "Actual book charge state for display";
CM_ SG_ 824 VCU_DspChgCurr "Display charge current";
CM_ SG_ 824 VCU_DspDischgVolt "Display discharge voltage";
CM_ SG_ 824 VCU_EcoPlusModeAvail "To indicate if the ECO+ mode is available";
CM_ SG_ 824 VCU_DspDischgCurr "Display discharge current";
CM_ SG_ 824 VCU_DriverNoticeDisp "Notice for driver, diplayed on screen";
CM_ SG_ 824 VCU_DrvChgDchgDsp "Charge and discharge display";
CM_ SG_ 824 VCU_CruExitNotice "Cruise Exit signal for display";
CM_ SG_ 824 VCU_DischgEndVehRng "Remaining vehicle range at the end of discharge for display";
CM_ SG_ 824 VCU_DischgSocResp "Discharge SOC response for display";
CM_ SG_ 824 VCU_VehElcConspAvg "Average electric consumption";
CM_ SG_ 824 VCU_VehElcConspAccumAvg "Accumulated average electric consumption";
CM_ SG_ 824 VCU_GearLvlBlink "Blink indicator for gear level, which is turned on if virtual gear level (judged by VCU for display) is different from actual gear level (detected by PCU)";
CM_ SG_ 824 VCU_EcoModeAvail "To indicate if the ECO, mode is available";
CM_ SG_ 824 VCU_PGearErrNotice "PCU or EPB P lock error, VCU judge vehicle cann`t releae or apply P gear";
CM_ SG_ 824 VCU_VehCrusSt "Cruise Control State for display";
CM_ SG_ 824 VCU_PwrFlowMode "To display the power flow";
CM_ SG_ 824 VCU_FaultLampInd "HEV system error warning indictor";
CM_ SG_ 824 VCU_VehDrvMod "Drive mode for display";
CM_ SG_ 824 VCU_ARBWarnNotice "Anti-roll back warn notice";
CM_ SG_ 824 VCU_BuzReq "Buzzer request";
CM_ SG_ 824 VCU_VehRdySt "HEV system ready status";
CM_ SG_ 824 VCU_ICMSpdLimitNotice "ECO+/ECO/I-PEDAL driving mode limit speed notice";
CM_ SG_ 824 VCU_VehCrusTgtSpd "VCU set Cruise target speed for display(use ICM speed)";
CM_ SG_ 824 VCU_PrecResHotMsg "Info driver that HV power up failed due to precharge resistor over temp";
CM_ SG_ 824 VCU_VehChgDischgSt "Traction Battery Charging and Discharging Status for Display";
CM_ SG_ 824 VCU_ChgTimeDspType "Charging state for time display";
CM_ SG_ 824 VCU_ThermalMsgWarn "Thermal system fault";
CM_ SG_ 824 VCU_VehAvailDriveStMsgWarn "Vehicle available drive state message warn on ICM";
CM_ SG_ 824 VCU_DerateLampSt "The state of derating lamp. While VCU detects malfunction or fault, the lamp will turn on or blink according to the fault level and derating mode.";
CM_ SG_ 824 VCU_PlgConnSt "Charge connectorÂ  connected Status";
CM_ SG_ 824 VCU_VehPwrDisp "nan";
CM_ SG_ 824 VCU_DischgSetInfo "Information ofÂ  Discharge button(on av/avnt) for A18-Y";
CM_ SG_ 824 VCU_ChgPlugRelSt "Send to ACU from VCU to response to unlock charge outlet";
CM_ SG_ 824 VCU_IDC_VehSwapModIntf "VCU request IDC swap mode";
CM_ SG_ 824 VCU_IDC_VehSwapModReq "Request AVNT to enter the battery swap interface";
CM_ SG_ 824 VCU_IDC_VehSwapModResp "Response the swap mode";
CM_ SG_ 824 VCU_IDC_VehSwapModAvai "To indicate if the swap mode is available";
CM_ SG_ 824 VCU_RecpLevelstResp "Response the recuperation level status";
CM_ SG_ 824 VCU_VehRngUndrWarn "Total range low";
CM_ SG_ 824 VCU_VehRng "Total range for display";
CM_ SG_ 824 VCU_IpedalCreepCfgResp "Response of the creep control status when Ipedal on";
CM_ SG_ 824 VCU_BattSocUndrWarn "BMS SOC low";
CM_ SG_ 824 VCU_VehPwr "Actual power of vehicle";
CM_ SG_ 952 VCU_AccurRngConspAccumAvg "Accurate range Average electric consumption for display";
CM_ SG_ 952 VCU_AccurHMIModeCmd "Accurate range HMI mode display command";
CM_ SG_ 952 VCU_AccurRngAvail "Accurate range  Available";
CM_ SG_ 952 VCU_EcoPlusMod "EcoPlus mode is activated";
CM_ SG_ 952 VCU_ChgButtonStDsp "Charging button state to display";
CM_ SG_ 952 VCU_RecpLevelstRespL "Actual Recperation level";
CM_ SG_ 952 VCU_DspChgCurrKA "Display charge current for kA level";
CM_ SG_ 952 VCU_AccPdlLvlResp "Actual acceleration pedal level ";
CM_ SG_ 952 VCU_Err2NoticeFlag "Lever2 Error for VCU Popup flag";
CM_ SG_ 952 VCU_ErrNoticeOperationFlag "Operation flag for VCU error notice";
CM_ SG_ 952 VCU_ErrNotice "VCU error notice";
CM_ SG_ 952 VCU_ThermalMsgWarnOperationFlag "Operation flag for VCU_ThermalMsgWarn";
CM_ SG_ 952 VCU_HVAPUTotalPwrAct "VCU calculate HV Auxiliary total Power(HVH+PTC+ECP+DCDC) to BMS";
CM_ SG_ 952 VCU_3_CRC "E2E Profile 5 CRC";
CM_ SG_ 952 VCU_3_Counter "E2E Profile 5 Counter";
CM_ SG_ 952 VCU_BattCapColorEff "For ICM to display the color effect of HV battery capacity";
CM_ SG_ 952 VCU_EMS_AccPedalActPst_Disp "Current accelerate pedal actual position";
CM_ SG_ 812 BMS_Err2NoticeFlag "Lever2 Error for BMS Popup?flag";
CM_ SG_ 812 BMS_ErrNoticeOperationFlag "Operation flag for BMS error notice";
CM_ SG_ 812 BMS_ErrNotice "BMS error notice";
CM_ SG_ 812 BMS_BattSocDisp "Average SOC of battery pack for display";
CM_ SG_ 812 BMS_FaultLampInd "Warning indicator to lighten fault lamp (Malfunction Indication Lamp, MIL)";
CM_ SG_ 812 BMS_ChgSOCRespAvail "To indicate if Charge SOC of HV battery is available";
CM_ SG_ 812 BMS_ChgSOCResp "Charge SOC response of HV battery to VCU for display";
CM_ SG_ 812 BMS_ChgComplRemHour "Charge completed time for hour part for display";
CM_ SG_ 812 BMS_ChgComplRemMinute "Charge completed time for minute part for display";
CM_ SG_ 812 BMS_ChgmodeSt "nan";
CM_ SG_ 812 BMS_ChgmodeAvail "nan";
CM_ SG_ 408 BMC_HVBattSt "working state of HV battery system";
CM_ SG_ 408 BMC_BattCurr "actual current of battery";
CM_ SG_ 408 BMC_BattVolt "actual voltage of battery pack (inside of main relay)";
CM_ SG_ 408 BMC_ThermalRunawayErr "thermal runaway error alarm";
CM_ SG_ 408 BMC_LvPwrSysMsgWarn "BMS detect 12V power system , if the voltage can not support HV relay power up. BMS giveÂ Â  messages warn on ICM";
CM_ SG_ 888 BMC_HVBattElec "Max electricity of Battery";
CM_ SG_ 888 BMC_BattSoe "Average SOE of battery pack";
CM_ SG_ 888 BMC_HealCheckNotice "Health check notice";
CM_ SG_ 888 BMC_ChgFulNotice "Charge Full Notice";
CM_ SG_ 888 BMC_InslStChkMsgWarn "Warning message to display the insulation checking status";
CM_ SG_ 1835 IDC_Diag_Request "Diagnostic physical request";
CM_ SG_ 1359 CCU_NMNodeAddress "CCU node address";
CM_ SG_ 1359 CCU_NMDataField "CCU Network management data";
CM_ SG_ 1359 CCU_PNCInformation0 "PNC Information";
CM_ SG_ 1359 CCU_PNCInformation1 "PNC Information";
CM_ SG_ 2015 Fun_Diag_Request "Diagnostic function request";
CM_ SG_ 512 KAE_phone_Number "Phone_Numberbit0-3:phone number 1bit4-7:phone number2¡­...bit40-bit43:phone number11bit44-bit47:0000Linear:-resolution: 1 per bit-offset:0";
CM_ SG_ 512 KAE_KeyToken "TokenCode for account logon  ";
CM_ SG_ 403 ADC_ICMADASFailureLamp "ADAS Failure Indicator light, it turns on when more than two ADAS-systems fail";
CM_ SG_ 403 ADC_HFIconColor "HandFree Icon Color";
CM_ SG_ 403 ADC_1_CRC "E2E Profile 5 CRC";
CM_ SG_ 403 ADC_1_Counter "E2E Profile 5 Counter";
CM_ SG_ 403 ADC_ACCMode "This signal indicates ACC(Adaptive cruise control)status";
CM_ SG_ 403 ADC_ISLC_ConfirmSt "ISLC Style confirm Style";
CM_ SG_ 403 ADC_ACCTakeOverReq "ACC(Adaptive Cruise Control) request for driver take over";
CM_ SG_ 403 ADC_ISLCSt "This signal indicates if the ISLC(Intelligence Speed Limit Control) is activated";
CM_ SG_ 403 ADC_TimeGapSet "The set timeGap from driver, should be displayed to driver and if the set value changes";
CM_ SG_ 403 ADC_ILC_EnableSt "ILC Enable State";
CM_ SG_ 403 ADC_ILOA_EnableSt "ILOA enable status";
CM_ SG_ 403 ADC_ICMADASFailureText "ADAS Failure Text";
CM_ SG_ 403 ADC_ICMADASWarnText "ADAS Warn Text";
CM_ SG_ 403 ADC_SpeedLimitIconSt "Speed Limit Icon State";
CM_ SG_ 403 ADC_ICMWarnCardSt "Warn Card State";
CM_ SG_ 403 ADC_ICAIconColor "ICA Icon Color";
CM_ SG_ 403 ADC_ICMPromptWarn "Prompt Warn";
CM_ SG_ 403 ADC_NDAIconColor "NDA Icon Color";
CM_ SG_ 403 ADC_ACUVoiceWarn "Voice Warn";
CM_ SG_ 403 ADC_NDAStateIcon "NDA State Icon";
CM_ SG_ 403 ADC_SpeedLimitIcon "Speed Limit Icon";
CM_ SG_ 403 ADC_ICANDAIconAngle "ICA NDA Icon Angle";
CM_ SG_ 403 ADC_ACCTargetSpeedCard "Cruise Target Speed Card";
CM_ SG_ 403 ADC_ACCIconColor "ACC Icon Color";
CM_ SG_ 411 ADC_RCTAWarnRight " the vehicle right warning in the RCTA feature";
CM_ SG_ 411 ADC_RCTAWarnLeft " the vehicle left warning in the RCTA feature";
CM_ SG_ 411 ADC_FCWAssistType "This signal indicates if the FCW(Front Collision Warning) Assist Type";
CM_ SG_ 411 ADC_FCWFaultSt "This signal indicates if the FCW(Front Collision Warning) fault status";
CM_ SG_ 411 ADC_FCWPreWarn "Visual and Audio warning if the FCW (Imminent Warning) intervents";
CM_ SG_ 411 ADC_FCWLatentWarn "Visual warning if the FCW (Alert Warning) intervents";
CM_ SG_ 411 ADC_FCWWarmDistance "FCW warming distance";
CM_ SG_ 411 ADC_AEBTarObjType "AEB Target Object Type";
CM_ SG_ 411 ADC_AEBInterventionSt "This signal indicates if the AEB(Auto Emerrgency Braking) intervents";
CM_ SG_ 411 ADC_DOWAudioWarnFR "Front right door speaker warning";
CM_ SG_ 411 ADC_DOWAudioWarnFL "Front left door speaker warning";
CM_ SG_ 411 ADC_DOWAudioWarnRR "Rear right door speaker warning";
CM_ SG_ 411 ADC_DOWAudioWarnRL "Rear left door speaker warning";
CM_ SG_ 411 ADC_DOWIALWarnFR "Front right door light warning ";
CM_ SG_ 411 ADC_DOWIALWarnRR "Rear right door light warning ";
CM_ SG_ 411 ADC_BSDLCASt "BSD-LCA Function status";
CM_ SG_ 411 ADC_RCTASt "RCTA Function status";
CM_ SG_ 411 ADC_RCTAAssistType "RCTA assist type request";
CM_ SG_ 411 ADC_DOWSt "DOW Function state";
CM_ SG_ 411 ADC_RCWSt "RCW(rear collision warning ) feature status";
CM_ SG_ 411 ADC_FCTASt "FCTA feature status";
CM_ SG_ 411 ADC_FCTAAssistType "FCTA assist type request";
CM_ SG_ 411 ADC_FCTAWarnL "FCTA warning left";
CM_ SG_ 411 ADC_FCTAWarnR "FCTA warning right";
CM_ SG_ 411 ADC_LDS_LaneAssistType "operation mode of LDS";
CM_ SG_ 411 ADC_IHBC_EnableSt "IHBC enable status";
CM_ SG_ 411 ADC_TSR_EnableSt "TSR enable status";
CM_ SG_ 411 ADC_TSR__AudioWarn_EnableSt "TSR warn enable status";
CM_ SG_ 411 ADC_ELK_EnableSt "ELK Enable State";
CM_ SG_ 411 ADC_ESA_EnableSt "ESA Enable State";
CM_ SG_ 411 ADC_AES_EnableSt "AES Enable State";
CM_ SG_ 411 ADC_TSR_SpdLimit "TSR(Traffic Sign Recognition)Speed limit values";
CM_ SG_ 411 ADC_TSR_SpdLimitUnit "TSR(Traffic Sign Recognition) speed limit unit";
CM_ SG_ 419 ADC_AssistParaSwitchReq "Request EPS Switch Assist Parameter to LKA mode";
CM_ SG_ 419 ADC_AEBFaultSt "This signal indicates the AEB(Auto Emerrgency Braking) fault status";
CM_ SG_ 419 ADC_AEBOffSt "This signal indicates if the AEB(Auto Emerrgency Braking) is deactivated";
CM_ SG_ 419 ADC_AEBInterventionSt "This signal indicates if the AEB(Auto Emerrgency Braking) intervents";
CM_ SG_ 419 ADC_4_FreshnessValue "nan";
CM_ SG_ 419 ADC_4_MAC_Check "nan";
CM_ SG_ 404 ADC_ICMWarnCardSt_B "ICM Warn Card State";
CM_ SG_ 404 ADC_ICMPromptWarn_B "ICM Prompt Warn";
CM_ SG_ 404 ADC_1_B_FreshnessValue "nan";
CM_ SG_ 404 ADC_1_B_MAC_Check "nan";
CM_ SG_ 437 IFC_1_CRC "E2E Profile 5 CRC";
CM_ SG_ 437 IFC_1_Counter "E2E Profile 5 Counter";
CM_ SG_ 437 IFC_ICMWarnCardSt "IFC Warn Card State Request";
CM_ SG_ 437 IFC_ICMPromptWarn "IFC Prompt Warn Request";
CM_ SG_ 773 WCM_ChargingSt "Charging is ongoing or stopped";
CM_ SG_ 773 WCM_ControlResult "WCM enable/disable status";
CM_ SG_ 773 WCM_FailureSt "WCM failure status";
CM_ SG_ 773 WCM_Reminder "Reminder the Phone left";
CM_ SG_ 1078 ETC_DismountSt "OBU dismount status";
CM_ SG_ 1078 ETC_SelfcheckSt "OBU Self check statue";
CM_ SG_ 1078 ETC_GateProperty "RSU gate property";
CM_ SG_ 1078 ETC_TradeType "RSU trade type";
CM_ SG_ 1078 ETC_SystemSt "OBU System status";
CM_ SG_ 1078 ETC_SysCfgst "ETC System Enable & Disable configuration status";
CM_ SG_ 1078 ETC_ICMDisplayCfgst "ETC infomation display on ICM function Enable & Disable configuration status";
CM_ SG_ 1078 ETC_BLEenableCfgst "ETC Bluetooth function Enable & Disable configuration status";
CM_ SG_ 1078 ETC_ActivSt "OBU Activate status";
CM_ SG_ 1078 ETC_TradeInfo "Trade infomation";
CM_ SG_ 345 CCU_IDC_SecSyn "nan";
CM_ SG_ 175 ADC_PAAChallenge1SBM "RPA Challenge SBM Singal1";
CM_ SG_ 175 ADC_PAAChallenge2SBM "RPA Challenge SBM Singal2";
CM_ SG_ 941 ADC_LowPowerfeedback "indicate ADC lowpower Mode state";
CM_ SG_ 941 ADC_HPAStrtgEndgPointInfo "This signal indicates the reasons for invalid starting and ending point";
CM_ SG_ 941 ADC_HPALearningProcessInfo "AVP controller will send this singal to show indications through HU to driver during learning process.";
CM_ SG_ 941 ADC_HPALearningFailedInfo "Learning failed reasons for HAVP learning results.";
CM_ SG_ 941 ADC_HPALrngDst "Learning distance calculated by AVP controller";
CM_ SG_ 941 ADC_HPAResRouteLeg "HAVP Residual route length";
CM_ SG_ 941 ADC_HPAUseActDis "HAVP Use the actual distance";
CM_ SG_ 941 ADC_HPAProcRat "HAVP drving process ratio";
CM_ SG_ 941 ADC_HPAUseTolTime "HAVP Total time of route use";
CM_ SG_ 941 ADC_ParkSlotChoiceL1 "Left No.1 Slot Type";
CM_ SG_ 941 ADC_IconTwinkle "APA Twinkle Remind";
CM_ SG_ 941 ADC_ParkSlotChoiceR1 "Right No.1 Slot Type";
CM_ SG_ 941 ADC_ParkSlotChoiceL2 "Left No.2 Slot Type";
CM_ SG_ 941 ADC_ParkSlotChoiceR2 "Right No.2 Slot Type";
CM_ SG_ 941 ADC_ParkSlotChoiceL3 "Left No.3 Slot Type";
CM_ SG_ 941 ADC_ParkSlotChoiceR3 "Right No.3 Slot Type";
CM_ SG_ 941 ADC_ParkSlotChoiceL4 "Left No.4 Slot Type";
CM_ SG_ 941 ADC_ParkSlotChoiceR4 "Right No.4 Slot Type";
CM_ SG_ 941 ADC_ParkSlotChoiceL5 "Left No.5 Slot Type";
CM_ SG_ 941 ADC_ParkSlotChoiceR5 "Right No.5 Slot Type";
CM_ SG_ 941 ADC_ParkSlotChoiceL6 "Left No.6 Slot Type";
CM_ SG_ 941 ADC_ParkSlotChoiceR6 "Right No.6 Slot Type";
CM_ SG_ 941 ADC_ParkSlotChoiceL7 "Left No.7 Slot Type";
CM_ SG_ 941 ADC_ParkSlotChoiceR7 "Right No.7 Slot Type";
CM_ SG_ 941 ADC_ParkSlotChoiceL8 "Left No.8 Slot Type";
CM_ SG_ 941 ADC_ParkSlotChoiceR8 "Right No.8 Slot Type";
CM_ SG_ 941 ADC_SlotSelectFebk "APA Slot Select Feedback";
CM_ SG_ 941 ADC_AVPParkSlotInfo "AVP Slot's Length or Width";
CM_ SG_ 941 ADC_SwitchStShow "APA Switch status Show";
CM_ SG_ 941 FAPA_RPAShortPresSuppSt "RPA short press support status";
CM_ SG_ 941 ADC_HPASwitchStShow "HAVP Switch status Show  ";
CM_ SG_ 941 ADC_AVPSwitchStShow "PAVP Switch status Show  ";
CM_ SG_ 941 ADC_HPALearningPathType1 "Path type for path 1,0x0 represents invalid path";
CM_ SG_ 941 ADC_HPALearningLotType1 "Lot type for path 1,0x0 represents invalid path";
CM_ SG_ 941 ADC_HPALearningPathNum1 "Path number 1,0x0 represents invalid path";
CM_ SG_ 941 ADC_HPAPathLearnRate1 "Learnrate for path1";
CM_ SG_ 941 ADC_HPAPathSt1 "Status for path1";
CM_ SG_ 941 ADC_HPAPath1Src "Path number 1 is Learn or share";
CM_ SG_ 941 ADC_HPAPathDst1 "Learned path1 distance";
CM_ SG_ 941 ADC_HPALearningPathNum2 "Path number 2,0x0 represents invalid path";
CM_ SG_ 941 ADC_HPAHAVPPathLearnRate2 "Learnrate for path2";
CM_ SG_ 941 ADC_HPALearningPathType2 "Path type for path 2,0x0 represents invalid path";
CM_ SG_ 941 ADC_HPALearningLotType2 "Lot type for path 2,0x0 represents invalid path";
CM_ SG_ 941 ADC_HPAPathSt2 "Status for path2";
CM_ SG_ 941 ADC_HPAPath2Src "Path number 2 is Learn or share";
CM_ SG_ 941 ADC_HPAPathDst2 "Learned path2 distance";
CM_ SG_ 941 ADC_HPAPath1MatGpsSucces "The Path matches the geofence successfully";
CM_ SG_ 941 ADC_HPAPath2MatGpsSucces "The Path matches the geofence successfully";
CM_ SG_ 941 ADC_HPALearningPathType3 "Path type for path 3,0x0 represents invalid path";
CM_ SG_ 941 ADC_HPALearningPathNum3 "Path number 3,0x0 represents invalid path";
CM_ SG_ 941 ADC_HPAPathLearnRate3 "Learnrate for path3";
CM_ SG_ 941 ADC_HPALearningLotType3 "Lot type for path 3,0x0 represents invalid path";
CM_ SG_ 941 ADC_HPAPathSt3 "Status for path3";
CM_ SG_ 941 ADC_HPAPath3Src "Path number 3 is Learn or share";
CM_ SG_ 941 ADC_HPAPathDst3 "Learned path3 distance";
CM_ SG_ 941 ADC_HPALearningPathNum4 "Path number 4,0x0 represents invalid path";
CM_ SG_ 941 ADC_HPAPathLearnRate4 "Learnrate for path4";
CM_ SG_ 941 ADC_HPALearningPathType4 "Path type for path 4,0x0 represents invalid path";
CM_ SG_ 941 ADC_HPALearningLotType4 "Lot type for path 4,0x0 represents invalid path";
CM_ SG_ 941 ADC_HPAPathSt4 "Status for path4";
CM_ SG_ 941 ADC_HPAPath4Src "Path number 4 is Learn or share";
CM_ SG_ 941 ADC_HPAPathDst4 "Learned path4 distance";
CM_ SG_ 941 ADC_HPAPath3MatGpsSucces "The Path matches the geofence successfully";
CM_ SG_ 941 ADC_HPAPath4MatGpsSucces "The Path matches the geofence successfully";
CM_ SG_ 941 ADC_HPALearningPathNum5 "Path number 5,0x0 represents invalid path";
CM_ SG_ 941 ADC_HPAPathLearnRate5 "Learnrate for path5";
CM_ SG_ 941 ADC_HPALearningPathType5 "Path type for path 5,0x0 represents invalid path";
CM_ SG_ 941 ADC_HPALearningLotType5 "Lot type for path 5,0x0 represents invalid path";
CM_ SG_ 941 ADC_HPAPathSt5 "Status for path5";
CM_ SG_ 941 ADC_HPAPath5Src "Path number 5 is Learn or share";
CM_ SG_ 941 ADC_HPAPathDst5 "Learned path5 distance";
CM_ SG_ 941 ADC_HPALearningPathNum6 "Path number 6,0x0 represents invalid path";
CM_ SG_ 941 ADC_HPAPathLearnRate6 "Learnrate for path6";
CM_ SG_ 941 ADC_HPALearningPathType6 "Path type for path 6,0x0 represents invalid path";
CM_ SG_ 941 ADC_HPALearningLotType6 "Lot type for path 6,0x0 represents invalid path";
CM_ SG_ 941 ADC_HPAPathSt6 "Status for path6";
CM_ SG_ 941 ADC_HPAPath6Src "Path number 6 is Learn or share";
CM_ SG_ 941 ADC_HPAPathDst6 "Learned path6 distance";
CM_ SG_ 941 ADC_HPAPath5MatGpsSucces "The Path matches the geofence successfully";
CM_ SG_ 941 ADC_HPAPath6MatGpsSucces "The Path matches the geofence successfully";
CM_ SG_ 941 ADC_HPALearningPathNum7 "Path number 7,0x0 represents invalid path";
CM_ SG_ 941 ADC_HPAPathLearnRate7 "Learnrate for path7";
CM_ SG_ 941 ADC_HPALearningPathType7 "Path type for path 7,0x0 represents invalid path";
CM_ SG_ 941 ADC_HPALearningLotType7 "Lot type for path 7,0x0 represents invalid path";
CM_ SG_ 941 ADC_HPAPathSt7 "Status for path7";
CM_ SG_ 941 ADC_HPAPath7Src "Path number 7 is Learn or share";
CM_ SG_ 941 ADC_HPAPathDst7 "Learned path7 distance";
CM_ SG_ 941 ADC_HPALearningPathNum8 "Path number 8,0x0 represents invalid path";
CM_ SG_ 941 ADC_HPAPathLearnRate8 "Learnrate for path8";
CM_ SG_ 941 ADC_HPALearningPathType8 "Path type for path 8,0x0 represents invalid path";
CM_ SG_ 941 ADC_HPALearningLotType8 "Lot type for path 8,0x0 represents invalid path";
CM_ SG_ 941 ADC_HPAPPathSt8 "Status for path8";
CM_ SG_ 941 ADC_HPAPath8Src "Path number 8 is Learn or share";
CM_ SG_ 941 ADC_HPAPathDst8 "Learned path8 distance";
CM_ SG_ 941 ADC_HPAPath7MatGpsSucces "The Path matches the geofence successfully";
CM_ SG_ 941 ADC_HPAPath8MatGpsSucces "The Path matches the geofence successfully";
CM_ SG_ 941 ADC_HPALearningPathNum9 "Path number 9,0x0 represents invalid path";
CM_ SG_ 941 ADC_HPAPathLearnRate9 "Learnrate for path9";
CM_ SG_ 941 ADC_HPALearningPathType9 "Path type for path 9,0x0 represents invalid path";
CM_ SG_ 941 ADC_HPALearningLotType9 "Lot type for path 9,0x0 represents invalid path";
CM_ SG_ 941 ADC_HPAPathSt9 "Status for path9";
CM_ SG_ 941 ADC_HPAPath9Src "Path number 9 is Learn or share";
CM_ SG_ 941 ADC_HPAPathDst9 "Learned path9 distance";
CM_ SG_ 941 ADC_HPALearningPathNum10 "Path number 10,0x0 represents invalid path";
CM_ SG_ 941 ADC_HPAPathLearnRate10 "Learnrate for path10";
CM_ SG_ 941 ADC_HPALearningPathType10 "Path type for path 10,0x0 represents invalid path";
CM_ SG_ 941 ADC_HPALearningLotType10 "Lot type for path 10,0x0 represents invalid path";
CM_ SG_ 941 ADC_HPAPathSt10 "Status for path10";
CM_ SG_ 941 ADC_HPAPath10Src "Path number 10 is Learn or share";
CM_ SG_ 941 ADC_HPAPathDst10 "Learned path10 distance";
CM_ SG_ 941 ADC_HPAPath9MatGpsSucces "The Path matches the geofence successfully";
CM_ SG_ 941 ADC_HPAPath10MatGpsSucces "The Path matches the geofence successfully";
CM_ SG_ 835 OMS_SysErrSt_ADC "occupancy monitoring system error status";
CM_ SG_ 835 DMS_SysErrSt_ADC "Driver monitoring system error status";
CM_ SG_ 835 DMS_FaceID_ADC "FaceID";
CM_ SG_ 835 PCS_VoiceReq "Voice request, used to indicate whiceh voice should be played";
CM_ SG_ 835 PCS_ER_QuitReq "Event record quit request ";
CM_ SG_ 835 PCS_ER_EnterConfirm "Event record enter comfirm ";
CM_ SG_ 835 PCS_EventRecordSt "Indication event record turn off/on status ";
CM_ SG_ 835 PCS_MirrorPageDownButton "Mirror page down button ";
CM_ SG_ 835 PCS_SystemSt "System status ";
CM_ SG_ 835 ADC_DPMessagePushSt "DP Message Push Staus";
CM_ SG_ 835 PAS_BattVoltErrFlag "Error flag of IGN voltage.";
CM_ SG_ 835 PAS_CtrlModulerrFlag "Error flag of EEPROM.";
CM_ SG_ 835 PAS_FSRSnsErrFlag "Error flag of front right side sensor";
CM_ SG_ 835 PAS_FSLSnsErrFlag "Error flag of front left side sensor";
CM_ SG_ 835 PAS_FLMidSnsErrFlag "Error flag of front left middle sensor";
CM_ SG_ 835 PAS_FRMidSnsErrFlag "Error flag of front right middle sensor";
CM_ SG_ 835 PAS_FLSnsErrFlag "Error flag of front left sensor";
CM_ SG_ 835 PAS_FRSnsErrFlag "Error flag of front right sensor";
CM_ SG_ 835 PAS_RSRSnsErrFlag "Error flag of rear right side sensor";
CM_ SG_ 835 PAS_RSLSnsErrFlag "Error flag of rear left side sensor";
CM_ SG_ 835 PAS_RLSnsErrFlag "Error flag of rear left sensor";
CM_ SG_ 835 PAS_RRSnsErrFlag "Error flag of rear right sensor";
CM_ SG_ 835 PAS_RLMidSnsErrFlag "Error flag of rear leftt middle sensor";
CM_ SG_ 835 PAS_RRMidSnsErrFlag "Error flag of rear right middle sensor";
CM_ SG_ 835 PCS_SoundReminderSt "Sound reminder status ";
CM_ SG_ 835 PCS_HelpMenuSt "Help menu status ";
CM_ SG_ 835 PCS_ReturnSt "Return status ";
CM_ SG_ 835 PCS_RightBlindSpotViewSt "Indication right side blind spot view turn off/on status";
CM_ SG_ 835 PCS_LeftBlindSpotViewSt "Indication left side blind spot view turn off/on status";
CM_ SG_ 835 PCS_FrontRightCameraFail "Front right camera failure";
CM_ SG_ 835 PCS_FrontLeftCameraFail "Front left camera failure";
CM_ SG_ 835 ADC_ACU_DisplayReq "AVM display request";
CM_ SG_ 835 PCS_HMIIndex "HMI index,used to indicate the current HMI index";
CM_ SG_ 835 PAS_SystemType "PAS(Parking Assistant Sytem)  system type";
CM_ SG_ 835 PAS_WarnTone "Warning tone";
CM_ SG_ 835 PAS_ButtonPress "RPA button press status";
CM_ SG_ 835 PAS_SideZoneStatusF "Front side zone status ";
CM_ SG_ 835 PAS_SideZoneStatusR "Rear side zone status";
CM_ SG_ 835 PAS_RRMidDistance "Distance from rear right middle sensor  ";
CM_ SG_ 835 PAS_RLMidDistance "Distance from rear left middle sensor  ";
CM_ SG_ 835 PAS_RRDistance "Distance from rear right  sensor  ";
CM_ SG_ 835 PAS_RLDistance "Distance from rear left sensor ";
CM_ SG_ 835 PAS_RSLSideDistance "Distance from rear left side sensor ";
CM_ SG_ 835 PAS_RSRSideDistance "Distance from rear right side sensor ";
CM_ SG_ 835 PAS_FRDistance "Distance from front right sensor  ";
CM_ SG_ 835 PAS_FLDistance "Distance from front left sensor  ";
CM_ SG_ 835 PAS_FRMidDistance "Distance from front right middle sensor  ";
CM_ SG_ 835 PAS_FLMidDistance "Distance from front left middle sensor  ";
CM_ SG_ 835 PAS_FSRSideDistance "Distance from front right side sensor ";
CM_ SG_ 835 PAS_FSLSideDistance "Distance from front left side sensor ";
CM_ SG_ 835 PAS_Mode "Ultrasonic Sensor Working Mode";
CM_ SG_ 835 PCS_RightCameraFail "Right camera failure";
CM_ SG_ 835 PCS_RearCameraFail "Rear camera failure";
CM_ SG_ 835 PCS_CalibrateSt "Indication the calibration status";
CM_ SG_ 835 PCS_SystemType "System type";
CM_ SG_ 835 PCS_SingleViewInd "Single view indication, used to indicate the current single view";
CM_ SG_ 835 PCS_MODEnalbe "Indicate status of MOD(Moving Object Detection) function";
CM_ SG_ 835 PCS_3DEnalbe "Indicate status of 3D SVM function";
CM_ SG_ 835 PCS_OperationSt "Used to indicate the current status of PCS";
CM_ SG_ 835 PCS_ACU_DisplayReq "ACU display request";
CM_ SG_ 835 PCS_PASButtonPress "PAS button press status";
CM_ SG_ 835 PCS_VRSwitchFailSt "PCS VR Switch Fail State";
CM_ SG_ 835 PCS_FrontCameraFail "Front camera failure";
CM_ SG_ 835 PCS_LeftCameraFail "Left camera failure";
CM_ SG_ 549 ADC_RAEBWorkSts "RAEB Work status ";
CM_ SG_ 549 ADC_PAARecInd "Parking Recover indication";
CM_ SG_ 549 ADC_PAAQuitInd "Parking Quit indication";
CM_ SG_ 549 ADC_PAADrvReq "Parking Driver Request";
CM_ SG_ 549 ADC_SBMAuthst "PAA Authst with SBM";
CM_ SG_ 549 ADC_APKDisplayReq "APK display request";
CM_ SG_ 549 ADC_PAAVRSwitchFailSt "PAA VR Switch Fail State";
CM_ SG_ 549 ADC_PAAFuncSt "PAA working functions inaication signal";
CM_ SG_ 549 ADC_APABackParkDisplayReq "APA Background Parking For AVNT Display";
CM_ SG_ 549 ADC_APAMessagePushSt "APA Message Push Staus";
CM_ SG_ 549 ADC_HPAMessagePushSt "HPA Message  Push Staus";
CM_ SG_ 549 ADC_AVPMessagePushSt "AVP Message  Push Staus";
CM_ SG_ 549 ADC_PAADrvInteraction "PAA Driver Interaction signal";
CM_ SG_ 154 CCU_IMMO "CCU distribute anti-theft information";
CM_ SG_ 120 CCU_SEC_KEY_Defaultencoding "CCU distribute key and default_encoding";
BA_DEF_ BO_  "E2EProfile" STRING ;
BA_DEF_ BO_  "E2EDataLength" INT 0 65535;
BA_DEF_ BO_  "E2EDataId" INT 0 65535;
BA_DEF_ SG_  "Remark" STRING ;
BA_DEF_ SG_  "EventCommandSignal" ENUM  "No","Yes";
BA_DEF_ SG_  "GatewayedSignals" ENUM  "No","Yes";
BA_DEF_ SG_  "GenSigTimeoutValue" HEX 0 0;
BA_DEF_ SG_  "GenSigStartValue" HEX 0 0;
BA_DEF_ SG_  "GenSigInvalidValue" HEX 0 0;
BA_DEF_ SG_  "GenSigInactiveValue" HEX 0 0;
BA_DEF_ SG_  "GenSigSendType" ENUM  "Trigger","Passive","Cyclic","OnWrite","OnWriteWithRepetition","OnChange","OnChangeWithRepetition","IfActive","IfActiveWithRepetition","NoSigSendType";
BA_DEF_ BO_  "GenMsgCycleTimeFast" INT 0 0;
BA_DEF_ BO_  "GenMsgCycleTime" INT 0 0;
BA_DEF_ BO_  "GenMsgSendType" ENUM  "Periodic","Event","IfActive","POE","PA","FixedPeriodic","Event","EnabledPeriodic","NotUsed","NotUsed","EventPeriodic","NotUsed","NotUsed","NoMsgSendType";
BA_DEF_ BO_  "VFrameFormat" ENUM  "StandardCAN","ExtendedCAN","reserved","reserved","reserved","reserved","reserved","reserved","reserved","reserved","reserved","reserved","reserved","reserved","StandardCAN_FD","ExtendedCAN_FD";
BA_DEF_ BO_  "CANFD_BRS" ENUM  "0","1";
BA_DEF_ SG_  "SystemSignalLongSymbol" STRING ;
BA_DEF_DEF_  "E2EProfile" "";
BA_DEF_DEF_  "E2EDataLength" 0;
BA_DEF_DEF_  "E2EDataId" 0;
BA_DEF_DEF_  "Remark" "";
BA_DEF_DEF_  "EventCommandSignal" "";
BA_DEF_DEF_  "GatewayedSignals" "";
BA_DEF_DEF_  "GenSigTimeoutValue" 0;
BA_DEF_DEF_  "GenSigStartValue" 0;
BA_DEF_DEF_  "GenSigInvalidValue" 0;
BA_DEF_DEF_  "GenSigInactiveValue" 0;
BA_DEF_DEF_  "GenSigSendType" "";
BA_DEF_DEF_  "GenMsgCycleTimeFast" 0;
BA_DEF_DEF_  "GenMsgCycleTime" 0;
BA_DEF_DEF_  "GenMsgSendType" "";
BA_DEF_DEF_  "VFrameFormat" "";
BA_DEF_DEF_  "CANFD_BRS" "";
BA_DEF_DEF_  "SystemSignalLongSymbol" "";
BA_ "CANFD_BRS" BO_ 295 1;
BA_ "GenMsgCycleTime" BO_ 295 500;
BA_ "GenMsgCycleTimeFast" BO_ 295 40;
BA_ "GenMsgSendType" BO_ 295 3;
BA_ "VFrameFormat" BO_ 295 14;
BA_ "CANFD_BRS" BO_ 400 1;
BA_ "GenMsgCycleTime" BO_ 400 100;
BA_ "GenMsgSendType" BO_ 400 0;
BA_ "VFrameFormat" BO_ 400 14;
BA_ "E2EProfile" BO_ 615 "P05";
BA_ "E2EDataLength" BO_ 615 448;
BA_ "E2EDataId" BO_ 615 1025;
BA_ "CANFD_BRS" BO_ 615 1;
BA_ "GenMsgCycleTime" BO_ 615 20;
BA_ "GenMsgSendType" BO_ 615 0;
BA_ "VFrameFormat" BO_ 615 14;
BA_ "E2EProfile" BO_ 352 "P05";
BA_ "E2EDataLength" BO_ 352 448;
BA_ "E2EDataId" BO_ 352 1033;
BA_ "CANFD_BRS" BO_ 352 1;
BA_ "GenMsgCycleTime" BO_ 352 10;
BA_ "GenMsgSendType" BO_ 352 0;
BA_ "VFrameFormat" BO_ 352 14;
BA_ "E2EProfile" BO_ 611 "P05";
BA_ "E2EDataLength" BO_ 611 448;
BA_ "E2EDataId" BO_ 611 1041;
BA_ "CANFD_BRS" BO_ 611 1;
BA_ "GenMsgCycleTime" BO_ 611 20;
BA_ "GenMsgSendType" BO_ 611 0;
BA_ "VFrameFormat" BO_ 611 14;
BA_ "CANFD_BRS" BO_ 886 1;
BA_ "GenMsgCycleTime" BO_ 886 200;
BA_ "GenMsgSendType" BO_ 886 0;
BA_ "VFrameFormat" BO_ 886 14;
BA_ "E2EProfile" BO_ 618 "P05";
BA_ "E2EDataLength" BO_ 618 256;
BA_ "E2EDataId" BO_ 618 1049;
BA_ "CANFD_BRS" BO_ 618 1;
BA_ "GenMsgCycleTime" BO_ 618 20;
BA_ "GenMsgSendType" BO_ 618 0;
BA_ "VFrameFormat" BO_ 618 14;
BA_ "E2EProfile" BO_ 939 "P05";
BA_ "E2EDataLength" BO_ 939 256;
BA_ "E2EDataId" BO_ 939 1036;
BA_ "CANFD_BRS" BO_ 939 1;
BA_ "GenMsgCycleTime" BO_ 939 100;
BA_ "GenMsgSendType" BO_ 939 0;
BA_ "VFrameFormat" BO_ 939 14;
BA_ "CANFD_BRS" BO_ 368 1;
BA_ "GenMsgCycleTime" BO_ 368 100;
BA_ "GenMsgSendType" BO_ 368 0;
BA_ "VFrameFormat" BO_ 368 14;
BA_ "E2EProfile" BO_ 864 "P05";
BA_ "E2EDataLength" BO_ 864 448;
BA_ "E2EDataId" BO_ 864 777;
BA_ "CANFD_BRS" BO_ 864 1;
BA_ "GenMsgCycleTime" BO_ 864 100;
BA_ "GenMsgSendType" BO_ 864 0;
BA_ "VFrameFormat" BO_ 864 14;
BA_ "E2EProfile" BO_ 872 "P05";
BA_ "E2EDataLength" BO_ 872 448;
BA_ "E2EDataId" BO_ 872 801;
BA_ "CANFD_BRS" BO_ 872 1;
BA_ "GenMsgCycleTime" BO_ 872 100;
BA_ "GenMsgSendType" BO_ 872 0;
BA_ "VFrameFormat" BO_ 872 14;
BA_ "CANFD_BRS" BO_ 880 1;
BA_ "GenMsgCycleTime" BO_ 880 200;
BA_ "GenMsgSendType" BO_ 880 0;
BA_ "VFrameFormat" BO_ 880 14;
BA_ "E2EProfile" BO_ 824 "P05";
BA_ "E2EDataLength" BO_ 824 448;
BA_ "E2EDataId" BO_ 824 841;
BA_ "CANFD_BRS" BO_ 824 1;
BA_ "GenMsgCycleTime" BO_ 824 100;
BA_ "GenMsgSendType" BO_ 824 0;
BA_ "VFrameFormat" BO_ 824 14;
BA_ "E2EProfile" BO_ 952 "P05";
BA_ "E2EDataLength" BO_ 952 448;
BA_ "E2EDataId" BO_ 952 849;
BA_ "CANFD_BRS" BO_ 952 1;
BA_ "GenMsgCycleTime" BO_ 952 200;
BA_ "GenMsgSendType" BO_ 952 0;
BA_ "VFrameFormat" BO_ 952 14;
BA_ "CANFD_BRS" BO_ 812 1;
BA_ "GenMsgCycleTime" BO_ 812 100;
BA_ "GenMsgSendType" BO_ 812 0;
BA_ "VFrameFormat" BO_ 812 14;
BA_ "CANFD_BRS" BO_ 408 1;
BA_ "GenMsgCycleTime" BO_ 408 100;
BA_ "GenMsgSendType" BO_ 408 0;
BA_ "VFrameFormat" BO_ 408 14;
BA_ "CANFD_BRS" BO_ 888 1;
BA_ "GenMsgCycleTime" BO_ 888 100;
BA_ "GenMsgSendType" BO_ 888 0;
BA_ "VFrameFormat" BO_ 888 14;
BA_ "CANFD_BRS" BO_ 1835 1;
BA_ "GenMsgSendType" BO_ 1835 1;
BA_ "VFrameFormat" BO_ 1835 14;
BA_ "CANFD_BRS" BO_ 1359 1;
BA_ "GenMsgCycleTime" BO_ 1359 200;
BA_ "GenMsgSendType" BO_ 1359 0;
BA_ "VFrameFormat" BO_ 1359 14;
BA_ "CANFD_BRS" BO_ 2015 1;
BA_ "GenMsgSendType" BO_ 2015 1;
BA_ "VFrameFormat" BO_ 2015 14;
BA_ "CANFD_BRS" BO_ 512 1;
BA_ "GenMsgCycleTime" BO_ 512 500;
BA_ "GenMsgCycleTimeFast" BO_ 512 40;
BA_ "GenMsgSendType" BO_ 512 3;
BA_ "VFrameFormat" BO_ 512 14;
BA_ "E2EProfile" BO_ 403 "P05";
BA_ "E2EDataLength" BO_ 403 448;
BA_ "E2EDataId" BO_ 403 1584;
BA_ "CANFD_BRS" BO_ 403 1;
BA_ "GenMsgCycleTime" BO_ 403 20;
BA_ "GenMsgSendType" BO_ 403 0;
BA_ "VFrameFormat" BO_ 403 14;
BA_ "CANFD_BRS" BO_ 411 1;
BA_ "GenMsgCycleTime" BO_ 411 20;
BA_ "GenMsgSendType" BO_ 411 0;
BA_ "VFrameFormat" BO_ 411 14;
BA_ "CANFD_BRS" BO_ 419 1;
BA_ "GenMsgCycleTime" BO_ 419 10;
BA_ "GenMsgSendType" BO_ 419 0;
BA_ "VFrameFormat" BO_ 419 14;
BA_ "CANFD_BRS" BO_ 404 1;
BA_ "GenMsgCycleTime" BO_ 404 100;
BA_ "GenMsgSendType" BO_ 404 0;
BA_ "VFrameFormat" BO_ 404 14;
BA_ "E2EProfile" BO_ 437 "P05";
BA_ "E2EDataLength" BO_ 437 512;
BA_ "E2EDataId" BO_ 437 1664;
BA_ "CANFD_BRS" BO_ 437 1;
BA_ "GenMsgCycleTime" BO_ 437 100;
BA_ "GenMsgSendType" BO_ 437 0;
BA_ "VFrameFormat" BO_ 437 14;
BA_ "CANFD_BRS" BO_ 773 1;
BA_ "GenMsgCycleTime" BO_ 773 200;
BA_ "GenMsgSendType" BO_ 773 0;
BA_ "VFrameFormat" BO_ 773 14;
BA_ "CANFD_BRS" BO_ 1078 1;
BA_ "GenMsgCycleTime" BO_ 1078 1000;
BA_ "GenMsgSendType" BO_ 1078 0;
BA_ "VFrameFormat" BO_ 1078 14;
BA_ "CANFD_BRS" BO_ 345 1;
BA_ "GenMsgCycleTime" BO_ 345 30000;
BA_ "GenMsgCycleTimeFast" BO_ 345 40;
BA_ "GenMsgSendType" BO_ 345 3;
BA_ "VFrameFormat" BO_ 345 14;
BA_ "CANFD_BRS" BO_ 175 1;
BA_ "GenMsgSendType" BO_ 175 1;
BA_ "VFrameFormat" BO_ 175 14;
BA_ "CANFD_BRS" BO_ 941 1;
BA_ "GenMsgCycleTime" BO_ 941 100;
BA_ "GenMsgSendType" BO_ 941 0;
BA_ "VFrameFormat" BO_ 941 14;
BA_ "CANFD_BRS" BO_ 835 1;
BA_ "GenMsgCycleTime" BO_ 835 100;
BA_ "GenMsgSendType" BO_ 835 0;
BA_ "VFrameFormat" BO_ 835 14;
BA_ "CANFD_BRS" BO_ 549 1;
BA_ "GenMsgCycleTime" BO_ 549 20;
BA_ "GenMsgSendType" BO_ 549 0;
BA_ "VFrameFormat" BO_ 549 14;
BA_ "CANFD_BRS" BO_ 154 1;
BA_ "GenMsgSendType" BO_ 154 1;
BA_ "VFrameFormat" BO_ 154 14;
BA_ "CANFD_BRS" BO_ 120 1;
BA_ "GenMsgSendType" BO_ 120 1;
BA_ "VFrameFormat" BO_ 120 14;
BA_ "GenSigSendType" SG_ 295 IL_IALFunctionCfgSt 0;
BA_ "EventCommandSignal" SG_ 295 IL_IALFunctionCfgSt 1;
BA_ "GenSigSendType" SG_ 295 IL_IALWorkSt 0;
BA_ "EventCommandSignal" SG_ 295 IL_IALWorkSt 1;
BA_ "GenSigSendType" SG_ 295 IL_IALBrightnessSetSt 0;
BA_ "EventCommandSignal" SG_ 295 IL_IALBrightnessSetSt 1;
BA_ "GenSigSendType" SG_ 295 IL_IALDriverModeCfgSt 0;
BA_ "EventCommandSignal" SG_ 295 IL_IALDriverModeCfgSt 1;
BA_ "GenSigSendType" SG_ 295 IL_IALColorSetSt 0;
BA_ "EventCommandSignal" SG_ 295 IL_IALColorSetSt 1;
BA_ "GenSigSendType" SG_ 295 IL_IALMusicModeCfgSt 0;
BA_ "EventCommandSignal" SG_ 295 IL_IALMusicModeCfgSt 1;
BA_ "GenSigSendType" SG_ 295 IALVoiceModeCfgSt 0;
BA_ "EventCommandSignal" SG_ 295 IALVoiceModeCfgSt 1;
BA_ "GenSigSendType" SG_ 400 UINM_DrvReqShft 1;
BA_ "GenSigStartValue" SG_ 400 UINM_DrvReqShft 5;
BA_ "GatewayedSignals" SG_ 400 UINM_DrvReqShft 0;
BA_ "EventCommandSignal" SG_ 400 UINM_DrvReqShft 0;
BA_ "GenSigSendType" SG_ 400 UINM_TurnLightSwSt 1;
BA_ "GenSigInvalidValue" SG_ 400 UINM_TurnLightSwSt 5;
BA_ "GatewayedSignals" SG_ 400 UINM_TurnLightSwSt 0;
BA_ "EventCommandSignal" SG_ 400 UINM_TurnLightSwSt 0;
BA_ "GenSigInvalidValue" SG_ 400 UINM_FrontWiperSwSt 7;
BA_ "GenSigSendType" SG_ 400 UINM_FrontWiperSwSt 1;
BA_ "EventCommandSignal" SG_ 400 UINM_FrontWiperSwSt 0;
BA_ "GenSigSendType" SG_ 400 UINM_FrontWasherSwSt 1;
BA_ "EventCommandSignal" SG_ 400 UINM_FrontWasherSwSt 0;
BA_ "EventCommandSignal" SG_ 615 BCS_RLWheelRotatedDirection 0;
BA_ "GatewayedSignals" SG_ 615 BCS_RLWheelRotatedDirection 0;
BA_ "GenSigSendType" SG_ 615 BCS_RLWheelRotatedDirection 1;
BA_ "EventCommandSignal" SG_ 615 BCS_RLWheelSpd 0;
BA_ "GatewayedSignals" SG_ 615 BCS_RLWheelSpd 0;
BA_ "GenSigSendType" SG_ 615 BCS_RLWheelSpd 1;
BA_ "GenSigSendType" SG_ 615 BCS_RRWheelSpdEdgesSum 1;
BA_ "GatewayedSignals" SG_ 615 BCS_RRWheelSpdEdgesSum 0;
BA_ "EventCommandSignal" SG_ 615 BCS_RRWheelSpdEdgesSum 0;
BA_ "GenSigSendType" SG_ 615 BCS_FRWheelSpdEdgesSum 1;
BA_ "GatewayedSignals" SG_ 615 BCS_FRWheelSpdEdgesSum 0;
BA_ "EventCommandSignal" SG_ 615 BCS_FRWheelSpdEdgesSum 0;
BA_ "GenSigSendType" SG_ 615 BCS_RRWheelRotatedDirection 1;
BA_ "GatewayedSignals" SG_ 615 BCS_RRWheelRotatedDirection 0;
BA_ "EventCommandSignal" SG_ 615 BCS_RRWheelRotatedDirection 0;
BA_ "GenSigSendType" SG_ 615 BCS_RRWheelSpd 1;
BA_ "GatewayedSignals" SG_ 615 BCS_RRWheelSpd 0;
BA_ "EventCommandSignal" SG_ 615 BCS_RRWheelSpd 0;
BA_ "GenSigSendType" SG_ 615 BCS_FRWheelRotatedDirection 1;
BA_ "GatewayedSignals" SG_ 615 BCS_FRWheelRotatedDirection 0;
BA_ "EventCommandSignal" SG_ 615 BCS_FRWheelRotatedDirection 0;
BA_ "GenSigSendType" SG_ 615 BCS_FRWheelSpd 1;
BA_ "GatewayedSignals" SG_ 615 BCS_FRWheelSpd 0;
BA_ "EventCommandSignal" SG_ 615 BCS_FRWheelSpd 0;
BA_ "GenSigSendType" SG_ 615 BCS_FLWheelRotatedDirection 1;
BA_ "GatewayedSignals" SG_ 615 BCS_FLWheelRotatedDirection 0;
BA_ "EventCommandSignal" SG_ 615 BCS_FLWheelRotatedDirection 0;
BA_ "GenSigSendType" SG_ 615 BCS_FLWheelSpd 1;
BA_ "GatewayedSignals" SG_ 615 BCS_FLWheelSpd 0;
BA_ "EventCommandSignal" SG_ 615 BCS_FLWheelSpd 0;
BA_ "EventCommandSignal" SG_ 615 BCS_1_Counter 0;
BA_ "GatewayedSignals" SG_ 615 BCS_1_Counter 1;
BA_ "GenSigSendType" SG_ 615 BCS_1_Counter 1;
BA_ "EventCommandSignal" SG_ 615 BCS_1_CRC 0;
BA_ "GatewayedSignals" SG_ 615 BCS_1_CRC 1;
BA_ "GenSigSendType" SG_ 615 BCS_1_CRC 1;
BA_ "EventCommandSignal" SG_ 615 BCS_FLWheelSpdEdgesSumVD 0;
BA_ "GatewayedSignals" SG_ 615 BCS_FLWheelSpdEdgesSumVD 1;
BA_ "GenSigSendType" SG_ 615 BCS_FLWheelSpdEdgesSumVD 1;
BA_ "EventCommandSignal" SG_ 615 BCS_FLWheelSpdEdgesSum 0;
BA_ "GatewayedSignals" SG_ 615 BCS_FLWheelSpdEdgesSum 1;
BA_ "GenSigSendType" SG_ 615 BCS_FLWheelSpdEdgesSum 1;
BA_ "GenSigSendType" SG_ 615 BCS_HHCErrSt 1;
BA_ "GatewayedSignals" SG_ 615 BCS_HHCErrSt 1;
BA_ "EventCommandSignal" SG_ 615 BCS_HHCErrSt 0;
BA_ "GenSigTimeoutValue" SG_ 615 BCS_HHCErrSt 1;
BA_ "GenSigSendType" SG_ 615 BCS_HDCCtrlSt 1;
BA_ "GatewayedSignals" SG_ 615 BCS_HDCCtrlSt 1;
BA_ "EventCommandSignal" SG_ 615 BCS_HDCCtrlSt 0;
BA_ "GenSigSendType" SG_ 615 BCS_HDCErrSt 1;
BA_ "GatewayedSignals" SG_ 615 BCS_HDCErrSt 1;
BA_ "EventCommandSignal" SG_ 615 BCS_HDCErrSt 0;
BA_ "GenSigTimeoutValue" SG_ 615 BCS_HDCErrSt 1;
BA_ "GenSigSendType" SG_ 615 BCS_RLWheelSpdEdgesSum 1;
BA_ "GatewayedSignals" SG_ 615 BCS_RLWheelSpdEdgesSum 1;
BA_ "EventCommandSignal" SG_ 615 BCS_RLWheelSpdEdgesSum 0;
BA_ "GenSigSendType" SG_ 615 BCS_RLWheelSpdEdgesSumVD 1;
BA_ "GatewayedSignals" SG_ 615 BCS_RLWheelSpdEdgesSumVD 1;
BA_ "EventCommandSignal" SG_ 615 BCS_RLWheelSpdEdgesSumVD 0;
BA_ "GenSigSendType" SG_ 615 BCS_VDCOff 1;
BA_ "GatewayedSignals" SG_ 615 BCS_VDCOff 1;
BA_ "EventCommandSignal" SG_ 615 BCS_VDCOff 0;
BA_ "GenSigSendType" SG_ 615 BCS_AVHSt 1;
BA_ "GatewayedSignals" SG_ 615 BCS_AVHSt 1;
BA_ "EventCommandSignal" SG_ 615 BCS_AVHSt 0;
BA_ "GenSigSendType" SG_ 615 BCS_AVHStandby 1;
BA_ "GatewayedSignals" SG_ 615 BCS_AVHStandby 1;
BA_ "EventCommandSignal" SG_ 615 BCS_AVHStandby 0;
BA_ "GenSigSendType" SG_ 615 BCS_AVHAvailable 1;
BA_ "GatewayedSignals" SG_ 615 BCS_AVHAvailable 1;
BA_ "EventCommandSignal" SG_ 615 BCS_AVHAvailable 0;
BA_ "GenSigSendType" SG_ 615 BCS_TCSOff 1;
BA_ "GatewayedSignals" SG_ 615 BCS_TCSOff 1;
BA_ "EventCommandSignal" SG_ 615 BCS_TCSOff 0;
BA_ "GenSigInvalidValue" SG_ 615 BCS_ESPFuncResp 3;
BA_ "GenSigSendType" SG_ 615 BCS_ESPFuncResp 1;
BA_ "GatewayedSignals" SG_ 615 BCS_ESPFuncResp 1;
BA_ "EventCommandSignal" SG_ 615 BCS_ESPFuncResp 0;
BA_ "GenSigTimeoutValue" SG_ 615 BCS_ESPFuncResp 3;
BA_ "GenSigInvalidValue" SG_ 615 BCS_HDCFuncResp 2;
BA_ "GenSigSendType" SG_ 615 BCS_HDCFuncResp 1;
BA_ "GatewayedSignals" SG_ 615 BCS_HDCFuncResp 1;
BA_ "EventCommandSignal" SG_ 615 BCS_HDCFuncResp 0;
BA_ "GenSigTimeoutValue" SG_ 615 BCS_HDCFuncResp 2;
BA_ "Remark" SG_ 352 IPB_BrakePedalSt "<E2E_Group1>";
BA_ "EventCommandSignal" SG_ 352 IPB_BrakePedalSt 0;
BA_ "GatewayedSignals" SG_ 352 IPB_BrakePedalSt 0;
BA_ "GenSigSendType" SG_ 352 IPB_BrakePedalSt 1;
BA_ "EventCommandSignal" SG_ 352 BCS_2_Counter 0;
BA_ "GenSigSendType" SG_ 352 BCS_2_Counter 1;
BA_ "EventCommandSignal" SG_ 352 BCS_2_CRC 0;
BA_ "GenSigSendType" SG_ 352 BCS_2_CRC 1;
BA_ "GenSigSendType" SG_ 352 BCS_VehSpd 1;
BA_ "GatewayedSignals" SG_ 352 BCS_VehSpd 1;
BA_ "EventCommandSignal" SG_ 352 BCS_VehSpd 0;
BA_ "GenSigSendType" SG_ 352 BCS_VehSpdVD 1;
BA_ "GatewayedSignals" SG_ 352 BCS_VehSpdVD 1;
BA_ "EventCommandSignal" SG_ 352 BCS_VehSpdVD 0;
BA_ "GenSigStartValue" SG_ 352 BCS_EBDFaultSt 1;
BA_ "GenSigSendType" SG_ 352 BCS_EBDFaultSt 1;
BA_ "GatewayedSignals" SG_ 352 BCS_EBDFaultSt 1;
BA_ "EventCommandSignal" SG_ 352 BCS_EBDFaultSt 0;
BA_ "GenSigTimeoutValue" SG_ 352 BCS_EBDFaultSt 1;
BA_ "GenSigStartValue" SG_ 352 BCS_ABSFaultSt 1;
BA_ "GenSigSendType" SG_ 352 BCS_ABSFaultSt 1;
BA_ "GatewayedSignals" SG_ 352 BCS_ABSFaultSt 1;
BA_ "EventCommandSignal" SG_ 352 BCS_ABSFaultSt 0;
BA_ "GenSigTimeoutValue" SG_ 352 BCS_ABSFaultSt 1;
BA_ "GenSigSendType" SG_ 352 BCS_TCSActiveSt 1;
BA_ "GatewayedSignals" SG_ 352 BCS_TCSActiveSt 1;
BA_ "EventCommandSignal" SG_ 352 BCS_TCSActiveSt 0;
BA_ "GenSigStartValue" SG_ 352 BCS_TCSFaultSt 1;
BA_ "GenSigSendType" SG_ 352 BCS_TCSFaultSt 1;
BA_ "GatewayedSignals" SG_ 352 BCS_TCSFaultSt 1;
BA_ "EventCommandSignal" SG_ 352 BCS_TCSFaultSt 0;
BA_ "GenSigTimeoutValue" SG_ 352 BCS_TCSFaultSt 1;
BA_ "GenSigSendType" SG_ 352 BCS_VDCActiveSt 1;
BA_ "GatewayedSignals" SG_ 352 BCS_VDCActiveSt 1;
BA_ "EventCommandSignal" SG_ 352 BCS_VDCActiveSt 0;
BA_ "GenSigStartValue" SG_ 352 BCS_VDCFaultSt 1;
BA_ "GenSigSendType" SG_ 352 BCS_VDCFaultSt 1;
BA_ "GatewayedSignals" SG_ 352 BCS_VDCFaultSt 1;
BA_ "EventCommandSignal" SG_ 352 BCS_VDCFaultSt 0;
BA_ "GenSigTimeoutValue" SG_ 352 BCS_VDCFaultSt 1;
BA_ "GenSigSendType" SG_ 611 IPB_BrkPedalModesetSt 1;
BA_ "GenSigInvalidValue" SG_ 611 IPB_BrkPedalModesetSt 127;
BA_ "GatewayedSignals" SG_ 611 IPB_BrkPedalModesetSt 0;
BA_ "EventCommandSignal" SG_ 611 IPB_BrkPedalModesetSt 0;
BA_ "EventCommandSignal" SG_ 611 BCS_3_CRC 0;
BA_ "GatewayedSignals" SG_ 611 BCS_3_CRC 1;
BA_ "GenSigSendType" SG_ 611 BCS_3_CRC 1;
BA_ "EventCommandSignal" SG_ 611 BCS_3_Counter 0;
BA_ "GatewayedSignals" SG_ 611 BCS_3_Counter 1;
BA_ "GenSigSendType" SG_ 611 BCS_3_Counter 1;
BA_ "GenSigSendType" SG_ 611 IPB_BrkPedalModeCfgSt 1;
BA_ "GatewayedSignals" SG_ 611 IPB_BrkPedalModeCfgSt 1;
BA_ "EventCommandSignal" SG_ 611 IPB_BrkPedalModeCfgSt 0;
BA_ "GenSigSendType" SG_ 611 IPB_InputRodStrokeSt 1;
BA_ "GatewayedSignals" SG_ 611 IPB_InputRodStrokeSt 1;
BA_ "EventCommandSignal" SG_ 611 IPB_InputRodStrokeSt 0;
BA_ "GenSigSendType" SG_ 611 IBCS_SystemSt 1;
BA_ "GatewayedSignals" SG_ 611 IBCS_SystemSt 1;
BA_ "EventCommandSignal" SG_ 611 IBCS_SystemSt 0;
BA_ "GenSigSendType" SG_ 611 IBCS_FWAWarning 1;
BA_ "GatewayedSignals" SG_ 611 IBCS_FWAWarning 1;
BA_ "EventCommandSignal" SG_ 611 IBCS_FWAWarning 0;
BA_ "GenSigSendType" SG_ 611 IBCS_BrakeFluidWarning 1;
BA_ "GatewayedSignals" SG_ 611 IBCS_BrakeFluidWarning 1;
BA_ "EventCommandSignal" SG_ 611 IBCS_BrakeFluidWarning 0;
BA_ "GenSigSendType" SG_ 611 IPB_CSTSt 1;
BA_ "GatewayedSignals" SG_ 611 IPB_CSTSt 1;
BA_ "EventCommandSignal" SG_ 611 IPB_CSTSt 0;
BA_ "GenSigSendType" SG_ 611 IBCS_TwoFoot_DriveWarning 1;
BA_ "GatewayedSignals" SG_ 611 IBCS_TwoFoot_DriveWarning 1;
BA_ "EventCommandSignal" SG_ 611 IBCS_TwoFoot_DriveWarning 0;
BA_ "GenSigSendType" SG_ 611 BCS_ESPMode 1;
BA_ "GatewayedSignals" SG_ 611 BCS_ESPMode 1;
BA_ "EventCommandSignal" SG_ 611 BCS_ESPMode 0;
BA_ "GenSigSendType" SG_ 886 BCS_TPMSResetSt 1;
BA_ "GatewayedSignals" SG_ 886 BCS_TPMSResetSt 1;
BA_ "EventCommandSignal" SG_ 886 BCS_TPMSResetSt 0;
BA_ "GenSigSendType" SG_ 886 BCS_TPMSWarningLamp 1;
BA_ "GatewayedSignals" SG_ 886 BCS_TPMSWarningLamp 1;
BA_ "EventCommandSignal" SG_ 886 BCS_TPMSWarningLamp 0;
BA_ "GenSigTimeoutValue" SG_ 886 BCS_TPMSWarningLamp 1;
BA_ "GenSigSendType" SG_ 886 BCS_TPMSSysErrorSt 1;
BA_ "GatewayedSignals" SG_ 886 BCS_TPMSSysErrorSt 1;
BA_ "EventCommandSignal" SG_ 886 BCS_TPMSSysErrorSt 0;
BA_ "GenSigTimeoutValue" SG_ 886 BCS_TPMSSysErrorSt 1;
BA_ "GenSigSendType" SG_ 886 BCS_TPMSFLTyrePreWarn 1;
BA_ "GatewayedSignals" SG_ 886 BCS_TPMSFLTyrePreWarn 1;
BA_ "EventCommandSignal" SG_ 886 BCS_TPMSFLTyrePreWarn 0;
BA_ "GenSigTimeoutValue" SG_ 886 BCS_TPMSFLTyrePreWarn 1;
BA_ "GenSigSendType" SG_ 886 BCS_TPMSFRTyrePreWarn 1;
BA_ "GatewayedSignals" SG_ 886 BCS_TPMSFRTyrePreWarn 1;
BA_ "EventCommandSignal" SG_ 886 BCS_TPMSFRTyrePreWarn 0;
BA_ "GenSigTimeoutValue" SG_ 886 BCS_TPMSFRTyrePreWarn 1;
BA_ "GenSigSendType" SG_ 886 BCS_AVHSoftSwctrlst 1;
BA_ "GatewayedSignals" SG_ 886 BCS_AVHSoftSwctrlst 1;
BA_ "EventCommandSignal" SG_ 886 BCS_AVHSoftSwctrlst 0;
BA_ "GenSigSendType" SG_ 886 BCS_TPMSRLTyrePreWarn 1;
BA_ "GatewayedSignals" SG_ 886 BCS_TPMSRLTyrePreWarn 1;
BA_ "EventCommandSignal" SG_ 886 BCS_TPMSRLTyrePreWarn 0;
BA_ "GenSigTimeoutValue" SG_ 886 BCS_TPMSRLTyrePreWarn 1;
BA_ "GenSigSendType" SG_ 886 BCS_TPMSRRTyrePreWarn 1;
BA_ "GatewayedSignals" SG_ 886 BCS_TPMSRRTyrePreWarn 1;
BA_ "EventCommandSignal" SG_ 886 BCS_TPMSRRTyrePreWarn 0;
BA_ "GenSigTimeoutValue" SG_ 886 BCS_TPMSRRTyrePreWarn 1;
BA_ "GenSigSendType" SG_ 618 EPB_DragMode 1;
BA_ "GatewayedSignals" SG_ 618 EPB_DragMode 1;
BA_ "EventCommandSignal" SG_ 618 EPB_DragMode 0;
BA_ "Remark" SG_ 618 EPB_1_CRC "<E2E_Group1>";
BA_ "EventCommandSignal" SG_ 618 EPB_1_CRC 0;
BA_ "GatewayedSignals" SG_ 618 EPB_1_CRC 1;
BA_ "GenSigSendType" SG_ 618 EPB_1_CRC 1;
BA_ "Remark" SG_ 618 EPB_1_Counter "<E2E_Group1>";
BA_ "EventCommandSignal" SG_ 618 EPB_1_Counter 0;
BA_ "GatewayedSignals" SG_ 618 EPB_1_Counter 1;
BA_ "GenSigSendType" SG_ 618 EPB_1_Counter 1;
BA_ "Remark" SG_ 618 EPB_SysSt "<E2E_Group1>";
BA_ "GenSigSendType" SG_ 618 EPB_SysSt 1;
BA_ "GatewayedSignals" SG_ 618 EPB_SysSt 1;
BA_ "EventCommandSignal" SG_ 618 EPB_SysSt 0;
BA_ "GenSigTimeoutValue" SG_ 618 EPB_SysSt 7;
BA_ "Remark" SG_ 618 EPB_SysStIndReq "<E2E_Group1>";
BA_ "GenSigSendType" SG_ 618 EPB_SysStIndReq 1;
BA_ "GatewayedSignals" SG_ 618 EPB_SysStIndReq 1;
BA_ "EventCommandSignal" SG_ 618 EPB_SysStIndReq 0;
BA_ "GenSigTimeoutValue" SG_ 618 EPB_SysStIndReq 2;
BA_ "Remark" SG_ 618 EPB_FailSt "<E2E_Group1>";
BA_ "GenSigSendType" SG_ 618 EPB_FailSt 1;
BA_ "GatewayedSignals" SG_ 618 EPB_FailSt 1;
BA_ "EventCommandSignal" SG_ 618 EPB_FailSt 0;
BA_ "GenSigTimeoutValue" SG_ 618 EPB_FailSt 1;
BA_ "Remark" SG_ 618 EPB_SysWarnIndReq "<E2E_Group1>";
BA_ "GenSigSendType" SG_ 618 EPB_SysWarnIndReq 1;
BA_ "GatewayedSignals" SG_ 618 EPB_SysWarnIndReq 1;
BA_ "EventCommandSignal" SG_ 618 EPB_SysWarnIndReq 0;
BA_ "GenSigTimeoutValue" SG_ 618 EPB_SysWarnIndReq 1;
BA_ "Remark" SG_ 618 EPB_SysAudWarnReq "<E2E_Group1>";
BA_ "GenSigSendType" SG_ 618 EPB_SysAudWarnReq 1;
BA_ "GatewayedSignals" SG_ 618 EPB_SysAudWarnReq 1;
BA_ "EventCommandSignal" SG_ 618 EPB_SysAudWarnReq 0;
BA_ "Remark" SG_ 618 EPB_SysDispMsgReq "<E2E_Group1>";
BA_ "GenSigSendType" SG_ 618 EPB_SysDispMsgReq 1;
BA_ "GatewayedSignals" SG_ 618 EPB_SysDispMsgReq 1;
BA_ "EventCommandSignal" SG_ 618 EPB_SysDispMsgReq 0;
BA_ "GenSigTimeoutValue" SG_ 618 EPB_SysDispMsgReq 3;
BA_ "Remark" SG_ 618 EPB_StpOnBrkToRelParkBrkIndOn "<E2E_Group1>";
BA_ "GenSigSendType" SG_ 618 EPB_StpOnBrkToRelParkBrkIndOn 1;
BA_ "GatewayedSignals" SG_ 618 EPB_StpOnBrkToRelParkBrkIndOn 1;
BA_ "EventCommandSignal" SG_ 618 EPB_StpOnBrkToRelParkBrkIndOn 0;
BA_ "EventCommandSignal" SG_ 939 SRS_2_CRC 0;
BA_ "GenSigSendType" SG_ 939 SRS_2_CRC 1;
BA_ "EventCommandSignal" SG_ 939 SRS_2_Counter 0;
BA_ "GenSigSendType" SG_ 939 SRS_2_Counter 1;
BA_ "GenSigInvalidValue" SG_ 939 SRS_PsngrSeatBeltSt 3;
BA_ "GenSigSendType" SG_ 939 SRS_PsngrSeatBeltSt 1;
BA_ "GatewayedSignals" SG_ 939 SRS_PsngrSeatBeltSt 1;
BA_ "EventCommandSignal" SG_ 939 SRS_PsngrSeatBeltSt 0;
BA_ "GenSigTimeoutValue" SG_ 939 SRS_PsngrSeatBeltSt 3;
BA_ "GenSigInvalidValue" SG_ 939 SRS_DriverSeatBeltSt 3;
BA_ "GenSigSendType" SG_ 939 SRS_DriverSeatBeltSt 1;
BA_ "GatewayedSignals" SG_ 939 SRS_DriverSeatBeltSt 1;
BA_ "EventCommandSignal" SG_ 939 SRS_DriverSeatBeltSt 0;
BA_ "GenSigTimeoutValue" SG_ 939 SRS_DriverSeatBeltSt 3;
BA_ "GenSigInvalidValue" SG_ 939 SRS_RearLeftSeatBeltSt 3;
BA_ "GenSigSendType" SG_ 939 SRS_RearLeftSeatBeltSt 1;
BA_ "GatewayedSignals" SG_ 939 SRS_RearLeftSeatBeltSt 1;
BA_ "EventCommandSignal" SG_ 939 SRS_RearLeftSeatBeltSt 0;
BA_ "GenSigTimeoutValue" SG_ 939 SRS_RearLeftSeatBeltSt 3;
BA_ "GenSigSendType" SG_ 939 SRS_AirbagFaultSt 1;
BA_ "GatewayedSignals" SG_ 939 SRS_AirbagFaultSt 1;
BA_ "EventCommandSignal" SG_ 939 SRS_AirbagFaultSt 0;
BA_ "GenSigTimeoutValue" SG_ 939 SRS_AirbagFaultSt 1;
BA_ "GenSigInvalidValue" SG_ 939 SRS_RearRightSeatBeltSt 3;
BA_ "GenSigSendType" SG_ 939 SRS_RearRightSeatBeltSt 1;
BA_ "GatewayedSignals" SG_ 939 SRS_RearRightSeatBeltSt 1;
BA_ "EventCommandSignal" SG_ 939 SRS_RearRightSeatBeltSt 0;
BA_ "GenSigTimeoutValue" SG_ 939 SRS_RearRightSeatBeltSt 3;
BA_ "GenSigInvalidValue" SG_ 939 SRS_RearMiddleSeatBeltSt 3;
BA_ "GenSigSendType" SG_ 939 SRS_RearMiddleSeatBeltSt 1;
BA_ "GatewayedSignals" SG_ 939 SRS_RearMiddleSeatBeltSt 1;
BA_ "EventCommandSignal" SG_ 939 SRS_RearMiddleSeatBeltSt 0;
BA_ "GenSigTimeoutValue" SG_ 939 SRS_RearMiddleSeatBeltSt 3;
BA_ "Remark" SG_ 368 DCU_TorqAct "<E2E_Group1>";
BA_ "GenSigStartValue" SG_ 368 DCU_TorqAct 4095;
BA_ "GenSigSendType" SG_ 368 DCU_TorqAct 1;
BA_ "EventCommandSignal" SG_ 368 DCU_TorqAct 0;
BA_ "GenSigSendType" SG_ 864 DCU_SysTempOvrInd 1;
BA_ "EventCommandSignal" SG_ 864 DCU_SysTempOvrInd 0;
BA_ "Remark" SG_ 864 DCU_Err2NoticeFlag "<E2E_Group1>";
BA_ "EventCommandSignal" SG_ 864 DCU_Err2NoticeFlag 0;
BA_ "GatewayedSignals" SG_ 864 DCU_Err2NoticeFlag 1;
BA_ "GenSigSendType" SG_ 864 DCU_Err2NoticeFlag 1;
BA_ "Remark" SG_ 864 DCU_ErrNotice "<E2E_Group1>";
BA_ "EventCommandSignal" SG_ 864 DCU_ErrNotice 0;
BA_ "GatewayedSignals" SG_ 864 DCU_ErrNotice 1;
BA_ "GenSigSendType" SG_ 864 DCU_ErrNotice 1;
BA_ "Remark" SG_ 864 DCU_ErrNoticeOperationFlag "<E2E_Group1>";
BA_ "EventCommandSignal" SG_ 864 DCU_ErrNoticeOperationFlag 0;
BA_ "GatewayedSignals" SG_ 864 DCU_ErrNoticeOperationFlag 1;
BA_ "GenSigSendType" SG_ 864 DCU_ErrNoticeOperationFlag 1;
BA_ "Remark" SG_ 864 DCU_2_Counter "<E2E_Group1>";
BA_ "EventCommandSignal" SG_ 864 DCU_2_Counter 0;
BA_ "GatewayedSignals" SG_ 864 DCU_2_Counter 1;
BA_ "GenSigSendType" SG_ 864 DCU_2_Counter 1;
BA_ "Remark" SG_ 864 DCU_2_CRC "<E2E_Group1>";
BA_ "EventCommandSignal" SG_ 864 DCU_2_CRC 0;
BA_ "GatewayedSignals" SG_ 864 DCU_2_CRC 1;
BA_ "GenSigSendType" SG_ 864 DCU_2_CRC 1;
BA_ "GenSigSendType" SG_ 864 DCU_FaultLampInd 1;
BA_ "GatewayedSignals" SG_ 864 DCU_FaultLampInd 1;
BA_ "EventCommandSignal" SG_ 864 DCU_FaultLampInd 0;
BA_ "Remark" SG_ 872 IPS_OBCFaultLampIndOperationFlag "<E2E_Group1>";
BA_ "EventCommandSignal" SG_ 872 IPS_OBCFaultLampIndOperationFlag 0;
BA_ "GenSigSendType" SG_ 872 IPS_OBCFaultLampIndOperationFlag 1;
BA_ "Remark" SG_ 872 IPS_DCDCFaultLampIndFlag "<E2E_Group1>";
BA_ "EventCommandSignal" SG_ 872 IPS_DCDCFaultLampIndFlag 0;
BA_ "GenSigSendType" SG_ 872 IPS_DCDCFaultLampIndFlag 1;
BA_ "Remark" SG_ 872 IPS_DCDCFaultLampIndOperationFla "<E2E_Group1>";
BA_ "EventCommandSignal" SG_ 872 IPS_DCDCFaultLampIndOperationFla 0;
BA_ "GenSigSendType" SG_ 872 IPS_DCDCFaultLampIndOperationFla 1;
BA_ "Remark" SG_ 872 IPS_2_CRC "<E2E_Group1>";
BA_ "EventCommandSignal" SG_ 872 IPS_2_CRC 0;
BA_ "GenSigSendType" SG_ 872 IPS_2_CRC 1;
BA_ "Remark" SG_ 872 IPS_2_Counter "<E2E_Group1>";
BA_ "EventCommandSignal" SG_ 872 IPS_2_Counter 0;
BA_ "GenSigSendType" SG_ 872 IPS_2_Counter 1;
BA_ "GenSigSendType" SG_ 872 IPS_DCDCFaultLampInd 1;
BA_ "EventCommandSignal" SG_ 872 IPS_DCDCFaultLampInd 0;
BA_ "GenSigSendType" SG_ 872 IPS_OBCFaultLampInd 1;
BA_ "EventCommandSignal" SG_ 872 IPS_OBCFaultLampInd 0;
BA_ "GenSigSendType" SG_ 880 ITS_MotorPumpSt 1;
BA_ "GatewayedSignals" SG_ 880 ITS_MotorPumpSt 1;
BA_ "EventCommandSignal" SG_ 880 ITS_MotorPumpSt 0;
BA_ "GenSigSendType" SG_ 880 ITS_FanStpSpdErr 1;
BA_ "GatewayedSignals" SG_ 880 ITS_FanStpSpdErr 1;
BA_ "EventCommandSignal" SG_ 880 ITS_FanStpSpdErr 0;
BA_ "GenSigSendType" SG_ 880 ITS_HeaterPumpSt 1;
BA_ "GatewayedSignals" SG_ 880 ITS_HeaterPumpSt 1;
BA_ "EventCommandSignal" SG_ 880 ITS_HeaterPumpSt 0;
BA_ "GenSigSendType" SG_ 880 ITS_EcvSt 1;
BA_ "GatewayedSignals" SG_ 880 ITS_EcvSt 1;
BA_ "EventCommandSignal" SG_ 880 ITS_EcvSt 0;
BA_ "GenSigSendType" SG_ 880 ITS_BatteryPumpSt 1;
BA_ "GatewayedSignals" SG_ 880 ITS_BatteryPumpSt 1;
BA_ "EventCommandSignal" SG_ 880 ITS_BatteryPumpSt 0;
BA_ "GenSigSendType" SG_ 880 ITS_MotorInletTempErr 1;
BA_ "GatewayedSignals" SG_ 880 ITS_MotorInletTempErr 1;
BA_ "EventCommandSignal" SG_ 880 ITS_MotorInletTempErr 0;
BA_ "GenSigSendType" SG_ 880 ITS_BatteryInletTempErr 1;
BA_ "GatewayedSignals" SG_ 880 ITS_BatteryInletTempErr 1;
BA_ "EventCommandSignal" SG_ 880 ITS_BatteryInletTempErr 0;
BA_ "GenSigSendType" SG_ 880 ITS_ChillerInletTempErr 1;
BA_ "GatewayedSignals" SG_ 880 ITS_ChillerInletTempErr 1;
BA_ "EventCommandSignal" SG_ 880 ITS_ChillerInletTempErr 0;
BA_ "GenSigSendType" SG_ 880 ITS_SolenoidErr 1;
BA_ "GatewayedSignals" SG_ 880 ITS_SolenoidErr 1;
BA_ "EventCommandSignal" SG_ 880 ITS_SolenoidErr 0;
BA_ "GenSigSendType" SG_ 824 VCU_HVAC_PTCdelayEn 1;
BA_ "EventCommandSignal" SG_ 824 VCU_HVAC_PTCdelayEn 0;
BA_ "GenSigSendType" SG_ 824 VCU_2_CRC 1;
BA_ "EventCommandSignal" SG_ 824 VCU_2_CRC 0;
BA_ "Remark" SG_ 824 VCU_2_CRC "<E2E_Group1>

[E2E_Trigger]";
BA_ "GenSigSendType" SG_ 824 VCU_2_Counter 1;
BA_ "EventCommandSignal" SG_ 824 VCU_2_Counter 0;
BA_ "Remark" SG_ 824 VCU_2_Counter "<E2E_Group1>

[E2E_Trigger]";
BA_ "Remark" SG_ 824 VCU_LongDistResp "<E2E_Group1>

[E2E_Trigger]";
BA_ "EventCommandSignal" SG_ 824 VCU_LongDistResp 0;
BA_ "GenSigSendType" SG_ 824 VCU_LongDistResp 1;
BA_ "Remark" SG_ 824 VCU_SwapHvBattModeStVD "<E2E_Group1>

[E2E_Trigger]";
BA_ "EventCommandSignal" SG_ 824 VCU_SwapHvBattModeStVD 0;
BA_ "GenSigSendType" SG_ 824 VCU_SwapHvBattModeStVD 1;
BA_ "Remark" SG_ 824 VCU_SwapHvBattModeSt "<E2E_Group1>

[E2E_Trigger]";
BA_ "EventCommandSignal" SG_ 824 VCU_SwapHvBattModeSt 0;
BA_ "GenSigSendType" SG_ 824 VCU_SwapHvBattModeSt 1;
BA_ "Remark" SG_ 824 VCU_WarmTimeNotice "<E2E_Group1>

[E2E_Trigger]";
BA_ "EventCommandSignal" SG_ 824 VCU_WarmTimeNotice 0;
BA_ "GenSigSendType" SG_ 824 VCU_WarmTimeNotice 1;
BA_ "Remark" SG_ 824 VCU_VehElcConspInst "<E2E_Group1>

[E2E_Trigger]";
BA_ "GenSigSendType" SG_ 824 VCU_VehElcConspInst 1;
BA_ "EventCommandSignal" SG_ 824 VCU_VehElcConspInst 0;
BA_ "Remark" SG_ 824 VCU_DischgSt "<E2E_Group1>

[E2E_Trigger]";
BA_ "GenSigSendType" SG_ 824 VCU_DischgSt 1;
BA_ "EventCommandSignal" SG_ 824 VCU_DischgSt 0;
BA_ "Remark" SG_ 824 VCU_DischgAvai "<E2E_Group1>

[E2E_Trigger]";
BA_ "GenSigSendType" SG_ 824 VCU_DischgAvai 1;
BA_ "EventCommandSignal" SG_ 824 VCU_DischgAvai 0;
BA_ "Remark" SG_ 824 VCU_WarmTimeCfgResp "<E2E_Group1>

[E2E_Trigger]";
BA_ "GenSigSendType" SG_ 824 VCU_WarmTimeCfgResp 1;
BA_ "EventCommandSignal" SG_ 824 VCU_WarmTimeCfgResp 0;
BA_ "Remark" SG_ 824 VCU_WarmSt "<E2E_Group1>

[E2E_Trigger]";
BA_ "GenSigSendType" SG_ 824 VCU_WarmSt 1;
BA_ "EventCommandSignal" SG_ 824 VCU_WarmSt 0;
BA_ "Remark" SG_ 824 VCU_CreepAvail "<E2E_Group1>

[E2E_Trigger]";
BA_ "GenSigSendType" SG_ 824 VCU_CreepAvail 1;
BA_ "EventCommandSignal" SG_ 824 VCU_CreepAvail 0;
BA_ "Remark" SG_ 824 VCU_GearLvlDisp "<E2E_Group1>

[E2E_Trigger]";
BA_ "GenSigSendType" SG_ 824 VCU_GearLvlDisp 1;
BA_ "EventCommandSignal" SG_ 824 VCU_GearLvlDisp 0;
BA_ "Remark" SG_ 824 VCU_RecpLevelAvail "<E2E_Group1>

[E2E_Trigger]";
BA_ "GenSigSendType" SG_ 824 VCU_RecpLevelAvail 1;
BA_ "EventCommandSignal" SG_ 824 VCU_RecpLevelAvail 0;
BA_ "Remark" SG_ 824 VCU_IpedalModeAvail "<E2E_Group1>

[E2E_Trigger]";
BA_ "GenSigSendType" SG_ 824 VCU_IpedalModeAvail 1;
BA_ "EventCommandSignal" SG_ 824 VCU_IpedalModeAvail 0;
BA_ "Remark" SG_ 824 VCU_ElcSysFault "<E2E_Group1>

[E2E_Trigger]";
BA_ "GenSigSendType" SG_ 824 VCU_ElcSysFault 1;
BA_ "EventCommandSignal" SG_ 824 VCU_ElcSysFault 0;
BA_ "Remark" SG_ 824 VCU_DspChgSt "<E2E_Group1>

[E2E_Trigger]";
BA_ "GenSigSendType" SG_ 824 VCU_DspChgSt 1;
BA_ "EventCommandSignal" SG_ 824 VCU_DspChgSt 0;
BA_ "Remark" SG_ 824 VCU_DspDischgSt "<E2E_Group1>

[E2E_Trigger]";
BA_ "GenSigSendType" SG_ 824 VCU_DspDischgSt 1;
BA_ "EventCommandSignal" SG_ 824 VCU_DspDischgSt 0;
BA_ "Remark" SG_ 824 VCU_SOCDynamicDspSt "<E2E_Group1>

[E2E_Trigger]";
BA_ "GenSigSendType" SG_ 824 VCU_SOCDynamicDspSt 1;
BA_ "EventCommandSignal" SG_ 824 VCU_SOCDynamicDspSt 0;
BA_ "Remark" SG_ 824 VCU_DspChgVolt "<E2E_Group1>

[E2E_Trigger]";
BA_ "GenSigSendType" SG_ 824 VCU_DspChgVolt 1;
BA_ "EventCommandSignal" SG_ 824 VCU_DspChgVolt 0;
BA_ "Remark" SG_ 824 VCU_BookChgLampInd "<E2E_Group1>

[E2E_Trigger]";
BA_ "GenSigSendType" SG_ 824 VCU_BookChgLampInd 1;
BA_ "EventCommandSignal" SG_ 824 VCU_BookChgLampInd 0;
BA_ "Remark" SG_ 824 VCU_DspChgCurr "<E2E_Group1>

[E2E_Trigger]";
BA_ "GenSigSendType" SG_ 824 VCU_DspChgCurr 1;
BA_ "EventCommandSignal" SG_ 824 VCU_DspChgCurr 0;
BA_ "Remark" SG_ 824 VCU_DspDischgVolt "<E2E_Group1>

[E2E_Trigger]";
BA_ "GenSigSendType" SG_ 824 VCU_DspDischgVolt 1;
BA_ "EventCommandSignal" SG_ 824 VCU_DspDischgVolt 0;
BA_ "Remark" SG_ 824 VCU_EcoPlusModeAvail "<E2E_Group1>

[E2E_Trigger]";
BA_ "GenSigSendType" SG_ 824 VCU_EcoPlusModeAvail 1;
BA_ "EventCommandSignal" SG_ 824 VCU_EcoPlusModeAvail 0;
BA_ "Remark" SG_ 824 VCU_DspDischgCurr "<E2E_Group1>

[E2E_Trigger]";
BA_ "GenSigSendType" SG_ 824 VCU_DspDischgCurr 1;
BA_ "EventCommandSignal" SG_ 824 VCU_DspDischgCurr 0;
BA_ "Remark" SG_ 824 VCU_DriverNoticeDisp "<E2E_Group1>

[E2E_Trigger]";
BA_ "GenSigSendType" SG_ 824 VCU_DriverNoticeDisp 1;
BA_ "EventCommandSignal" SG_ 824 VCU_DriverNoticeDisp 0;
BA_ "Remark" SG_ 824 VCU_DrvChgDchgDsp "<E2E_Group1>

[E2E_Trigger]";
BA_ "GenSigSendType" SG_ 824 VCU_DrvChgDchgDsp 1;
BA_ "EventCommandSignal" SG_ 824 VCU_DrvChgDchgDsp 0;
BA_ "Remark" SG_ 824 VCU_CruExitNotice "<E2E_Group1>

[E2E_Trigger]";
BA_ "GenSigSendType" SG_ 824 VCU_CruExitNotice 1;
BA_ "EventCommandSignal" SG_ 824 VCU_CruExitNotice 0;
BA_ "Remark" SG_ 824 VCU_DischgEndVehRng "<E2E_Group1>

[E2E_Trigger]";
BA_ "GenSigStartValue" SG_ 824 VCU_DischgEndVehRng 999;
BA_ "GenSigSendType" SG_ 824 VCU_DischgEndVehRng 1;
BA_ "EventCommandSignal" SG_ 824 VCU_DischgEndVehRng 0;
BA_ "Remark" SG_ 824 VCU_DischgSocResp "<E2E_Group1>

[E2E_Trigger]";
BA_ "GenSigStartValue" SG_ 824 VCU_DischgSocResp 20;
BA_ "GenSigSendType" SG_ 824 VCU_DischgSocResp 1;
BA_ "EventCommandSignal" SG_ 824 VCU_DischgSocResp 0;
BA_ "Remark" SG_ 824 VCU_VehElcConspAvg "<E2E_Group1>

[E2E_Trigger]";
BA_ "GenSigSendType" SG_ 824 VCU_VehElcConspAvg 1;
BA_ "EventCommandSignal" SG_ 824 VCU_VehElcConspAvg 0;
BA_ "Remark" SG_ 824 VCU_VehElcConspAccumAvg "<E2E_Group1>

[E2E_Trigger]";
BA_ "GenSigSendType" SG_ 824 VCU_VehElcConspAccumAvg 1;
BA_ "EventCommandSignal" SG_ 824 VCU_VehElcConspAccumAvg 0;
BA_ "Remark" SG_ 824 VCU_GearLvlBlink "<E2E_Group1>

[E2E_Trigger]";
BA_ "GenSigSendType" SG_ 824 VCU_GearLvlBlink 1;
BA_ "EventCommandSignal" SG_ 824 VCU_GearLvlBlink 0;
BA_ "Remark" SG_ 824 VCU_EcoModeAvail "<E2E_Group1>

[E2E_Trigger]";
BA_ "GenSigSendType" SG_ 824 VCU_EcoModeAvail 1;
BA_ "EventCommandSignal" SG_ 824 VCU_EcoModeAvail 0;
BA_ "Remark" SG_ 824 VCU_PGearErrNotice "<E2E_Group1>

[E2E_Trigger]";
BA_ "GenSigSendType" SG_ 824 VCU_PGearErrNotice 1;
BA_ "EventCommandSignal" SG_ 824 VCU_PGearErrNotice 0;
BA_ "Remark" SG_ 824 VCU_VehCrusSt "<E2E_Group1>

[E2E_Trigger]";
BA_ "GenSigSendType" SG_ 824 VCU_VehCrusSt 1;
BA_ "EventCommandSignal" SG_ 824 VCU_VehCrusSt 0;
BA_ "Remark" SG_ 824 VCU_PwrFlowMode "<E2E_Group1>

[E2E_Trigger]";
BA_ "GenSigSendType" SG_ 824 VCU_PwrFlowMode 1;
BA_ "EventCommandSignal" SG_ 824 VCU_PwrFlowMode 0;
BA_ "Remark" SG_ 824 VCU_FaultLampInd "<E2E_Group1>

[E2E_Trigger]";
BA_ "GenSigSendType" SG_ 824 VCU_FaultLampInd 1;
BA_ "EventCommandSignal" SG_ 824 VCU_FaultLampInd 0;
BA_ "Remark" SG_ 824 VCU_VehDrvMod "<E2E_Group1>

[E2E_Trigger]";
BA_ "GenSigSendType" SG_ 824 VCU_VehDrvMod 1;
BA_ "EventCommandSignal" SG_ 824 VCU_VehDrvMod 0;
BA_ "Remark" SG_ 824 VCU_ARBWarnNotice "<E2E_Group1>

[E2E_Trigger]";
BA_ "GenSigSendType" SG_ 824 VCU_ARBWarnNotice 1;
BA_ "EventCommandSignal" SG_ 824 VCU_ARBWarnNotice 0;
BA_ "Remark" SG_ 824 VCU_BuzReq "<E2E_Group1>

[E2E_Trigger]";
BA_ "GenSigSendType" SG_ 824 VCU_BuzReq 1;
BA_ "EventCommandSignal" SG_ 824 VCU_BuzReq 0;
BA_ "Remark" SG_ 824 VCU_VehRdySt "<E2E_Group1>

[E2E_Trigger]";
BA_ "GenSigSendType" SG_ 824 VCU_VehRdySt 1;
BA_ "EventCommandSignal" SG_ 824 VCU_VehRdySt 0;
BA_ "Remark" SG_ 824 VCU_ICMSpdLimitNotice "<E2E_Group1>

[E2E_Trigger]";
BA_ "GenSigSendType" SG_ 824 VCU_ICMSpdLimitNotice 1;
BA_ "EventCommandSignal" SG_ 824 VCU_ICMSpdLimitNotice 0;
BA_ "Remark" SG_ 824 VCU_VehCrusTgtSpd "<E2E_Group1>

[E2E_Trigger]";
BA_ "GenSigSendType" SG_ 824 VCU_VehCrusTgtSpd 1;
BA_ "EventCommandSignal" SG_ 824 VCU_VehCrusTgtSpd 0;
BA_ "Remark" SG_ 824 VCU_PrecResHotMsg "<E2E_Group1>

[E2E_Trigger]";
BA_ "GenSigSendType" SG_ 824 VCU_PrecResHotMsg 1;
BA_ "EventCommandSignal" SG_ 824 VCU_PrecResHotMsg 0;
BA_ "Remark" SG_ 824 VCU_VehChgDischgSt "<E2E_Group1>

[E2E_Trigger]";
BA_ "GenSigSendType" SG_ 824 VCU_VehChgDischgSt 1;
BA_ "EventCommandSignal" SG_ 824 VCU_VehChgDischgSt 0;
BA_ "Remark" SG_ 824 VCU_ChgTimeDspType "<E2E_Group1>

[E2E_Trigger]";
BA_ "GenSigSendType" SG_ 824 VCU_ChgTimeDspType 1;
BA_ "EventCommandSignal" SG_ 824 VCU_ChgTimeDspType 0;
BA_ "Remark" SG_ 824 VCU_ThermalMsgWarn "<E2E_Group1>

[E2E_Trigger]";
BA_ "GenSigSendType" SG_ 824 VCU_ThermalMsgWarn 1;
BA_ "EventCommandSignal" SG_ 824 VCU_ThermalMsgWarn 0;
BA_ "Remark" SG_ 824 VCU_VehAvailDriveStMsgWarn "<E2E_Group1>

[E2E_Trigger]";
BA_ "GenSigSendType" SG_ 824 VCU_VehAvailDriveStMsgWarn 1;
BA_ "EventCommandSignal" SG_ 824 VCU_VehAvailDriveStMsgWarn 0;
BA_ "Remark" SG_ 824 VCU_DerateLampSt "<E2E_Group1>

[E2E_Trigger]";
BA_ "GenSigSendType" SG_ 824 VCU_DerateLampSt 1;
BA_ "EventCommandSignal" SG_ 824 VCU_DerateLampSt 0;
BA_ "Remark" SG_ 824 VCU_PlgConnSt "<E2E_Group1>

[E2E_Trigger]";
BA_ "GenSigSendType" SG_ 824 VCU_PlgConnSt 1;
BA_ "EventCommandSignal" SG_ 824 VCU_PlgConnSt 0;
BA_ "Remark" SG_ 824 VCU_VehPwrDisp "<E2E_Group1>

[E2E_Trigger]";
BA_ "GenSigSendType" SG_ 824 VCU_VehPwrDisp 1;
BA_ "EventCommandSignal" SG_ 824 VCU_VehPwrDisp 0;
BA_ "Remark" SG_ 824 VCU_DischgSetInfo "<E2E_Group1>

[E2E_Trigger]";
BA_ "GenSigSendType" SG_ 824 VCU_DischgSetInfo 1;
BA_ "EventCommandSignal" SG_ 824 VCU_DischgSetInfo 0;
BA_ "Remark" SG_ 824 VCU_ChgPlugRelSt "<E2E_Group1>

[E2E_Trigger]";
BA_ "GenSigSendType" SG_ 824 VCU_ChgPlugRelSt 1;
BA_ "EventCommandSignal" SG_ 824 VCU_ChgPlugRelSt 0;
BA_ "Remark" SG_ 824 VCU_IDC_VehSwapModIntf "<E2E_Group1>

[E2E_Trigger]";
BA_ "GenSigSendType" SG_ 824 VCU_IDC_VehSwapModIntf 1;
BA_ "EventCommandSignal" SG_ 824 VCU_IDC_VehSwapModIntf 0;
BA_ "Remark" SG_ 824 VCU_IDC_VehSwapModReq "<E2E_Group1>

[E2E_Trigger]";
BA_ "GenSigSendType" SG_ 824 VCU_IDC_VehSwapModReq 1;
BA_ "EventCommandSignal" SG_ 824 VCU_IDC_VehSwapModReq 0;
BA_ "Remark" SG_ 824 VCU_IDC_VehSwapModResp "<E2E_Group1>

[E2E_Trigger]";
BA_ "GenSigSendType" SG_ 824 VCU_IDC_VehSwapModResp 1;
BA_ "EventCommandSignal" SG_ 824 VCU_IDC_VehSwapModResp 0;
BA_ "Remark" SG_ 824 VCU_IDC_VehSwapModAvai "<E2E_Group1>

[E2E_Trigger]";
BA_ "GenSigSendType" SG_ 824 VCU_IDC_VehSwapModAvai 1;
BA_ "EventCommandSignal" SG_ 824 VCU_IDC_VehSwapModAvai 0;
BA_ "Remark" SG_ 824 VCU_RecpLevelstResp "<E2E_Group1>

[E2E_Trigger]";
BA_ "GenSigSendType" SG_ 824 VCU_RecpLevelstResp 1;
BA_ "EventCommandSignal" SG_ 824 VCU_RecpLevelstResp 0;
BA_ "Remark" SG_ 824 VCU_VehRngUndrWarn "<E2E_Group1>

[E2E_Trigger]";
BA_ "GenSigSendType" SG_ 824 VCU_VehRngUndrWarn 1;
BA_ "EventCommandSignal" SG_ 824 VCU_VehRngUndrWarn 0;
BA_ "Remark" SG_ 824 VCU_VehRng "<E2E_Group1>

[E2E_Trigger]";
BA_ "GenSigStartValue" SG_ 824 VCU_VehRng 999;
BA_ "GenSigSendType" SG_ 824 VCU_VehRng 1;
BA_ "EventCommandSignal" SG_ 824 VCU_VehRng 0;
BA_ "Remark" SG_ 824 VCU_IpedalCreepCfgResp "<E2E_Group1>

[E2E_Trigger]";
BA_ "GenSigSendType" SG_ 824 VCU_IpedalCreepCfgResp 1;
BA_ "EventCommandSignal" SG_ 824 VCU_IpedalCreepCfgResp 0;
BA_ "Remark" SG_ 824 VCU_BattSocUndrWarn "<E2E_Group1>

[E2E_Trigger]";
BA_ "GenSigSendType" SG_ 824 VCU_BattSocUndrWarn 1;
BA_ "EventCommandSignal" SG_ 824 VCU_BattSocUndrWarn 0;
BA_ "Remark" SG_ 824 VCU_VehPwr "<E2E_Group1>

[E2E_Trigger]";
BA_ "GenSigStartValue" SG_ 824 VCU_VehPwr 160;
BA_ "GenSigSendType" SG_ 824 VCU_VehPwr 1;
BA_ "EventCommandSignal" SG_ 824 VCU_VehPwr 0;
BA_ "GenSigSendType" SG_ 952 VCU_AccurRngConspAccumAvg 1;
BA_ "GatewayedSignals" SG_ 952 VCU_AccurRngConspAccumAvg 0;
BA_ "EventCommandSignal" SG_ 952 VCU_AccurRngConspAccumAvg 0;
BA_ "Remark" SG_ 952 VCU_AccurRngConspAccumAvg "<E2E_Group1>

[E2E_Trigger]";
BA_ "GenSigSendType" SG_ 952 VCU_AccurHMIModeCmd 1;
BA_ "GatewayedSignals" SG_ 952 VCU_AccurHMIModeCmd 0;
BA_ "EventCommandSignal" SG_ 952 VCU_AccurHMIModeCmd 0;
BA_ "Remark" SG_ 952 VCU_AccurHMIModeCmd "<E2E_Group1>

[E2E_Trigger]";
BA_ "GenSigSendType" SG_ 952 VCU_AccurRngAvail 1;
BA_ "GatewayedSignals" SG_ 952 VCU_AccurRngAvail 0;
BA_ "EventCommandSignal" SG_ 952 VCU_AccurRngAvail 0;
BA_ "Remark" SG_ 952 VCU_AccurRngAvail "<E2E_Group1>

[E2E_Trigger]";
BA_ "GenSigSendType" SG_ 952 VCU_EcoPlusMod 1;
BA_ "GatewayedSignals" SG_ 952 VCU_EcoPlusMod 0;
BA_ "EventCommandSignal" SG_ 952 VCU_EcoPlusMod 0;
BA_ "Remark" SG_ 952 VCU_EcoPlusMod "<E2E_Group1>

[E2E_Trigger]";
BA_ "Remark" SG_ 952 VCU_ChgButtonStDsp "<E2E_Group1>

[E2E_Trigger]";
BA_ "EventCommandSignal" SG_ 952 VCU_ChgButtonStDsp 0;
BA_ "GatewayedSignals" SG_ 952 VCU_ChgButtonStDsp 0;
BA_ "GenSigSendType" SG_ 952 VCU_ChgButtonStDsp 1;
BA_ "GenSigSendType" SG_ 952 VCU_RecpLevelstRespL 1;
BA_ "EventCommandSignal" SG_ 952 VCU_RecpLevelstRespL 0;
BA_ "Remark" SG_ 952 VCU_DspChgCurrKA "<E2E_Group1>

[E2E_Trigger]";
BA_ "EventCommandSignal" SG_ 952 VCU_DspChgCurrKA 0;
BA_ "GenSigSendType" SG_ 952 VCU_DspChgCurrKA 1;
BA_ "Remark" SG_ 952 VCU_AccPdlLvlResp "<E2E_Group1>

[E2E_Trigger]";
BA_ "EventCommandSignal" SG_ 952 VCU_AccPdlLvlResp 0;
BA_ "GenSigSendType" SG_ 952 VCU_AccPdlLvlResp 1;
BA_ "Remark" SG_ 952 VCU_Err2NoticeFlag "<E2E_Group1>

[E2E_Trigger]";
BA_ "EventCommandSignal" SG_ 952 VCU_Err2NoticeFlag 0;
BA_ "GenSigSendType" SG_ 952 VCU_Err2NoticeFlag 1;
BA_ "Remark" SG_ 952 VCU_ErrNoticeOperationFlag "<E2E_Group1>

[E2E_Trigger]";
BA_ "EventCommandSignal" SG_ 952 VCU_ErrNoticeOperationFlag 0;
BA_ "GenSigSendType" SG_ 952 VCU_ErrNoticeOperationFlag 1;
BA_ "Remark" SG_ 952 VCU_ErrNotice "<E2E_Group1>

[E2E_Trigger]";
BA_ "EventCommandSignal" SG_ 952 VCU_ErrNotice 0;
BA_ "GenSigSendType" SG_ 952 VCU_ErrNotice 1;
BA_ "Remark" SG_ 952 VCU_ThermalMsgWarnOperationFlag "<E2E_Group1>

[E2E_Trigger]";
BA_ "EventCommandSignal" SG_ 952 VCU_ThermalMsgWarnOperationFlag 0;
BA_ "GenSigSendType" SG_ 952 VCU_ThermalMsgWarnOperationFlag 1;
BA_ "Remark" SG_ 952 VCU_HVAPUTotalPwrAct "<E2E_Group1>

[E2E_Trigger]";
BA_ "EventCommandSignal" SG_ 952 VCU_HVAPUTotalPwrAct 0;
BA_ "GenSigStartValue" SG_ 952 VCU_HVAPUTotalPwrAct 32766;
BA_ "GenSigSendType" SG_ 952 VCU_HVAPUTotalPwrAct 1;
BA_ "Remark" SG_ 952 VCU_3_CRC "<E2E_Group1>

[E2E_Trigger]";
BA_ "EventCommandSignal" SG_ 952 VCU_3_CRC 0;
BA_ "GenSigSendType" SG_ 952 VCU_3_CRC 1;
BA_ "Remark" SG_ 952 VCU_3_Counter "<E2E_Group1>

[E2E_Trigger]";
BA_ "EventCommandSignal" SG_ 952 VCU_3_Counter 0;
BA_ "GenSigSendType" SG_ 952 VCU_3_Counter 1;
BA_ "Remark" SG_ 952 VCU_BattCapColorEff "<E2E_Group1>

[E2E_Trigger]";
BA_ "GenSigSendType" SG_ 952 VCU_BattCapColorEff 1;
BA_ "EventCommandSignal" SG_ 952 VCU_BattCapColorEff 0;
BA_ "Remark" SG_ 952 VCU_EMS_AccPedalActPst_Disp "<E2E_Group1>

[E2E_Trigger]";
BA_ "GenSigSendType" SG_ 952 VCU_EMS_AccPedalActPst_Disp 1;
BA_ "EventCommandSignal" SG_ 952 VCU_EMS_AccPedalActPst_Disp 0;
BA_ "Remark" SG_ 812 BMS_Err2NoticeFlag "<E2E_Group1>";
BA_ "EventCommandSignal" SG_ 812 BMS_Err2NoticeFlag 0;
BA_ "GatewayedSignals" SG_ 812 BMS_Err2NoticeFlag 0;
BA_ "GenSigSendType" SG_ 812 BMS_Err2NoticeFlag 1;
BA_ "Remark" SG_ 812 BMS_ErrNoticeOperationFlag "<E2E_Group1>";
BA_ "EventCommandSignal" SG_ 812 BMS_ErrNoticeOperationFlag 0;
BA_ "GatewayedSignals" SG_ 812 BMS_ErrNoticeOperationFlag 0;
BA_ "GenSigSendType" SG_ 812 BMS_ErrNoticeOperationFlag 1;
BA_ "Remark" SG_ 812 BMS_ErrNotice "<E2E_Group1>";
BA_ "EventCommandSignal" SG_ 812 BMS_ErrNotice 0;
BA_ "GatewayedSignals" SG_ 812 BMS_ErrNotice 0;
BA_ "GenSigSendType" SG_ 812 BMS_ErrNotice 1;
BA_ "Remark" SG_ 812 BMS_BattSocDisp "<E2E_Group1>

[E2E_Trigger]";
BA_ "GenSigSendType" SG_ 812 BMS_BattSocDisp 1;
BA_ "EventCommandSignal" SG_ 812 BMS_BattSocDisp 0;
BA_ "Remark" SG_ 812 BMS_FaultLampInd "<E2E_Group1>

[E2E_Trigger]";
BA_ "GenSigSendType" SG_ 812 BMS_FaultLampInd 1;
BA_ "EventCommandSignal" SG_ 812 BMS_FaultLampInd 0;
BA_ "Remark" SG_ 812 BMS_ChgSOCRespAvail "<E2E_Group1>

[E2E_Trigger]";
BA_ "GenSigSendType" SG_ 812 BMS_ChgSOCRespAvail 1;
BA_ "EventCommandSignal" SG_ 812 BMS_ChgSOCRespAvail 0;
BA_ "Remark" SG_ 812 BMS_ChgSOCResp "<E2E_Group1>

[E2E_Trigger]";
BA_ "GenSigSendType" SG_ 812 BMS_ChgSOCResp 1;
BA_ "EventCommandSignal" SG_ 812 BMS_ChgSOCResp 0;
BA_ "Remark" SG_ 812 BMS_ChgComplRemHour "<E2E_Group1>

[E2E_Trigger]";
BA_ "GenSigSendType" SG_ 812 BMS_ChgComplRemHour 1;
BA_ "EventCommandSignal" SG_ 812 BMS_ChgComplRemHour 0;
BA_ "Remark" SG_ 812 BMS_ChgComplRemMinute "<E2E_Group1>

[E2E_Trigger]";
BA_ "GenSigSendType" SG_ 812 BMS_ChgComplRemMinute 1;
BA_ "EventCommandSignal" SG_ 812 BMS_ChgComplRemMinute 0;
BA_ "Remark" SG_ 812 BMS_ChgmodeSt "<E2E_Group1>

[E2E_Trigger]";
BA_ "GenSigSendType" SG_ 812 BMS_ChgmodeSt 1;
BA_ "EventCommandSignal" SG_ 812 BMS_ChgmodeSt 0;
BA_ "Remark" SG_ 812 BMS_ChgmodeAvail "<E2E_Group1>

[E2E_Trigger]";
BA_ "GenSigSendType" SG_ 812 BMS_ChgmodeAvail 1;
BA_ "EventCommandSignal" SG_ 812 BMS_ChgmodeAvail 0;
BA_ "EventCommandSignal" SG_ 408 BMC_HVBattSt 0;
BA_ "GatewayedSignals" SG_ 408 BMC_HVBattSt 0;
BA_ "GenSigSendType" SG_ 408 BMC_HVBattSt 1;
BA_ "GenSigStartValue" SG_ 408 BMC_BattCurr 10000;
BA_ "GenSigSendType" SG_ 408 BMC_BattCurr 1;
BA_ "GatewayedSignals" SG_ 408 BMC_BattCurr 1;
BA_ "EventCommandSignal" SG_ 408 BMC_BattCurr 0;
BA_ "GenSigSendType" SG_ 408 BMC_BattVolt 1;
BA_ "GatewayedSignals" SG_ 408 BMC_BattVolt 1;
BA_ "EventCommandSignal" SG_ 408 BMC_BattVolt 0;
BA_ "GenSigSendType" SG_ 408 BMC_ThermalRunawayErr 1;
BA_ "GatewayedSignals" SG_ 408 BMC_ThermalRunawayErr 1;
BA_ "EventCommandSignal" SG_ 408 BMC_ThermalRunawayErr 0;
BA_ "GenSigSendType" SG_ 408 BMC_LvPwrSysMsgWarn 1;
BA_ "GatewayedSignals" SG_ 408 BMC_LvPwrSysMsgWarn 1;
BA_ "EventCommandSignal" SG_ 408 BMC_LvPwrSysMsgWarn 0;
BA_ "EventCommandSignal" SG_ 888 BMC_HVBattElec 0;
BA_ "GatewayedSignals" SG_ 888 BMC_HVBattElec 1;
BA_ "GenSigSendType" SG_ 888 BMC_HVBattElec 1;
BA_ "EventCommandSignal" SG_ 888 BMC_BattSoe 0;
BA_ "GatewayedSignals" SG_ 888 BMC_BattSoe 1;
BA_ "GenSigSendType" SG_ 888 BMC_BattSoe 1;
BA_ "GenSigSendType" SG_ 888 BMC_HealCheckNotice 1;
BA_ "GatewayedSignals" SG_ 888 BMC_HealCheckNotice 1;
BA_ "EventCommandSignal" SG_ 888 BMC_HealCheckNotice 0;
BA_ "GenSigSendType" SG_ 888 BMC_ChgFulNotice 1;
BA_ "GatewayedSignals" SG_ 888 BMC_ChgFulNotice 1;
BA_ "EventCommandSignal" SG_ 888 BMC_ChgFulNotice 0;
BA_ "GenSigSendType" SG_ 888 BMC_InslStChkMsgWarn 1;
BA_ "GatewayedSignals" SG_ 888 BMC_InslStChkMsgWarn 1;
BA_ "EventCommandSignal" SG_ 888 BMC_InslStChkMsgWarn 0;
BA_ "GenSigSendType" SG_ 1835 IDC_Diag_Request 1;
BA_ "EventCommandSignal" SG_ 1835 IDC_Diag_Request 0;
BA_ "GenSigStartValue" SG_ 1359 CCU_NMNodeAddress 79;
BA_ "GenSigSendType" SG_ 1359 CCU_NMNodeAddress 1;
BA_ "EventCommandSignal" SG_ 1359 CCU_NMNodeAddress 0;
BA_ "GenSigSendType" SG_ 1359 CCU_NMDataField 1;
BA_ "EventCommandSignal" SG_ 1359 CCU_NMDataField 0;
BA_ "GenSigSendType" SG_ 1359 CCU_PNCInformation0 1;
BA_ "EventCommandSignal" SG_ 1359 CCU_PNCInformation0 0;
BA_ "GenSigSendType" SG_ 1359 CCU_PNCInformation1 1;
BA_ "EventCommandSignal" SG_ 1359 CCU_PNCInformation1 0;
BA_ "GenSigSendType" SG_ 2015 Fun_Diag_Request 1;
BA_ "EventCommandSignal" SG_ 2015 Fun_Diag_Request 0;
BA_ "GenSigSendType" SG_ 512 KAE_phone_Number 1;
BA_ "GatewayedSignals" SG_ 512 KAE_phone_Number 0;
BA_ "EventCommandSignal" SG_ 512 KAE_phone_Number 0;
BA_ "GenSigSendType" SG_ 512 KAE_KeyToken 0;
BA_ "GatewayedSignals" SG_ 512 KAE_KeyToken 1;
BA_ "EventCommandSignal" SG_ 512 KAE_KeyToken 1;
BA_ "GenSigSendType" SG_ 403 ADC_ICMADASFailureLamp 1;
BA_ "GenSigTimeoutValue" SG_ 403 ADC_ICMADASFailureLamp 1;
BA_ "GatewayedSignals" SG_ 403 ADC_ICMADASFailureLamp 0;
BA_ "EventCommandSignal" SG_ 403 ADC_ICMADASFailureLamp 0;
BA_ "Remark" SG_ 403 ADC_ICMADASFailureLamp "<E2E_Group1>";
BA_ "Remark" SG_ 403 ADC_HFIconColor "<E2E_Group1>";
BA_ "EventCommandSignal" SG_ 403 ADC_HFIconColor 0;
BA_ "GenSigTimeoutValue" SG_ 403 ADC_HFIconColor 4;
BA_ "GenSigSendType" SG_ 403 ADC_HFIconColor 1;
BA_ "Remark" SG_ 403 ADC_1_CRC "<E2E_Group1>";
BA_ "GenSigSendType" SG_ 403 ADC_1_CRC 1;
BA_ "GatewayedSignals" SG_ 403 ADC_1_CRC 1;
BA_ "EventCommandSignal" SG_ 403 ADC_1_CRC 0;
BA_ "Remark" SG_ 403 ADC_1_Counter "<E2E_Group1>";
BA_ "GenSigSendType" SG_ 403 ADC_1_Counter 1;
BA_ "GatewayedSignals" SG_ 403 ADC_1_Counter 1;
BA_ "EventCommandSignal" SG_ 403 ADC_1_Counter 0;
BA_ "Remark" SG_ 403 ADC_ACCMode "<E2E_Group1>";
BA_ "GenSigStartValue" SG_ 403 ADC_ACCMode 1;
BA_ "GenSigSendType" SG_ 403 ADC_ACCMode 1;
BA_ "GatewayedSignals" SG_ 403 ADC_ACCMode 1;
BA_ "EventCommandSignal" SG_ 403 ADC_ACCMode 0;
BA_ "Remark" SG_ 403 ADC_ISLC_ConfirmSt "<E2E_Group1>";
BA_ "GenSigInvalidValue" SG_ 403 ADC_ISLC_ConfirmSt 3;
BA_ "GenSigSendType" SG_ 403 ADC_ISLC_ConfirmSt 1;
BA_ "GatewayedSignals" SG_ 403 ADC_ISLC_ConfirmSt 1;
BA_ "EventCommandSignal" SG_ 403 ADC_ISLC_ConfirmSt 0;
BA_ "Remark" SG_ 403 ADC_ACCTakeOverReq "<E2E_Group1>";
BA_ "GenSigSendType" SG_ 403 ADC_ACCTakeOverReq 1;
BA_ "GatewayedSignals" SG_ 403 ADC_ACCTakeOverReq 1;
BA_ "EventCommandSignal" SG_ 403 ADC_ACCTakeOverReq 0;
BA_ "Remark" SG_ 403 ADC_ISLCSt "<E2E_Group1>";
BA_ "GenSigSendType" SG_ 403 ADC_ISLCSt 1;
BA_ "GatewayedSignals" SG_ 403 ADC_ISLCSt 1;
BA_ "EventCommandSignal" SG_ 403 ADC_ISLCSt 0;
BA_ "Remark" SG_ 403 ADC_TimeGapSet "<E2E_Group1>";
BA_ "GenSigSendType" SG_ 403 ADC_TimeGapSet 1;
BA_ "GatewayedSignals" SG_ 403 ADC_TimeGapSet 1;
BA_ "EventCommandSignal" SG_ 403 ADC_TimeGapSet 0;
BA_ "Remark" SG_ 403 ADC_ILC_EnableSt "<E2E_Group1>";
BA_ "GenSigSendType" SG_ 403 ADC_ILC_EnableSt 1;
BA_ "EventCommandSignal" SG_ 403 ADC_ILC_EnableSt 0;
BA_ "Remark" SG_ 403 ADC_ILOA_EnableSt "<E2E_Group1>";
BA_ "GenSigSendType" SG_ 403 ADC_ILOA_EnableSt 1;
BA_ "EventCommandSignal" SG_ 403 ADC_ILOA_EnableSt 0;
BA_ "Remark" SG_ 403 ADC_ICMADASFailureText "<E2E_Group1>";
BA_ "GenSigInvalidValue" SG_ 403 ADC_ICMADASFailureText 15;
BA_ "GenSigSendType" SG_ 403 ADC_ICMADASFailureText 1;
BA_ "EventCommandSignal" SG_ 403 ADC_ICMADASFailureText 0;
BA_ "GenSigTimeoutValue" SG_ 403 ADC_ICMADASFailureText 15;
BA_ "Remark" SG_ 403 ADC_ICMADASWarnText "<E2E_Group1>";
BA_ "GenSigSendType" SG_ 403 ADC_ICMADASWarnText 1;
BA_ "EventCommandSignal" SG_ 403 ADC_ICMADASWarnText 0;
BA_ "Remark" SG_ 403 ADC_SpeedLimitIconSt "<E2E_Group1>";
BA_ "GenSigSendType" SG_ 403 ADC_SpeedLimitIconSt 1;
BA_ "EventCommandSignal" SG_ 403 ADC_SpeedLimitIconSt 0;
BA_ "Remark" SG_ 403 ADC_ICMWarnCardSt "<E2E_Group1>";
BA_ "GenSigSendType" SG_ 403 ADC_ICMWarnCardSt 1;
BA_ "EventCommandSignal" SG_ 403 ADC_ICMWarnCardSt 0;
BA_ "Remark" SG_ 403 ADC_ICAIconColor "<E2E_Group1>";
BA_ "GenSigSendType" SG_ 403 ADC_ICAIconColor 1;
BA_ "EventCommandSignal" SG_ 403 ADC_ICAIconColor 0;
BA_ "GenSigTimeoutValue" SG_ 403 ADC_ICAIconColor 4;
BA_ "Remark" SG_ 403 ADC_ICMPromptWarn "<E2E_Group1>";
BA_ "GenSigSendType" SG_ 403 ADC_ICMPromptWarn 1;
BA_ "EventCommandSignal" SG_ 403 ADC_ICMPromptWarn 0;
BA_ "Remark" SG_ 403 ADC_NDAIconColor "<E2E_Group1>";
BA_ "GenSigSendType" SG_ 403 ADC_NDAIconColor 1;
BA_ "EventCommandSignal" SG_ 403 ADC_NDAIconColor 0;
BA_ "GenSigTimeoutValue" SG_ 403 ADC_NDAIconColor 4;
BA_ "Remark" SG_ 403 ADC_ACUVoiceWarn "<E2E_Group1>";
BA_ "GenSigSendType" SG_ 403 ADC_ACUVoiceWarn 1;
BA_ "EventCommandSignal" SG_ 403 ADC_ACUVoiceWarn 0;
BA_ "Remark" SG_ 403 ADC_NDAStateIcon "<E2E_Group1>";
BA_ "GenSigSendType" SG_ 403 ADC_NDAStateIcon 1;
BA_ "EventCommandSignal" SG_ 403 ADC_NDAStateIcon 0;
BA_ "GenSigTimeoutValue" SG_ 403 ADC_NDAStateIcon 4;
BA_ "Remark" SG_ 403 ADC_SpeedLimitIcon "<E2E_Group1>";
BA_ "GenSigStartValue" SG_ 403 ADC_SpeedLimitIcon 255;
BA_ "GenSigInvalidValue" SG_ 403 ADC_SpeedLimitIcon 255;
BA_ "GenSigSendType" SG_ 403 ADC_SpeedLimitIcon 1;
BA_ "EventCommandSignal" SG_ 403 ADC_SpeedLimitIcon 0;
BA_ "GenSigTimeoutValue" SG_ 403 ADC_SpeedLimitIcon 255;
BA_ "Remark" SG_ 403 ADC_ICANDAIconAngle "<E2E_Group1>";
BA_ "GenSigStartValue" SG_ 403 ADC_ICANDAIconAngle 90;
BA_ "GenSigSendType" SG_ 403 ADC_ICANDAIconAngle 1;
BA_ "EventCommandSignal" SG_ 403 ADC_ICANDAIconAngle 0;
BA_ "Remark" SG_ 403 ADC_ACCTargetSpeedCard "<E2E_Group1>";
BA_ "GenSigStartValue" SG_ 403 ADC_ACCTargetSpeedCard 255;
BA_ "GenSigInvalidValue" SG_ 403 ADC_ACCTargetSpeedCard 255;
BA_ "GenSigSendType" SG_ 403 ADC_ACCTargetSpeedCard 1;
BA_ "EventCommandSignal" SG_ 403 ADC_ACCTargetSpeedCard 0;
BA_ "GenSigTimeoutValue" SG_ 403 ADC_ACCTargetSpeedCard 255;
BA_ "Remark" SG_ 403 ADC_ACCIconColor "<E2E_Group1>";
BA_ "GenSigSendType" SG_ 403 ADC_ACCIconColor 1;
BA_ "EventCommandSignal" SG_ 403 ADC_ACCIconColor 0;
BA_ "GenSigTimeoutValue" SG_ 403 ADC_ACCIconColor 4;
BA_ "Remark" SG_ 411 ADC_RCTAWarnRight "<E2E_Group1>";
BA_ "EventCommandSignal" SG_ 411 ADC_RCTAWarnRight 0;
BA_ "GatewayedSignals" SG_ 411 ADC_RCTAWarnRight 0;
BA_ "GenSigSendType" SG_ 411 ADC_RCTAWarnRight 1;
BA_ "Remark" SG_ 411 ADC_RCTAWarnLeft "<E2E_Group1>";
BA_ "EventCommandSignal" SG_ 411 ADC_RCTAWarnLeft 0;
BA_ "GatewayedSignals" SG_ 411 ADC_RCTAWarnLeft 0;
BA_ "GenSigSendType" SG_ 411 ADC_RCTAWarnLeft 1;
BA_ "Remark" SG_ 411 ADC_FCWAssistType "<E2E_Group1>";
BA_ "GenSigInvalidValue" SG_ 411 ADC_FCWAssistType 2;
BA_ "GenSigSendType" SG_ 411 ADC_FCWAssistType 1;
BA_ "GatewayedSignals" SG_ 411 ADC_FCWAssistType 1;
BA_ "EventCommandSignal" SG_ 411 ADC_FCWAssistType 0;
BA_ "GenSigTimeoutValue" SG_ 411 ADC_FCWAssistType 2;
BA_ "Remark" SG_ 411 ADC_FCWFaultSt "<E2E_Group1>";
BA_ "GenSigInvalidValue" SG_ 411 ADC_FCWFaultSt 1;
BA_ "GenSigSendType" SG_ 411 ADC_FCWFaultSt 1;
BA_ "GatewayedSignals" SG_ 411 ADC_FCWFaultSt 1;
BA_ "EventCommandSignal" SG_ 411 ADC_FCWFaultSt 0;
BA_ "GenSigTimeoutValue" SG_ 411 ADC_FCWFaultSt 1;
BA_ "Remark" SG_ 411 ADC_FCWPreWarn "<E2E_Group1>";
BA_ "GenSigSendType" SG_ 411 ADC_FCWPreWarn 1;
BA_ "GatewayedSignals" SG_ 411 ADC_FCWPreWarn 1;
BA_ "EventCommandSignal" SG_ 411 ADC_FCWPreWarn 0;
BA_ "Remark" SG_ 411 ADC_FCWLatentWarn "<E2E_Group1>";
BA_ "GenSigSendType" SG_ 411 ADC_FCWLatentWarn 1;
BA_ "GatewayedSignals" SG_ 411 ADC_FCWLatentWarn 1;
BA_ "EventCommandSignal" SG_ 411 ADC_FCWLatentWarn 0;
BA_ "Remark" SG_ 411 ADC_FCWWarmDistance "<E2E_Group1>";
BA_ "GenSigSendType" SG_ 411 ADC_FCWWarmDistance 1;
BA_ "GatewayedSignals" SG_ 411 ADC_FCWWarmDistance 1;
BA_ "EventCommandSignal" SG_ 411 ADC_FCWWarmDistance 0;
BA_ "GenSigTimeoutValue" SG_ 411 ADC_FCWWarmDistance 1;
BA_ "Remark" SG_ 411 ADC_AEBTarObjType "<E2E_Group1>";
BA_ "GenSigSendType" SG_ 411 ADC_AEBTarObjType 1;
BA_ "GatewayedSignals" SG_ 411 ADC_AEBTarObjType 1;
BA_ "EventCommandSignal" SG_ 411 ADC_AEBTarObjType 0;
BA_ "Remark" SG_ 411 ADC_AEBInterventionSt "<E2E_Group1>";
BA_ "GenSigSendType" SG_ 411 ADC_AEBInterventionSt 1;
BA_ "GatewayedSignals" SG_ 411 ADC_AEBInterventionSt 1;
BA_ "EventCommandSignal" SG_ 411 ADC_AEBInterventionSt 0;
BA_ "Remark" SG_ 411 ADC_DOWAudioWarnFR "<E2E_Group1>";
BA_ "GenSigSendType" SG_ 411 ADC_DOWAudioWarnFR 1;
BA_ "GatewayedSignals" SG_ 411 ADC_DOWAudioWarnFR 1;
BA_ "EventCommandSignal" SG_ 411 ADC_DOWAudioWarnFR 0;
BA_ "Remark" SG_ 411 ADC_DOWAudioWarnFL "<E2E_Group1>";
BA_ "GenSigSendType" SG_ 411 ADC_DOWAudioWarnFL 1;
BA_ "GatewayedSignals" SG_ 411 ADC_DOWAudioWarnFL 1;
BA_ "EventCommandSignal" SG_ 411 ADC_DOWAudioWarnFL 0;
BA_ "Remark" SG_ 411 ADC_DOWAudioWarnRR "<E2E_Group1>";
BA_ "GenSigSendType" SG_ 411 ADC_DOWAudioWarnRR 1;
BA_ "GatewayedSignals" SG_ 411 ADC_DOWAudioWarnRR 1;
BA_ "EventCommandSignal" SG_ 411 ADC_DOWAudioWarnRR 0;
BA_ "Remark" SG_ 411 ADC_DOWAudioWarnRL "<E2E_Group1>";
BA_ "GenSigSendType" SG_ 411 ADC_DOWAudioWarnRL 1;
BA_ "GatewayedSignals" SG_ 411 ADC_DOWAudioWarnRL 1;
BA_ "EventCommandSignal" SG_ 411 ADC_DOWAudioWarnRL 0;
BA_ "Remark" SG_ 411 ADC_DOWIALWarnFR "<E2E_Group1>";
BA_ "GenSigSendType" SG_ 411 ADC_DOWIALWarnFR 1;
BA_ "GatewayedSignals" SG_ 411 ADC_DOWIALWarnFR 1;
BA_ "EventCommandSignal" SG_ 411 ADC_DOWIALWarnFR 0;
BA_ "Remark" SG_ 411 ADC_DOWIALWarnRR "<E2E_Group1>";
BA_ "GenSigSendType" SG_ 411 ADC_DOWIALWarnRR 1;
BA_ "GatewayedSignals" SG_ 411 ADC_DOWIALWarnRR 1;
BA_ "EventCommandSignal" SG_ 411 ADC_DOWIALWarnRR 0;
BA_ "Remark" SG_ 411 ADC_BSDLCASt "<E2E_Group1>";
BA_ "GenSigSendType" SG_ 411 ADC_BSDLCASt 1;
BA_ "GatewayedSignals" SG_ 411 ADC_BSDLCASt 1;
BA_ "EventCommandSignal" SG_ 411 ADC_BSDLCASt 0;
BA_ "GenSigTimeoutValue" SG_ 411 ADC_BSDLCASt 3;
BA_ "Remark" SG_ 411 ADC_RCTASt "<E2E_Group1>";
BA_ "GenSigSendType" SG_ 411 ADC_RCTASt 1;
BA_ "GatewayedSignals" SG_ 411 ADC_RCTASt 1;
BA_ "EventCommandSignal" SG_ 411 ADC_RCTASt 0;
BA_ "GenSigTimeoutValue" SG_ 411 ADC_RCTASt 3;
BA_ "Remark" SG_ 411 ADC_RCTAAssistType "<E2E_Group1>";
BA_ "GenSigSendType" SG_ 411 ADC_RCTAAssistType 1;
BA_ "GatewayedSignals" SG_ 411 ADC_RCTAAssistType 1;
BA_ "EventCommandSignal" SG_ 411 ADC_RCTAAssistType 0;
BA_ "Remark" SG_ 411 ADC_DOWSt "<E2E_Group1>";
BA_ "GenSigSendType" SG_ 411 ADC_DOWSt 1;
BA_ "GatewayedSignals" SG_ 411 ADC_DOWSt 1;
BA_ "EventCommandSignal" SG_ 411 ADC_DOWSt 0;
BA_ "GenSigTimeoutValue" SG_ 411 ADC_DOWSt 3;
BA_ "Remark" SG_ 411 ADC_RCWSt "<E2E_Group1>";
BA_ "GenSigSendType" SG_ 411 ADC_RCWSt 1;
BA_ "GatewayedSignals" SG_ 411 ADC_RCWSt 1;
BA_ "EventCommandSignal" SG_ 411 ADC_RCWSt 0;
BA_ "GenSigTimeoutValue" SG_ 411 ADC_RCWSt 3;
BA_ "Remark" SG_ 411 ADC_FCTASt "<E2E_Group1>";
BA_ "GenSigSendType" SG_ 411 ADC_FCTASt 1;
BA_ "GatewayedSignals" SG_ 411 ADC_FCTASt 1;
BA_ "EventCommandSignal" SG_ 411 ADC_FCTASt 0;
BA_ "GenSigTimeoutValue" SG_ 411 ADC_FCTASt 3;
BA_ "Remark" SG_ 411 ADC_FCTAAssistType "<E2E_Group1>";
BA_ "GenSigSendType" SG_ 411 ADC_FCTAAssistType 1;
BA_ "GatewayedSignals" SG_ 411 ADC_FCTAAssistType 1;
BA_ "EventCommandSignal" SG_ 411 ADC_FCTAAssistType 0;
BA_ "Remark" SG_ 411 ADC_FCTAWarnL "<E2E_Group1>";
BA_ "GenSigSendType" SG_ 411 ADC_FCTAWarnL 1;
BA_ "GatewayedSignals" SG_ 411 ADC_FCTAWarnL 1;
BA_ "EventCommandSignal" SG_ 411 ADC_FCTAWarnL 0;
BA_ "Remark" SG_ 411 ADC_FCTAWarnR "<E2E_Group1>";
BA_ "GenSigSendType" SG_ 411 ADC_FCTAWarnR 1;
BA_ "GatewayedSignals" SG_ 411 ADC_FCTAWarnR 1;
BA_ "EventCommandSignal" SG_ 411 ADC_FCTAWarnR 0;
BA_ "Remark" SG_ 411 ADC_LDS_LaneAssistType "<E2E_Group1>";
BA_ "GenSigSendType" SG_ 411 ADC_LDS_LaneAssistType 1;
BA_ "GatewayedSignals" SG_ 411 ADC_LDS_LaneAssistType 1;
BA_ "EventCommandSignal" SG_ 411 ADC_LDS_LaneAssistType 0;
BA_ "Remark" SG_ 411 ADC_IHBC_EnableSt "<E2E_Group1>";
BA_ "GenSigSendType" SG_ 411 ADC_IHBC_EnableSt 1;
BA_ "GatewayedSignals" SG_ 411 ADC_IHBC_EnableSt 1;
BA_ "EventCommandSignal" SG_ 411 ADC_IHBC_EnableSt 0;
BA_ "Remark" SG_ 411 ADC_TSR_EnableSt "<E2E_Group1>";
BA_ "GenSigSendType" SG_ 411 ADC_TSR_EnableSt 1;
BA_ "GatewayedSignals" SG_ 411 ADC_TSR_EnableSt 1;
BA_ "EventCommandSignal" SG_ 411 ADC_TSR_EnableSt 0;
BA_ "Remark" SG_ 411 ADC_TSR__AudioWarn_EnableSt "<E2E_Group1>";
BA_ "GenSigSendType" SG_ 411 ADC_TSR__AudioWarn_EnableSt 1;
BA_ "GatewayedSignals" SG_ 411 ADC_TSR__AudioWarn_EnableSt 1;
BA_ "EventCommandSignal" SG_ 411 ADC_TSR__AudioWarn_EnableSt 0;
BA_ "Remark" SG_ 411 ADC_ELK_EnableSt "<E2E_Group1>";
BA_ "GenSigSendType" SG_ 411 ADC_ELK_EnableSt 1;
BA_ "GatewayedSignals" SG_ 411 ADC_ELK_EnableSt 1;
BA_ "EventCommandSignal" SG_ 411 ADC_ELK_EnableSt 0;
BA_ "Remark" SG_ 411 ADC_ESA_EnableSt "<E2E_Group1>";
BA_ "GenSigSendType" SG_ 411 ADC_ESA_EnableSt 1;
BA_ "GatewayedSignals" SG_ 411 ADC_ESA_EnableSt 1;
BA_ "EventCommandSignal" SG_ 411 ADC_ESA_EnableSt 0;
BA_ "Remark" SG_ 411 ADC_AES_EnableSt "<E2E_Group1>";
BA_ "GenSigSendType" SG_ 411 ADC_AES_EnableSt 1;
BA_ "GatewayedSignals" SG_ 411 ADC_AES_EnableSt 1;
BA_ "EventCommandSignal" SG_ 411 ADC_AES_EnableSt 0;
BA_ "Remark" SG_ 411 ADC_TSR_SpdLimit "<E2E_Group1>";
BA_ "GenSigSendType" SG_ 411 ADC_TSR_SpdLimit 1;
BA_ "GatewayedSignals" SG_ 411 ADC_TSR_SpdLimit 1;
BA_ "EventCommandSignal" SG_ 411 ADC_TSR_SpdLimit 0;
BA_ "Remark" SG_ 411 ADC_TSR_SpdLimitUnit "<E2E_Group1>";
BA_ "GenSigSendType" SG_ 411 ADC_TSR_SpdLimitUnit 1;
BA_ "GatewayedSignals" SG_ 411 ADC_TSR_SpdLimitUnit 1;
BA_ "EventCommandSignal" SG_ 411 ADC_TSR_SpdLimitUnit 0;
BA_ "GenSigSendType" SG_ 419 ADC_AssistParaSwitchReq 1;
BA_ "GatewayedSignals" SG_ 419 ADC_AssistParaSwitchReq 1;
BA_ "EventCommandSignal" SG_ 419 ADC_AssistParaSwitchReq 0;
BA_ "GenSigSendType" SG_ 419 ADC_AEBFaultSt 1;
BA_ "GatewayedSignals" SG_ 419 ADC_AEBFaultSt 1;
BA_ "EventCommandSignal" SG_ 419 ADC_AEBFaultSt 0;
BA_ "GenSigTimeoutValue" SG_ 419 ADC_AEBFaultSt 1;
BA_ "GenSigSendType" SG_ 419 ADC_AEBOffSt 1;
BA_ "GatewayedSignals" SG_ 419 ADC_AEBOffSt 1;
BA_ "EventCommandSignal" SG_ 419 ADC_AEBOffSt 0;
BA_ "GenSigTimeoutValue" SG_ 419 ADC_AEBOffSt 1;
BA_ "GenSigSendType" SG_ 419 ADC_AEBInterventionSt 1;
BA_ "GatewayedSignals" SG_ 419 ADC_AEBInterventionSt 1;
BA_ "EventCommandSignal" SG_ 419 ADC_AEBInterventionSt 0;
BA_ "GenSigSendType" SG_ 419 ADC_4_FreshnessValue 1;
BA_ "GatewayedSignals" SG_ 419 ADC_4_FreshnessValue 1;
BA_ "EventCommandSignal" SG_ 419 ADC_4_FreshnessValue 0;
BA_ "GenSigSendType" SG_ 419 ADC_4_MAC_Check 1;
BA_ "GatewayedSignals" SG_ 419 ADC_4_MAC_Check 1;
BA_ "EventCommandSignal" SG_ 419 ADC_4_MAC_Check 0;
BA_ "GenSigSendType" SG_ 404 ADC_ICMWarnCardSt_B 1;
BA_ "EventCommandSignal" SG_ 404 ADC_ICMWarnCardSt_B 0;
BA_ "GenSigSendType" SG_ 404 ADC_ICMPromptWarn_B 1;
BA_ "EventCommandSignal" SG_ 404 ADC_ICMPromptWarn_B 0;
BA_ "GenSigSendType" SG_ 404 ADC_1_B_FreshnessValue 1;
BA_ "EventCommandSignal" SG_ 404 ADC_1_B_FreshnessValue 0;
BA_ "GenSigSendType" SG_ 404 ADC_1_B_MAC_Check 1;
BA_ "EventCommandSignal" SG_ 404 ADC_1_B_MAC_Check 0;
BA_ "Remark" SG_ 437 IFC_1_CRC "<E2E_Group1>";
BA_ "GenSigSendType" SG_ 437 IFC_1_CRC 1;
BA_ "GatewayedSignals" SG_ 437 IFC_1_CRC 1;
BA_ "EventCommandSignal" SG_ 437 IFC_1_CRC 0;
BA_ "Remark" SG_ 437 IFC_1_Counter "<E2E_Group1>";
BA_ "GenSigSendType" SG_ 437 IFC_1_Counter 1;
BA_ "GatewayedSignals" SG_ 437 IFC_1_Counter 1;
BA_ "EventCommandSignal" SG_ 437 IFC_1_Counter 0;
BA_ "Remark" SG_ 437 IFC_ICMWarnCardSt "<E2E_Group1>";
BA_ "GenSigSendType" SG_ 437 IFC_ICMWarnCardSt 1;
BA_ "GatewayedSignals" SG_ 437 IFC_ICMWarnCardSt 1;
BA_ "EventCommandSignal" SG_ 437 IFC_ICMWarnCardSt 0;
BA_ "Remark" SG_ 437 IFC_ICMPromptWarn "<E2E_Group1>";
BA_ "GenSigSendType" SG_ 437 IFC_ICMPromptWarn 1;
BA_ "GatewayedSignals" SG_ 437 IFC_ICMPromptWarn 1;
BA_ "EventCommandSignal" SG_ 437 IFC_ICMPromptWarn 0;
BA_ "GenSigSendType" SG_ 773 WCM_ChargingSt 1;
BA_ "GatewayedSignals" SG_ 773 WCM_ChargingSt 1;
BA_ "EventCommandSignal" SG_ 773 WCM_ChargingSt 0;
BA_ "GenSigSendType" SG_ 773 WCM_ControlResult 1;
BA_ "GatewayedSignals" SG_ 773 WCM_ControlResult 1;
BA_ "EventCommandSignal" SG_ 773 WCM_ControlResult 0;
BA_ "GenSigSendType" SG_ 773 WCM_FailureSt 1;
BA_ "GatewayedSignals" SG_ 773 WCM_FailureSt 1;
BA_ "EventCommandSignal" SG_ 773 WCM_FailureSt 0;
BA_ "GenSigSendType" SG_ 773 WCM_Reminder 1;
BA_ "GatewayedSignals" SG_ 773 WCM_Reminder 1;
BA_ "EventCommandSignal" SG_ 773 WCM_Reminder 0;
BA_ "GenSigSendType" SG_ 1078 ETC_DismountSt 1;
BA_ "GatewayedSignals" SG_ 1078 ETC_DismountSt 1;
BA_ "EventCommandSignal" SG_ 1078 ETC_DismountSt 0;
BA_ "GenSigSendType" SG_ 1078 ETC_SelfcheckSt 1;
BA_ "GatewayedSignals" SG_ 1078 ETC_SelfcheckSt 1;
BA_ "EventCommandSignal" SG_ 1078 ETC_SelfcheckSt 0;
BA_ "GenSigSendType" SG_ 1078 ETC_GateProperty 1;
BA_ "GatewayedSignals" SG_ 1078 ETC_GateProperty 1;
BA_ "EventCommandSignal" SG_ 1078 ETC_GateProperty 0;
BA_ "GenSigStartValue" SG_ 1078 ETC_TradeType 1;
BA_ "GenSigSendType" SG_ 1078 ETC_TradeType 1;
BA_ "GatewayedSignals" SG_ 1078 ETC_TradeType 1;
BA_ "EventCommandSignal" SG_ 1078 ETC_TradeType 0;
BA_ "GenSigSendType" SG_ 1078 ETC_SystemSt 1;
BA_ "GatewayedSignals" SG_ 1078 ETC_SystemSt 1;
BA_ "EventCommandSignal" SG_ 1078 ETC_SystemSt 0;
BA_ "GenSigStartValue" SG_ 1078 ETC_SysCfgst 1;
BA_ "GenSigSendType" SG_ 1078 ETC_SysCfgst 1;
BA_ "GatewayedSignals" SG_ 1078 ETC_SysCfgst 1;
BA_ "EventCommandSignal" SG_ 1078 ETC_SysCfgst 0;
BA_ "GenSigStartValue" SG_ 1078 ETC_ICMDisplayCfgst 1;
BA_ "GenSigSendType" SG_ 1078 ETC_ICMDisplayCfgst 1;
BA_ "GatewayedSignals" SG_ 1078 ETC_ICMDisplayCfgst 1;
BA_ "EventCommandSignal" SG_ 1078 ETC_ICMDisplayCfgst 0;
BA_ "GenSigStartValue" SG_ 1078 ETC_BLEenableCfgst 1;
BA_ "GenSigSendType" SG_ 1078 ETC_BLEenableCfgst 1;
BA_ "GatewayedSignals" SG_ 1078 ETC_BLEenableCfgst 1;
BA_ "EventCommandSignal" SG_ 1078 ETC_BLEenableCfgst 0;
BA_ "GenSigStartValue" SG_ 1078 ETC_ActivSt 1;
BA_ "GenSigSendType" SG_ 1078 ETC_ActivSt 1;
BA_ "GatewayedSignals" SG_ 1078 ETC_ActivSt 1;
BA_ "EventCommandSignal" SG_ 1078 ETC_ActivSt 0;
BA_ "GenSigInvalidValue" SG_ 1078 ETC_TradeInfo 1.84467440737096E+019;
BA_ "GenSigSendType" SG_ 1078 ETC_TradeInfo 1;
BA_ "GatewayedSignals" SG_ 1078 ETC_TradeInfo 1;
BA_ "EventCommandSignal" SG_ 1078 ETC_TradeInfo 0;
BA_ "GenSigSendType" SG_ 345 CCU_IDC_SecSyn 0;
BA_ "EventCommandSignal" SG_ 345 CCU_IDC_SecSyn 1;
BA_ "GenSigInvalidValue" SG_ 175 ADC_PAAChallenge1SBM 255;
BA_ "GenSigSendType" SG_ 175 ADC_PAAChallenge1SBM 0;
BA_ "GatewayedSignals" SG_ 175 ADC_PAAChallenge1SBM 1;
BA_ "EventCommandSignal" SG_ 175 ADC_PAAChallenge1SBM 1;
BA_ "GenSigInvalidValue" SG_ 175 ADC_PAAChallenge2SBM 255;
BA_ "GenSigSendType" SG_ 175 ADC_PAAChallenge2SBM 0;
BA_ "GatewayedSignals" SG_ 175 ADC_PAAChallenge2SBM 1;
BA_ "EventCommandSignal" SG_ 175 ADC_PAAChallenge2SBM 1;
BA_ "EventCommandSignal" SG_ 941 ADC_LowPowerfeedback 0;
BA_ "GatewayedSignals" SG_ 941 ADC_LowPowerfeedback 0;
BA_ "GenSigSendType" SG_ 941 ADC_LowPowerfeedback 1;
BA_ "GenSigSendType" SG_ 941 ADC_HPAStrtgEndgPointInfo 1;
BA_ "GatewayedSignals" SG_ 941 ADC_HPAStrtgEndgPointInfo 1;
BA_ "EventCommandSignal" SG_ 941 ADC_HPAStrtgEndgPointInfo 0;
BA_ "GenSigSendType" SG_ 941 ADC_HPALearningProcessInfo 1;
BA_ "GatewayedSignals" SG_ 941 ADC_HPALearningProcessInfo 1;
BA_ "EventCommandSignal" SG_ 941 ADC_HPALearningProcessInfo 0;
BA_ "GenSigSendType" SG_ 941 ADC_HPALearningFailedInfo 1;
BA_ "GatewayedSignals" SG_ 941 ADC_HPALearningFailedInfo 1;
BA_ "EventCommandSignal" SG_ 941 ADC_HPALearningFailedInfo 0;
BA_ "GenSigSendType" SG_ 941 ADC_HPALrngDst 1;
BA_ "GatewayedSignals" SG_ 941 ADC_HPALrngDst 1;
BA_ "EventCommandSignal" SG_ 941 ADC_HPALrngDst 0;
BA_ "GenSigSendType" SG_ 941 ADC_HPAResRouteLeg 1;
BA_ "GatewayedSignals" SG_ 941 ADC_HPAResRouteLeg 1;
BA_ "EventCommandSignal" SG_ 941 ADC_HPAResRouteLeg 0;
BA_ "GenSigSendType" SG_ 941 ADC_HPAUseActDis 1;
BA_ "GatewayedSignals" SG_ 941 ADC_HPAUseActDis 1;
BA_ "EventCommandSignal" SG_ 941 ADC_HPAUseActDis 0;
BA_ "GenSigSendType" SG_ 941 ADC_HPAProcRat 1;
BA_ "GatewayedSignals" SG_ 941 ADC_HPAProcRat 1;
BA_ "EventCommandSignal" SG_ 941 ADC_HPAProcRat 0;
BA_ "GenSigSendType" SG_ 941 ADC_HPAUseTolTime 1;
BA_ "GatewayedSignals" SG_ 941 ADC_HPAUseTolTime 1;
BA_ "EventCommandSignal" SG_ 941 ADC_HPAUseTolTime 0;
BA_ "GenSigSendType" SG_ 941 ADC_ParkSlotChoiceL1 1;
BA_ "GatewayedSignals" SG_ 941 ADC_ParkSlotChoiceL1 1;
BA_ "EventCommandSignal" SG_ 941 ADC_ParkSlotChoiceL1 0;
BA_ "GenSigSendType" SG_ 941 ADC_IconTwinkle 1;
BA_ "GatewayedSignals" SG_ 941 ADC_IconTwinkle 1;
BA_ "EventCommandSignal" SG_ 941 ADC_IconTwinkle 0;
BA_ "GenSigSendType" SG_ 941 ADC_ParkSlotChoiceR1 1;
BA_ "GatewayedSignals" SG_ 941 ADC_ParkSlotChoiceR1 1;
BA_ "EventCommandSignal" SG_ 941 ADC_ParkSlotChoiceR1 0;
BA_ "GenSigSendType" SG_ 941 ADC_ParkSlotChoiceL2 1;
BA_ "GatewayedSignals" SG_ 941 ADC_ParkSlotChoiceL2 1;
BA_ "EventCommandSignal" SG_ 941 ADC_ParkSlotChoiceL2 0;
BA_ "GenSigSendType" SG_ 941 ADC_ParkSlotChoiceR2 1;
BA_ "GatewayedSignals" SG_ 941 ADC_ParkSlotChoiceR2 1;
BA_ "EventCommandSignal" SG_ 941 ADC_ParkSlotChoiceR2 0;
BA_ "GenSigSendType" SG_ 941 ADC_ParkSlotChoiceL3 1;
BA_ "GatewayedSignals" SG_ 941 ADC_ParkSlotChoiceL3 1;
BA_ "EventCommandSignal" SG_ 941 ADC_ParkSlotChoiceL3 0;
BA_ "GenSigSendType" SG_ 941 ADC_ParkSlotChoiceR3 1;
BA_ "GatewayedSignals" SG_ 941 ADC_ParkSlotChoiceR3 1;
BA_ "EventCommandSignal" SG_ 941 ADC_ParkSlotChoiceR3 0;
BA_ "GenSigSendType" SG_ 941 ADC_ParkSlotChoiceL4 1;
BA_ "GatewayedSignals" SG_ 941 ADC_ParkSlotChoiceL4 1;
BA_ "EventCommandSignal" SG_ 941 ADC_ParkSlotChoiceL4 0;
BA_ "GenSigSendType" SG_ 941 ADC_ParkSlotChoiceR4 1;
BA_ "GatewayedSignals" SG_ 941 ADC_ParkSlotChoiceR4 1;
BA_ "EventCommandSignal" SG_ 941 ADC_ParkSlotChoiceR4 0;
BA_ "GenSigSendType" SG_ 941 ADC_ParkSlotChoiceL5 1;
BA_ "GatewayedSignals" SG_ 941 ADC_ParkSlotChoiceL5 1;
BA_ "EventCommandSignal" SG_ 941 ADC_ParkSlotChoiceL5 0;
BA_ "GenSigSendType" SG_ 941 ADC_ParkSlotChoiceR5 1;
BA_ "GatewayedSignals" SG_ 941 ADC_ParkSlotChoiceR5 1;
BA_ "EventCommandSignal" SG_ 941 ADC_ParkSlotChoiceR5 0;
BA_ "GenSigSendType" SG_ 941 ADC_ParkSlotChoiceL6 1;
BA_ "GatewayedSignals" SG_ 941 ADC_ParkSlotChoiceL6 1;
BA_ "EventCommandSignal" SG_ 941 ADC_ParkSlotChoiceL6 0;
BA_ "GenSigSendType" SG_ 941 ADC_ParkSlotChoiceR6 1;
BA_ "GatewayedSignals" SG_ 941 ADC_ParkSlotChoiceR6 1;
BA_ "EventCommandSignal" SG_ 941 ADC_ParkSlotChoiceR6 0;
BA_ "GenSigSendType" SG_ 941 ADC_ParkSlotChoiceL7 1;
BA_ "GatewayedSignals" SG_ 941 ADC_ParkSlotChoiceL7 1;
BA_ "EventCommandSignal" SG_ 941 ADC_ParkSlotChoiceL7 0;
BA_ "GenSigSendType" SG_ 941 ADC_ParkSlotChoiceR7 1;
BA_ "GatewayedSignals" SG_ 941 ADC_ParkSlotChoiceR7 1;
BA_ "EventCommandSignal" SG_ 941 ADC_ParkSlotChoiceR7 0;
BA_ "GenSigSendType" SG_ 941 ADC_ParkSlotChoiceL8 1;
BA_ "GatewayedSignals" SG_ 941 ADC_ParkSlotChoiceL8 1;
BA_ "EventCommandSignal" SG_ 941 ADC_ParkSlotChoiceL8 0;
BA_ "GenSigSendType" SG_ 941 ADC_ParkSlotChoiceR8 1;
BA_ "GatewayedSignals" SG_ 941 ADC_ParkSlotChoiceR8 1;
BA_ "EventCommandSignal" SG_ 941 ADC_ParkSlotChoiceR8 0;
BA_ "GenSigSendType" SG_ 941 ADC_SlotSelectFebk 1;
BA_ "GatewayedSignals" SG_ 941 ADC_SlotSelectFebk 1;
BA_ "EventCommandSignal" SG_ 941 ADC_SlotSelectFebk 0;
BA_ "GenSigSendType" SG_ 941 ADC_AVPParkSlotInfo 1;
BA_ "GatewayedSignals" SG_ 941 ADC_AVPParkSlotInfo 1;
BA_ "EventCommandSignal" SG_ 941 ADC_AVPParkSlotInfo 0;
BA_ "GenSigSendType" SG_ 941 ADC_SwitchStShow 1;
BA_ "GatewayedSignals" SG_ 941 ADC_SwitchStShow 1;
BA_ "EventCommandSignal" SG_ 941 ADC_SwitchStShow 0;
BA_ "GatewayedSignals" SG_ 941 FAPA_RPAShortPresSuppSt 1;
BA_ "GenSigSendType" SG_ 941 ADC_HPASwitchStShow 1;
BA_ "GatewayedSignals" SG_ 941 ADC_HPASwitchStShow 1;
BA_ "EventCommandSignal" SG_ 941 ADC_HPASwitchStShow 0;
BA_ "GenSigSendType" SG_ 941 ADC_AVPSwitchStShow 1;
BA_ "GatewayedSignals" SG_ 941 ADC_AVPSwitchStShow 1;
BA_ "EventCommandSignal" SG_ 941 ADC_AVPSwitchStShow 0;
BA_ "GenSigSendType" SG_ 941 ADC_HPALearningPathType1 1;
BA_ "GatewayedSignals" SG_ 941 ADC_HPALearningPathType1 1;
BA_ "EventCommandSignal" SG_ 941 ADC_HPALearningPathType1 0;
BA_ "GenSigSendType" SG_ 941 ADC_HPALearningLotType1 1;
BA_ "GatewayedSignals" SG_ 941 ADC_HPALearningLotType1 1;
BA_ "EventCommandSignal" SG_ 941 ADC_HPALearningLotType1 0;
BA_ "GenSigSendType" SG_ 941 ADC_HPALearningPathNum1 1;
BA_ "GatewayedSignals" SG_ 941 ADC_HPALearningPathNum1 1;
BA_ "EventCommandSignal" SG_ 941 ADC_HPALearningPathNum1 0;
BA_ "GenSigSendType" SG_ 941 ADC_HPAPathLearnRate1 1;
BA_ "GatewayedSignals" SG_ 941 ADC_HPAPathLearnRate1 1;
BA_ "EventCommandSignal" SG_ 941 ADC_HPAPathLearnRate1 0;
BA_ "GenSigSendType" SG_ 941 ADC_HPAPathSt1 1;
BA_ "GatewayedSignals" SG_ 941 ADC_HPAPathSt1 1;
BA_ "EventCommandSignal" SG_ 941 ADC_HPAPathSt1 0;
BA_ "GenSigSendType" SG_ 941 ADC_HPAPath1Src 1;
BA_ "GatewayedSignals" SG_ 941 ADC_HPAPath1Src 1;
BA_ "EventCommandSignal" SG_ 941 ADC_HPAPath1Src 0;
BA_ "GenSigSendType" SG_ 941 ADC_HPAPathDst1 1;
BA_ "GatewayedSignals" SG_ 941 ADC_HPAPathDst1 1;
BA_ "EventCommandSignal" SG_ 941 ADC_HPAPathDst1 0;
BA_ "GenSigSendType" SG_ 941 ADC_HPALearningPathNum2 1;
BA_ "GatewayedSignals" SG_ 941 ADC_HPALearningPathNum2 1;
BA_ "EventCommandSignal" SG_ 941 ADC_HPALearningPathNum2 0;
BA_ "GenSigSendType" SG_ 941 ADC_HPAHAVPPathLearnRate2 1;
BA_ "GatewayedSignals" SG_ 941 ADC_HPAHAVPPathLearnRate2 1;
BA_ "EventCommandSignal" SG_ 941 ADC_HPAHAVPPathLearnRate2 0;
BA_ "GenSigSendType" SG_ 941 ADC_HPALearningPathType2 1;
BA_ "GatewayedSignals" SG_ 941 ADC_HPALearningPathType2 1;
BA_ "EventCommandSignal" SG_ 941 ADC_HPALearningPathType2 0;
BA_ "GenSigSendType" SG_ 941 ADC_HPALearningLotType2 1;
BA_ "GatewayedSignals" SG_ 941 ADC_HPALearningLotType2 1;
BA_ "EventCommandSignal" SG_ 941 ADC_HPALearningLotType2 0;
BA_ "GenSigSendType" SG_ 941 ADC_HPAPathSt2 1;
BA_ "GatewayedSignals" SG_ 941 ADC_HPAPathSt2 1;
BA_ "EventCommandSignal" SG_ 941 ADC_HPAPathSt2 0;
BA_ "GenSigSendType" SG_ 941 ADC_HPAPath2Src 1;
BA_ "GatewayedSignals" SG_ 941 ADC_HPAPath2Src 1;
BA_ "EventCommandSignal" SG_ 941 ADC_HPAPath2Src 0;
BA_ "GenSigSendType" SG_ 941 ADC_HPAPathDst2 1;
BA_ "GatewayedSignals" SG_ 941 ADC_HPAPathDst2 1;
BA_ "EventCommandSignal" SG_ 941 ADC_HPAPathDst2 0;
BA_ "GenSigSendType" SG_ 941 ADC_HPAPath1MatGpsSucces 1;
BA_ "GatewayedSignals" SG_ 941 ADC_HPAPath1MatGpsSucces 1;
BA_ "EventCommandSignal" SG_ 941 ADC_HPAPath1MatGpsSucces 0;
BA_ "GenSigSendType" SG_ 941 ADC_HPAPath2MatGpsSucces 1;
BA_ "GatewayedSignals" SG_ 941 ADC_HPAPath2MatGpsSucces 1;
BA_ "EventCommandSignal" SG_ 941 ADC_HPAPath2MatGpsSucces 0;
BA_ "GenSigSendType" SG_ 941 ADC_HPALearningPathType3 1;
BA_ "GatewayedSignals" SG_ 941 ADC_HPALearningPathType3 1;
BA_ "EventCommandSignal" SG_ 941 ADC_HPALearningPathType3 0;
BA_ "GenSigSendType" SG_ 941 ADC_HPALearningPathNum3 1;
BA_ "GatewayedSignals" SG_ 941 ADC_HPALearningPathNum3 1;
BA_ "EventCommandSignal" SG_ 941 ADC_HPALearningPathNum3 0;
BA_ "GenSigSendType" SG_ 941 ADC_HPAPathLearnRate3 1;
BA_ "GatewayedSignals" SG_ 941 ADC_HPAPathLearnRate3 1;
BA_ "EventCommandSignal" SG_ 941 ADC_HPAPathLearnRate3 0;
BA_ "GenSigSendType" SG_ 941 ADC_HPALearningLotType3 1;
BA_ "GatewayedSignals" SG_ 941 ADC_HPALearningLotType3 1;
BA_ "EventCommandSignal" SG_ 941 ADC_HPALearningLotType3 0;
BA_ "GenSigSendType" SG_ 941 ADC_HPAPathSt3 1;
BA_ "GatewayedSignals" SG_ 941 ADC_HPAPathSt3 1;
BA_ "EventCommandSignal" SG_ 941 ADC_HPAPathSt3 0;
BA_ "GenSigSendType" SG_ 941 ADC_HPAPath3Src 1;
BA_ "GatewayedSignals" SG_ 941 ADC_HPAPath3Src 1;
BA_ "EventCommandSignal" SG_ 941 ADC_HPAPath3Src 0;
BA_ "GenSigSendType" SG_ 941 ADC_HPAPathDst3 1;
BA_ "GatewayedSignals" SG_ 941 ADC_HPAPathDst3 1;
BA_ "EventCommandSignal" SG_ 941 ADC_HPAPathDst3 0;
BA_ "GenSigSendType" SG_ 941 ADC_HPALearningPathNum4 1;
BA_ "GatewayedSignals" SG_ 941 ADC_HPALearningPathNum4 1;
BA_ "EventCommandSignal" SG_ 941 ADC_HPALearningPathNum4 0;
BA_ "GenSigSendType" SG_ 941 ADC_HPAPathLearnRate4 1;
BA_ "GatewayedSignals" SG_ 941 ADC_HPAPathLearnRate4 1;
BA_ "EventCommandSignal" SG_ 941 ADC_HPAPathLearnRate4 0;
BA_ "GenSigSendType" SG_ 941 ADC_HPALearningPathType4 1;
BA_ "GatewayedSignals" SG_ 941 ADC_HPALearningPathType4 1;
BA_ "EventCommandSignal" SG_ 941 ADC_HPALearningPathType4 0;
BA_ "GenSigSendType" SG_ 941 ADC_HPALearningLotType4 1;
BA_ "GatewayedSignals" SG_ 941 ADC_HPALearningLotType4 1;
BA_ "EventCommandSignal" SG_ 941 ADC_HPALearningLotType4 0;
BA_ "GenSigSendType" SG_ 941 ADC_HPAPathSt4 1;
BA_ "GatewayedSignals" SG_ 941 ADC_HPAPathSt4 1;
BA_ "EventCommandSignal" SG_ 941 ADC_HPAPathSt4 0;
BA_ "GenSigSendType" SG_ 941 ADC_HPAPath4Src 1;
BA_ "GatewayedSignals" SG_ 941 ADC_HPAPath4Src 1;
BA_ "EventCommandSignal" SG_ 941 ADC_HPAPath4Src 0;
BA_ "GenSigSendType" SG_ 941 ADC_HPAPathDst4 1;
BA_ "GatewayedSignals" SG_ 941 ADC_HPAPathDst4 1;
BA_ "EventCommandSignal" SG_ 941 ADC_HPAPathDst4 0;
BA_ "GenSigSendType" SG_ 941 ADC_HPAPath3MatGpsSucces 1;
BA_ "GatewayedSignals" SG_ 941 ADC_HPAPath3MatGpsSucces 1;
BA_ "EventCommandSignal" SG_ 941 ADC_HPAPath3MatGpsSucces 0;
BA_ "GenSigSendType" SG_ 941 ADC_HPAPath4MatGpsSucces 1;
BA_ "GatewayedSignals" SG_ 941 ADC_HPAPath4MatGpsSucces 1;
BA_ "EventCommandSignal" SG_ 941 ADC_HPAPath4MatGpsSucces 0;
BA_ "GenSigSendType" SG_ 941 ADC_HPALearningPathNum5 1;
BA_ "GatewayedSignals" SG_ 941 ADC_HPALearningPathNum5 1;
BA_ "EventCommandSignal" SG_ 941 ADC_HPALearningPathNum5 0;
BA_ "GenSigSendType" SG_ 941 ADC_HPAPathLearnRate5 1;
BA_ "GatewayedSignals" SG_ 941 ADC_HPAPathLearnRate5 1;
BA_ "EventCommandSignal" SG_ 941 ADC_HPAPathLearnRate5 0;
BA_ "GenSigSendType" SG_ 941 ADC_HPALearningPathType5 1;
BA_ "GatewayedSignals" SG_ 941 ADC_HPALearningPathType5 1;
BA_ "EventCommandSignal" SG_ 941 ADC_HPALearningPathType5 0;
BA_ "GenSigSendType" SG_ 941 ADC_HPALearningLotType5 1;
BA_ "GatewayedSignals" SG_ 941 ADC_HPALearningLotType5 1;
BA_ "EventCommandSignal" SG_ 941 ADC_HPALearningLotType5 0;
BA_ "GenSigSendType" SG_ 941 ADC_HPAPathSt5 1;
BA_ "GatewayedSignals" SG_ 941 ADC_HPAPathSt5 1;
BA_ "EventCommandSignal" SG_ 941 ADC_HPAPathSt5 0;
BA_ "GenSigSendType" SG_ 941 ADC_HPAPath5Src 1;
BA_ "GatewayedSignals" SG_ 941 ADC_HPAPath5Src 1;
BA_ "EventCommandSignal" SG_ 941 ADC_HPAPath5Src 0;
BA_ "GenSigSendType" SG_ 941 ADC_HPAPathDst5 1;
BA_ "GatewayedSignals" SG_ 941 ADC_HPAPathDst5 1;
BA_ "EventCommandSignal" SG_ 941 ADC_HPAPathDst5 0;
BA_ "GenSigSendType" SG_ 941 ADC_HPALearningPathNum6 1;
BA_ "GatewayedSignals" SG_ 941 ADC_HPALearningPathNum6 1;
BA_ "EventCommandSignal" SG_ 941 ADC_HPALearningPathNum6 0;
BA_ "GenSigSendType" SG_ 941 ADC_HPAPathLearnRate6 1;
BA_ "GatewayedSignals" SG_ 941 ADC_HPAPathLearnRate6 1;
BA_ "EventCommandSignal" SG_ 941 ADC_HPAPathLearnRate6 0;
BA_ "GenSigSendType" SG_ 941 ADC_HPALearningPathType6 1;
BA_ "GatewayedSignals" SG_ 941 ADC_HPALearningPathType6 1;
BA_ "EventCommandSignal" SG_ 941 ADC_HPALearningPathType6 0;
BA_ "GenSigSendType" SG_ 941 ADC_HPALearningLotType6 1;
BA_ "GatewayedSignals" SG_ 941 ADC_HPALearningLotType6 1;
BA_ "EventCommandSignal" SG_ 941 ADC_HPALearningLotType6 0;
BA_ "GenSigSendType" SG_ 941 ADC_HPAPathSt6 1;
BA_ "GatewayedSignals" SG_ 941 ADC_HPAPathSt6 1;
BA_ "EventCommandSignal" SG_ 941 ADC_HPAPathSt6 0;
BA_ "GenSigSendType" SG_ 941 ADC_HPAPath6Src 1;
BA_ "GatewayedSignals" SG_ 941 ADC_HPAPath6Src 1;
BA_ "EventCommandSignal" SG_ 941 ADC_HPAPath6Src 0;
BA_ "GenSigSendType" SG_ 941 ADC_HPAPathDst6 1;
BA_ "GatewayedSignals" SG_ 941 ADC_HPAPathDst6 1;
BA_ "EventCommandSignal" SG_ 941 ADC_HPAPathDst6 0;
BA_ "GenSigSendType" SG_ 941 ADC_HPAPath5MatGpsSucces 1;
BA_ "GatewayedSignals" SG_ 941 ADC_HPAPath5MatGpsSucces 1;
BA_ "EventCommandSignal" SG_ 941 ADC_HPAPath5MatGpsSucces 0;
BA_ "GenSigSendType" SG_ 941 ADC_HPAPath6MatGpsSucces 1;
BA_ "GatewayedSignals" SG_ 941 ADC_HPAPath6MatGpsSucces 1;
BA_ "EventCommandSignal" SG_ 941 ADC_HPAPath6MatGpsSucces 0;
BA_ "GenSigSendType" SG_ 941 ADC_HPALearningPathNum7 1;
BA_ "GatewayedSignals" SG_ 941 ADC_HPALearningPathNum7 1;
BA_ "EventCommandSignal" SG_ 941 ADC_HPALearningPathNum7 0;
BA_ "GenSigSendType" SG_ 941 ADC_HPAPathLearnRate7 1;
BA_ "GatewayedSignals" SG_ 941 ADC_HPAPathLearnRate7 1;
BA_ "EventCommandSignal" SG_ 941 ADC_HPAPathLearnRate7 0;
BA_ "GenSigSendType" SG_ 941 ADC_HPALearningPathType7 1;
BA_ "GatewayedSignals" SG_ 941 ADC_HPALearningPathType7 1;
BA_ "EventCommandSignal" SG_ 941 ADC_HPALearningPathType7 0;
BA_ "GenSigSendType" SG_ 941 ADC_HPALearningLotType7 1;
BA_ "GatewayedSignals" SG_ 941 ADC_HPALearningLotType7 1;
BA_ "EventCommandSignal" SG_ 941 ADC_HPALearningLotType7 0;
BA_ "GenSigSendType" SG_ 941 ADC_HPAPathSt7 1;
BA_ "GatewayedSignals" SG_ 941 ADC_HPAPathSt7 1;
BA_ "EventCommandSignal" SG_ 941 ADC_HPAPathSt7 0;
BA_ "GenSigSendType" SG_ 941 ADC_HPAPath7Src 1;
BA_ "GatewayedSignals" SG_ 941 ADC_HPAPath7Src 1;
BA_ "EventCommandSignal" SG_ 941 ADC_HPAPath7Src 0;
BA_ "GenSigSendType" SG_ 941 ADC_HPAPathDst7 1;
BA_ "GatewayedSignals" SG_ 941 ADC_HPAPathDst7 1;
BA_ "EventCommandSignal" SG_ 941 ADC_HPAPathDst7 0;
BA_ "GenSigSendType" SG_ 941 ADC_HPALearningPathNum8 1;
BA_ "GatewayedSignals" SG_ 941 ADC_HPALearningPathNum8 1;
BA_ "EventCommandSignal" SG_ 941 ADC_HPALearningPathNum8 0;
BA_ "GenSigSendType" SG_ 941 ADC_HPAPathLearnRate8 1;
BA_ "GatewayedSignals" SG_ 941 ADC_HPAPathLearnRate8 1;
BA_ "EventCommandSignal" SG_ 941 ADC_HPAPathLearnRate8 0;
BA_ "GenSigSendType" SG_ 941 ADC_HPALearningPathType8 1;
BA_ "GatewayedSignals" SG_ 941 ADC_HPALearningPathType8 1;
BA_ "EventCommandSignal" SG_ 941 ADC_HPALearningPathType8 0;
BA_ "GenSigSendType" SG_ 941 ADC_HPALearningLotType8 1;
BA_ "GatewayedSignals" SG_ 941 ADC_HPALearningLotType8 1;
BA_ "EventCommandSignal" SG_ 941 ADC_HPALearningLotType8 0;
BA_ "GenSigSendType" SG_ 941 ADC_HPAPPathSt8 1;
BA_ "GatewayedSignals" SG_ 941 ADC_HPAPPathSt8 1;
BA_ "EventCommandSignal" SG_ 941 ADC_HPAPPathSt8 0;
BA_ "GenSigSendType" SG_ 941 ADC_HPAPath8Src 1;
BA_ "GatewayedSignals" SG_ 941 ADC_HPAPath8Src 1;
BA_ "EventCommandSignal" SG_ 941 ADC_HPAPath8Src 0;
BA_ "GenSigSendType" SG_ 941 ADC_HPAPathDst8 1;
BA_ "GatewayedSignals" SG_ 941 ADC_HPAPathDst8 1;
BA_ "EventCommandSignal" SG_ 941 ADC_HPAPathDst8 0;
BA_ "GenSigSendType" SG_ 941 ADC_HPAPath7MatGpsSucces 1;
BA_ "GatewayedSignals" SG_ 941 ADC_HPAPath7MatGpsSucces 1;
BA_ "EventCommandSignal" SG_ 941 ADC_HPAPath7MatGpsSucces 0;
BA_ "GenSigSendType" SG_ 941 ADC_HPAPath8MatGpsSucces 1;
BA_ "GatewayedSignals" SG_ 941 ADC_HPAPath8MatGpsSucces 1;
BA_ "EventCommandSignal" SG_ 941 ADC_HPAPath8MatGpsSucces 0;
BA_ "GenSigSendType" SG_ 941 ADC_HPALearningPathNum9 1;
BA_ "GatewayedSignals" SG_ 941 ADC_HPALearningPathNum9 1;
BA_ "EventCommandSignal" SG_ 941 ADC_HPALearningPathNum9 0;
BA_ "GenSigSendType" SG_ 941 ADC_HPAPathLearnRate9 1;
BA_ "GatewayedSignals" SG_ 941 ADC_HPAPathLearnRate9 1;
BA_ "EventCommandSignal" SG_ 941 ADC_HPAPathLearnRate9 0;
BA_ "GenSigSendType" SG_ 941 ADC_HPALearningPathType9 1;
BA_ "GatewayedSignals" SG_ 941 ADC_HPALearningPathType9 1;
BA_ "EventCommandSignal" SG_ 941 ADC_HPALearningPathType9 0;
BA_ "GenSigSendType" SG_ 941 ADC_HPALearningLotType9 1;
BA_ "GatewayedSignals" SG_ 941 ADC_HPALearningLotType9 1;
BA_ "EventCommandSignal" SG_ 941 ADC_HPALearningLotType9 0;
BA_ "GenSigSendType" SG_ 941 ADC_HPAPathSt9 1;
BA_ "GatewayedSignals" SG_ 941 ADC_HPAPathSt9 1;
BA_ "EventCommandSignal" SG_ 941 ADC_HPAPathSt9 0;
BA_ "GenSigSendType" SG_ 941 ADC_HPAPath9Src 1;
BA_ "GatewayedSignals" SG_ 941 ADC_HPAPath9Src 1;
BA_ "EventCommandSignal" SG_ 941 ADC_HPAPath9Src 0;
BA_ "GenSigSendType" SG_ 941 ADC_HPAPathDst9 1;
BA_ "GatewayedSignals" SG_ 941 ADC_HPAPathDst9 1;
BA_ "EventCommandSignal" SG_ 941 ADC_HPAPathDst9 0;
BA_ "GenSigSendType" SG_ 941 ADC_HPALearningPathNum10 1;
BA_ "GatewayedSignals" SG_ 941 ADC_HPALearningPathNum10 1;
BA_ "EventCommandSignal" SG_ 941 ADC_HPALearningPathNum10 0;
BA_ "GenSigSendType" SG_ 941 ADC_HPAPathLearnRate10 1;
BA_ "GatewayedSignals" SG_ 941 ADC_HPAPathLearnRate10 1;
BA_ "EventCommandSignal" SG_ 941 ADC_HPAPathLearnRate10 0;
BA_ "GenSigSendType" SG_ 941 ADC_HPALearningPathType10 1;
BA_ "GatewayedSignals" SG_ 941 ADC_HPALearningPathType10 1;
BA_ "EventCommandSignal" SG_ 941 ADC_HPALearningPathType10 0;
BA_ "GenSigSendType" SG_ 941 ADC_HPALearningLotType10 1;
BA_ "GatewayedSignals" SG_ 941 ADC_HPALearningLotType10 1;
BA_ "EventCommandSignal" SG_ 941 ADC_HPALearningLotType10 0;
BA_ "GenSigSendType" SG_ 941 ADC_HPAPathSt10 1;
BA_ "GatewayedSignals" SG_ 941 ADC_HPAPathSt10 1;
BA_ "EventCommandSignal" SG_ 941 ADC_HPAPathSt10 0;
BA_ "GenSigSendType" SG_ 941 ADC_HPAPath10Src 1;
BA_ "GatewayedSignals" SG_ 941 ADC_HPAPath10Src 1;
BA_ "EventCommandSignal" SG_ 941 ADC_HPAPath10Src 0;
BA_ "GenSigSendType" SG_ 941 ADC_HPAPathDst10 1;
BA_ "GatewayedSignals" SG_ 941 ADC_HPAPathDst10 1;
BA_ "EventCommandSignal" SG_ 941 ADC_HPAPathDst10 0;
BA_ "GenSigSendType" SG_ 941 ADC_HPAPath9MatGpsSucces 1;
BA_ "GatewayedSignals" SG_ 941 ADC_HPAPath9MatGpsSucces 1;
BA_ "EventCommandSignal" SG_ 941 ADC_HPAPath9MatGpsSucces 0;
BA_ "GenSigSendType" SG_ 941 ADC_HPAPath10MatGpsSucces 1;
BA_ "GatewayedSignals" SG_ 941 ADC_HPAPath10MatGpsSucces 1;
BA_ "EventCommandSignal" SG_ 941 ADC_HPAPath10MatGpsSucces 0;
BA_ "GenSigSendType" SG_ 835 OMS_SysErrSt_ADC 1;
BA_ "GatewayedSignals" SG_ 835 OMS_SysErrSt_ADC 0;
BA_ "EventCommandSignal" SG_ 835 OMS_SysErrSt_ADC 0;
BA_ "GenSigSendType" SG_ 835 DMS_SysErrSt_ADC 1;
BA_ "GatewayedSignals" SG_ 835 DMS_SysErrSt_ADC 0;
BA_ "EventCommandSignal" SG_ 835 DMS_SysErrSt_ADC 0;
BA_ "GenSigSendType" SG_ 835 DMS_FaceID_ADC 1;
BA_ "GatewayedSignals" SG_ 835 DMS_FaceID_ADC 0;
BA_ "EventCommandSignal" SG_ 835 DMS_FaceID_ADC 0;
BA_ "GenSigSendType" SG_ 835 PAS_SystemType 1;
BA_ "EventCommandSignal" SG_ 835 PAS_SystemType 0;
BA_ "GenSigSendType" SG_ 835 PAS_WarnTone 1;
BA_ "EventCommandSignal" SG_ 835 PAS_WarnTone 0;
BA_ "GenSigSendType" SG_ 835 PAS_ButtonPress 1;
BA_ "EventCommandSignal" SG_ 835 PAS_ButtonPress 0;
BA_ "GenSigSendType" SG_ 835 PAS_SideZoneStatusF 1;
BA_ "EventCommandSignal" SG_ 835 PAS_SideZoneStatusF 0;
BA_ "GenSigSendType" SG_ 835 PAS_SideZoneStatusR 1;
BA_ "EventCommandSignal" SG_ 835 PAS_SideZoneStatusR 0;
BA_ "GenSigSendType" SG_ 835 PAS_RRMidDistance 1;
BA_ "EventCommandSignal" SG_ 835 PAS_RRMidDistance 0;
BA_ "GenSigTimeoutValue" SG_ 835 PAS_RRMidDistance 255;
BA_ "EventCommandSignal" SG_ 549 ADC_RAEBWorkSts 0;
BA_ "GatewayedSignals" SG_ 549 ADC_RAEBWorkSts 0;
BA_ "GenSigSendType" SG_ 549 ADC_RAEBWorkSts 1;
BA_ "EventCommandSignal" SG_ 549 ADC_PAARecInd 0;
BA_ "GatewayedSignals" SG_ 549 ADC_PAARecInd 0;
BA_ "GenSigSendType" SG_ 549 ADC_PAARecInd 1;
BA_ "EventCommandSignal" SG_ 549 ADC_PAAQuitInd 0;
BA_ "GatewayedSignals" SG_ 549 ADC_PAAQuitInd 0;
BA_ "GenSigSendType" SG_ 549 ADC_PAAQuitInd 1;
BA_ "EventCommandSignal" SG_ 549 ADC_PAADrvReq 0;
BA_ "GatewayedSignals" SG_ 549 ADC_PAADrvReq 0;
BA_ "GenSigSendType" SG_ 549 ADC_PAADrvReq 1;
BA_ "EventCommandSignal" SG_ 549 ADC_SBMAuthst 0;
BA_ "GatewayedSignals" SG_ 549 ADC_SBMAuthst 0;
BA_ "GenSigSendType" SG_ 549 ADC_SBMAuthst 0;
VAL_ 615 BCS_FLWheelSpdEdgesSumVD 1 "Valid" 0 "Not valid" ;
SIG_GROUP_ 615 BCS_1_C_E2E 1 : BCS_RLWheelSpd BCS_RLWheelRotatedDirection BCS_1_C_Dummy19 BCS_1_C_Dummy20 BCS_FLWheelSpd BCS_FLWheelRotatedDirection BCS_FRWheelSpd BCS_FRWheelRotatedDirection BCS_RRWheelSpd BCS_RRWheelRotatedDirection BCS_FRWheelSpdEdgesSum BCS_RRWheelSpdEdgesSum BCS_1_C_Dummy17 BCS_1_C_Dummy18 BCS_1_C_Dummy14 BCS_1_C_Dummy16 BCS_1_C_Dummy10 BCS_1_C_Dummy15 BCS_HDCFuncResp BCS_ESPFuncResp BCS_AVHAvailable BCS_AVHStandby BCS_RLWheelSpdEdgesSumVD BCS_RLWheelSpdEdgesSum BCS_HDCErrSt BCS_HDCCtrlSt BCS_HHCErrSt BCS_FLWheelSpdEdgesSum BCS_FLWheelSpdEdgesSumVD BCS_1_C_Dummy2 BCS_1_C_Dummy3 BCS_1_C_Dummy4 BCS_1_C_Dummy5 BCS_1_C_Dummy6 BCS_1_C_Dummy7 BCS_1_C_Dummy8 BCS_1_C_Dummy9 BCS_1_C_Dummy11 BCS_1_C_Dummy12 BCS_1_C_Dummy13 BCS_AVHSt BCS_TCSOff BCS_VDCOff BCS_1_CRC BCS_1_Counter;
SIG_GROUP_ 352 BCS_2_C_E2E 1 : IPB_BrakePedalSt BCS_2_C_Dummy11 BCS_2_C_Dummy10 BCS_2_C_Dummy9 BCS_2_C_Dummy8 BCS_2_C_Dummy7 BCS_2_C_Dummy6 BCS_2_C_Dummy5 BCS_2_C_Dummy4 BCS_2_C_Dummy3 BCS_2_C_Dummy2 BCS_VehSpd BCS_VehSpdVD BCS_TCSActiveSt BCS_VDCActiveSt BCS_TCSFaultSt BCS_VDCFaultSt BCS_ABSFaultSt BCS_EBDFaultSt BCS_2_CRC BCS_2_Counter;
SIG_GROUP_ 611 BCS_3_C_E2E 1 : IPB_BrkPedalModesetSt BCS_ESPMode IBCS_TwoFoot_DriveWarning IPB_CSTSt IPB_InputRodStrokeSt IPB_BrkPedalModeCfgSt BCS_3_C_Dummy10 BCS_3_C_Dummy9 BCS_3_C_Dummy8 BCS_3_C_Dummy7 BCS_3_C_Dummy6 BCS_3_C_Dummy5 BCS_3_C_Dummy4 BCS_3_C_Dummy3 BCS_3_C_Dummy2 IBCS_BrakeFluidWarning IBCS_FWAWarning IBCS_SystemSt BCS_3_Counter BCS_3_CRC;
SIG_GROUP_ 618 EPB_1_E2E 1 : EPB_DragMode EPB_1_Dummy6 EPB_1_Dummy5 EPB_1_Dummy4 EPB_1_Dummy3 EPB_1_Dummy2 EPB_1_Dummy1 EPB_SysSt EPB_SysAudWarnReq EPB_SysDispMsgReq EPB_StpOnBrkToRelParkBrkIndOn EPB_SysWarnIndReq EPB_FailSt EPB_SysStIndReq EPB_1_Counter EPB_1_CRC;
SIG_GROUP_ 939 SRS_2_E2E 1 : SRS_2_Dummy5 SRS_2_Dummy4 SRS_2_Dummy3 SRS_2_Dummy2 SRS_2_Dummy1 SRS_PsngrSeatBeltSt SRS_DriverSeatBeltSt SRS_RearLeftSeatBeltSt SRS_RearRightSeatBeltSt SRS_RearMiddleSeatBeltSt SRS_AirbagFaultSt SRS_2_CRC SRS_2_Counter;
SIG_GROUP_ 864 DCU_2_E2E 1 : DCU_SysTempOvrInd DCU_2_Dummy10 DCU_FaultLampInd DCU_ErrNoticeOperationFlag DCU_Err2NoticeFlag DCU_2_Dummy2 DCU_2_Dummy3 DCU_2_Dummy4 DCU_2_Dummy5 DCU_2_Dummy6 DCU_2_Dummy7 DCU_2_Dummy8 DCU_2_Dummy9 DCU_ErrNotice DCU_2_Counter DCU_2_CRC;
SIG_GROUP_ 872 IPS_2_E2E 1 : IPS_2_Dummy10 IPS_2_Dummy9 IPS_2_Dummy8 IPS_2_Dummy7 IPS_2_Dummy6 IPS_2_Dummy5 IPS_2_Dummy4 IPS_2_Dummy3 IPS_2_Dummy2 IPS_OBCFaultLampIndOperationFlag IPS_DCDCFaultLampIndFlag IPS_DCDCFaultLampIndOperationFla IPS_OBCFaultLampInd IPS_2_CRC IPS_2_Counter IPS_DCDCFaultLampInd;
SIG_GROUP_ 824 VCU_2_E2E 1 : VCU_2_Dummy32 VCU_HVAC_PTCdelayEn VCU_VehPwr VCU_BattSocUndrWarn VCU_IpedalCreepCfgResp VCU_VehRng VCU_VehRngUndrWarn VCU_RecpLevelstResp VCU_IDC_VehSwapModAvai VCU_IDC_VehSwapModResp VCU_IDC_VehSwapModReq VCU_IDC_VehSwapModIntf VCU_ChgPlugRelSt VCU_DischgSetInfo VCU_VehPwrDisp VCU_DerateLampSt VCU_VehAvailDriveStMsgWarn VCU_ThermalMsgWarn VCU_ChgTimeDspType VCU_VehChgDischgSt VCU_PrecResHotMsg VCU_VehCrusTgtSpd VCU_ICMSpdLimitNotice VCU_VehRdySt VCU_BuzReq VCU_ARBWarnNotice VCU_VehDrvMod VCU_FaultLampInd VCU_PwrFlowMode VCU_VehCrusSt VCU_PGearErrNotice VCU_EcoModeAvail VCU_VehElcConspAccumAvg VCU_VehElcConspAvg VCU_DischgSocResp VCU_DischgEndVehRng VCU_CruExitNotice VCU_DrvChgDchgDsp VCU_DriverNoticeDisp VCU_DspDischgCurr VCU_EcoPlusModeAvail VCU_DspDischgVolt VCU_DspChgCurr VCU_BookChgLampInd VCU_DspChgVolt VCU_SOCDynamicDspSt VCU_DspDischgSt VCU_DspChgSt VCU_ElcSysFault VCU_IpedalModeAvail VCU_RecpLevelAvail VCU_CreepAvail VCU_WarmSt VCU_WarmTimeCfgResp VCU_DischgAvai VCU_DischgSt VCU_VehElcConspInst VCU_WarmTimeNotice VCU_SwapHvBattModeSt VCU_SwapHvBattModeStVD VCU_LongDistResp VCU_2_Dummy2 VCU_2_Dummy3 VCU_2_Dummy4 VCU_2_Dummy5 VCU_2_Dummy6 VCU_2_Dummy7 VCU_2_Dummy8 VCU_2_Dummy9 VCU_2_Dummy10 VCU_2_Dummy11 VCU_2_Dummy31 VCU_2_Dummy12 VCU_2_Dummy13 VCU_2_Dummy14 VCU_2_Dummy15 VCU_2_Dummy16 VCU_2_Dummy17 VCU_2_Dummy18 VCU_2_Dummy19 VCU_2_Dummy20 VCU_2_Dummy21 VCU_2_Dummy22 VCU_2_Dummy23 VCU_2_Dummy24 VCU_2_Dummy25 VCU_2_Dummy26 VCU_2_Dummy27 VCU_2_Dummy28 VCU_2_Dummy29 VCU_2_Dummy30 VCU_GearLvlBlink VCU_PlgConnSt VCU_2_Counter VCU_GearLvlDisp VCU_2_CRC;
SIG_GROUP_ 952 VCU_3_E2E 1 : VCU_AccurRngAvail VCU_AccurHMIModeCmd VCU_AccurRngConspAccumAvg VCU_EcoPlusMod VCU_ChgButtonStDsp VCU_3_Dummy14 VCU_RecpLevelstRespL VCU_3_Dummy13 VCU_3_Dummy12 VCU_EMS_AccPedalActPst_Disp VCU_BattCapColorEff VCU_HVAPUTotalPwrAct VCU_ThermalMsgWarnOperationFlag VCU_ErrNoticeOperationFlag VCU_Err2NoticeFlag VCU_AccPdlLvlResp VCU_DspChgCurrKA VCU_AccurRngCmd VCU_3_Dummy2 VCU_3_Dummy3 VCU_3_Dummy5 VCU_3_Dummy6 VCU_3_Dummy7 VCU_3_Dummy8 VCU_3_Dummy9 VCU_3_Dummy10 VCU_3_Dummy11 VCU_ErrNotice VCU_3_Counter VCU_3_CRC;
SIG_GROUP_ 403 ADC_1_E2E 1 : ADC_ICMADASFailureLamp ADC_ACCIconColor ADC_ACCTargetSpeedCard ADC_ICANDAIconAngle ADC_SpeedLimitIcon ADC_NDAStateIcon ADC_ACUVoiceWarn ADC_NDAIconColor ADC_ICMPromptWarn ADC_ICMWarnCardSt ADC_SpeedLimitIconSt ADC_ICMADASWarnText ADC_ICMADASFailureText ADC_ILOA_EnableSt ADC_ILC_EnableSt ADC_TimeGapSet ADC_ISLCSt ADC_ACCTakeOverReq ADC_ISLC_ConfirmSt ADC_ACCMode ADC_HFIconColor ADC_1_Dummy2 ADC_1_Dummy3 ADC_1_Dummy4 ADC_1_Dummy5 ADC_1_Dummy6 ADC_1_Dummy7 ADC_1_Dummy8 ADC_1_Dummy9 ADC_1_Dummy10 ADC_1_Dummy11 ADC_ICAIconColor ADC_1_Counter ADC_1_CRC;
SIG_GROUP_ 437 CCU_IFC_1_E2E 1 : CCU_IFC_1_Dummy1 CCU_IFC_1_Dummy2 CCU_IFC_1_Dummy4 CCU_IFC_1_Dummy3 CCU_IFC_1_Dummy5 CCU_IFC_1_Dummy6 CCU_IFC_1_Dummy7 CCU_IFC_1_Dummy8 CCU_IFC_1_Dummy9 CCU_IFC_1_Dummy10 CCU_IFC_1_Dummy11 IFC_1_CRC IFC_1_Counter IFC_ICMWarnCardSt IFC_ICMPromptWarn;
